VERSION "2021.24.4"

NS_ :

BS_:

BU_: VEH CH Receiver X

BO_ 864 VCLEFT_alertMatrix: 8 VEH
 SG_ VCLEFT_matrixIndex M: 0|4@1+ (1,0) [0|0] "" X
 SG_ VCLEFT_a001_WatchdogReset m0: 4|1@1+ (1,0) [0|0] "" X
 SG_ VCLEFT_a002_PowerLossReset m0: 5|1@1+ (1,0) [0|0] "" X
 SG_ VCLEFT_a003_SWAssertion m0: 6|1@1+ (1,0) [0|0] "" X
 SG_ VCLEFT_a010_ExtSupplyVoltError m0: 13|1@1+ (1,0) [0|0] "" X
 SG_ VCLEFT_a012_CPUReset m0: 15|1@1+ (1,0) [0|0] "" X
 SG_ VCLEFT_a013_AlertManagerFault m0: 16|1@1+ (1,0) [0|0] "" X
 SG_ VCLEFT_a015_NVMMAlert m0: 18|1@1+ (1,0) [0|0] "" X
 SG_ VCLEFT_a021_TaskSchedulerError m0: 24|1@1+ (1,0) [0|0] "" X
 SG_ VCLEFT_a022_TaskInitError m0: 25|1@1+ (1,0) [0|0] "" X
 SG_ VCLEFT_a031_UDSActive m0: 34|1@1+ (1,0) [0|0] "" X
 SG_ VCLEFT_a041_HighCPULoad m0: 44|1@1+ (1,0) [0|0] "" X
 SG_ VCLEFT_a042_HighStackUsage m0: 45|1@1+ (1,0) [0|0] "" X
 SG_ VCLEFT_a043_Task1msError m0: 46|1@1+ (1,0) [0|0] "" X
 SG_ VCLEFT_a044_Task10msError m0: 47|1@1+ (1,0) [0|0] "" X
 SG_ VCLEFT_a045_Task100msError m0: 48|1@1+ (1,0) [0|0] "" X
 SG_ VCLEFT_a046_Task1000msError m0: 49|1@1+ (1,0) [0|0] "" X
 SG_ VCLEFT_a059_inputResistanceHigh m0: 62|1@1+ (1,0) [0|0] "" X
 SG_ VCLEFT_a060_engineeringBuild m0: 63|1@1+ (1,0) [0|0] "" X
 SG_ VCLEFT_a061_XCPConnected m1: 4|1@1+ (1,0) [0|0] "" X
 SG_ VCLEFT_a062_XCPWasConnected m1: 5|1@1+ (1,0) [0|0] "" X
 SG_ VCLEFT_a063_SwitchFault m1: 6|1@1+ (1,0) [0|0] "" X
 SG_ VCLEFT_a064_busSleepReqTimeout m1: 7|1@1+ (1,0) [0|0] "" X
 SG_ VCLEFT_a097_CMP_MIA m1: 40|1@1+ (1,0) [0|0] "" X
 SG_ VCLEFT_a098_DI_THERMAL_MIA m1: 41|1@1+ (1,0) [0|0] "" X
 SG_ VCLEFT_a099_PARK_MIA m1: 42|1@1+ (1,0) [0|0] "" X
 SG_ VCLEFT_a100_CANbus_MIA m1: 43|1@1+ (1,0) [0|0] "" X
 SG_ VCLEFT_a101_PM_MIA m1: 44|1@1+ (1,0) [0|0] "" X
 SG_ VCLEFT_a102_PTC_MIA m1: 45|1@1+ (1,0) [0|0] "" X
 SG_ VCLEFT_a103_CP_MIA m1: 46|1@1+ (1,0) [0|0] "" X
 SG_ VCLEFT_a104_DAS_MIA m1: 47|1@1+ (1,0) [0|0] "" X
 SG_ VCLEFT_a105_TAS_MIA m1: 48|1@1+ (1,0) [0|0] "" X
 SG_ VCLEFT_a106_PCS_MIA m1: 49|1@1+ (1,0) [0|0] "" X
 SG_ VCLEFT_a107_BMS_MIA m1: 50|1@1+ (1,0) [0|0] "" X
 SG_ VCLEFT_a108_DIS_MIA m1: 51|1@1+ (1,0) [0|0] "" X
 SG_ VCLEFT_a109_RCM_MIA m1: 52|1@1+ (1,0) [0|0] "" X
 SG_ VCLEFT_a110_GTW_MIA m1: 53|1@1+ (1,0) [0|0] "" X
 SG_ VCLEFT_a111_EPBR_MIA m1: 54|1@1+ (1,0) [0|0] "" X
 SG_ VCLEFT_a112_EPBL_MIA m1: 55|1@1+ (1,0) [0|0] "" X
 SG_ VCLEFT_a113_UI_MIA m1: 56|1@1+ (1,0) [0|0] "" X
 SG_ VCLEFT_a114_ESP_MIA m1: 57|1@1+ (1,0) [0|0] "" X
 SG_ VCLEFT_a115_VCSEC_MIA m1: 58|1@1+ (1,0) [0|0] "" X
 SG_ VCLEFT_a116_VCRIGHT_MIA m1: 59|1@1+ (1,0) [0|0] "" X
 SG_ VCLEFT_a117_VCLEFT_MIA m1: 60|1@1+ (1,0) [0|0] "" X
 SG_ VCLEFT_a118_VCFRONT_MIA m1: 61|1@1+ (1,0) [0|0] "" X
 SG_ VCLEFT_a119_SCCM_MIA m1: 62|1@1+ (1,0) [0|0] "" X
 SG_ VCLEFT_a120_DI_DRIVE_MIA m1: 63|1@1+ (1,0) [0|0] "" X
 SG_ VCLEFT_a129_blowerICLatchFault m2: 12|1@1+ (1,0) [0|0] "" X
 SG_ VCLEFT_a130_blowerICWarning m2: 13|1@1+ (1,0) [0|0] "" X
 SG_ VCLEFT_a131_blowerICTransFault m2: 14|1@1+ (1,0) [0|0] "" X
 SG_ VCLEFT_a132_blowerSoftStall m2: 15|1@1+ (1,0) [0|0] "" X
 SG_ VCLEFT_a133_blowerLowRPMCBang m2: 16|1@1+ (1,0) [0|0] "" X
 SG_ VCLEFT_a134_SteerColUpDownUnCal m2: 17|1@1+ (1,0) [0|0] "" X
 SG_ VCLEFT_a135_SteerColInOutUnCal m2: 18|1@1+ (1,0) [0|0] "" X
 SG_ VCLEFT_a136_brakeSwitchMismatch m2: 19|1@1+ (1,0) [0|0] "" X
 SG_ VCLEFT_a137_VCSECPowerCycled m2: 20|1@1+ (1,0) [0|0] "" X
 SG_ VCLEFT_a138_consoleDoorAssist m2: 21|1@1+ (1,0) [0|0] "" X
 SG_ VCLEFT_a139_BLERearPowerCycled m2: 22|1@1+ (1,0) [0|0] "" X
 SG_ VCLEFT_a140_BLELeftPowerCycled m2: 23|1@1+ (1,0) [0|0] "" X
 SG_ VCLEFT_a141_12VAuxPowerTrip m2: 24|1@1+ (1,0) [0|0] "" X
 SG_ VCLEFT_a150_windowPinchFront m2: 33|1@1+ (1,0) [0|0] "" X
 SG_ VCLEFT_a151_windowPinchRear m2: 34|1@1+ (1,0) [0|0] "" X
 SG_ VCLEFT_a152_windowUncalFront m2: 35|1@1+ (1,0) [0|0] "" X
 SG_ VCLEFT_a153_windowUncalRear m2: 36|1@1+ (1,0) [0|0] "" X
 SG_ VCLEFT_a154_windowThermalFront m2: 37|1@1+ (1,0) [0|0] "" X
 SG_ VCLEFT_a155_windowThermalRear m2: 38|1@1+ (1,0) [0|0] "" X
 SG_ VCLEFT_a156_windowNoInputFront m2: 39|1@1+ (1,0) [0|0] "" X
 SG_ VCLEFT_a157_windowNoInputRear m2: 40|1@1+ (1,0) [0|0] "" X
 SG_ VCLEFT_a158_windowPinchOverideF m2: 41|1@1+ (1,0) [0|0] "" X
 SG_ VCLEFT_a159_windowPinchOverideR m2: 42|1@1+ (1,0) [0|0] "" X
 SG_ VCLEFT_a160_windowUndercurrentF m2: 43|1@1+ (1,0) [0|0] "" X
 SG_ VCLEFT_a161_windowUndercurrentR m2: 44|1@1+ (1,0) [0|0] "" X
 SG_ VCLEFT_a162_windowEncoderStallF m2: 45|1@1+ (1,0) [0|0] "" X
 SG_ VCLEFT_a163_windowEncoderStallR m2: 46|1@1+ (1,0) [0|0] "" X
 SG_ VCLEFT_a164_windowFactoryTest m2: 47|1@1+ (1,0) [0|0] "" X
 SG_ VCLEFT_a165_windowFactoryTest2 m2: 48|1@1+ (1,0) [0|0] "" X
 SG_ VCLEFT_a166_windowDebug m2: 49|1@1+ (1,0) [0|0] "" X
 SG_ VCLEFT_a167_windowDebugPinchF m2: 50|1@1+ (1,0) [0|0] "" X
 SG_ VCLEFT_a168_windowDebugPinchR m2: 51|1@1+ (1,0) [0|0] "" X
 SG_ VCLEFT_a169_windowCurrentPeakF m2: 52|1@1+ (1,0) [0|0] "" X
 SG_ VCLEFT_a170_windowCurrentPeakR m2: 53|1@1+ (1,0) [0|0] "" X
 SG_ VCLEFT_a172_SPI_MIA m2: 55|1@1+ (1,0) [0|0] "" X
 SG_ VCLEFT_a180_frontDoorLatchRehome m2: 63|1@1+ (1,0) [0|0] "" X
 SG_ VCLEFT_a181_rearDoorLatchRehome m3: 4|1@1+ (1,0) [0|0] "" X
 SG_ VCLEFT_a182_emergencyLatchRel m3: 5|1@1+ (1,0) [0|0] "" X
 SG_ VCLEFT_a183_doorStateFactoryTest m3: 6|1@1+ (1,0) [0|0] "" X
 SG_ VCLEFT_a185_summonAborted m3: 8|1@1+ (1,0) [0|0] "" X
 SG_ VCLEFT_a186_latchReleaseFailedF m3: 9|1@1+ (1,0) [0|0] "" X
 SG_ VCLEFT_a187_latchReleaseFailedR m3: 10|1@1+ (1,0) [0|0] "" X
 SG_ VCLEFT_a188_latchUnableToRearmF m3: 11|1@1+ (1,0) [0|0] "" X
 SG_ VCLEFT_a189_latchUnableToRearmR m3: 12|1@1+ (1,0) [0|0] "" X
 SG_ VCLEFT_a190_eFuseMgmtVbatFused m3: 13|1@1+ (1,0) [0|0] "" X
 SG_ VCLEFT_a191_TLCOvercurrent m3: 14|1@1+ (1,0) [0|0] "" X
 SG_ VCLEFT_a196_VEHCANOverterminate m3: 19|1@1+ (1,0) [0|0] "" X
 SG_ VCLEFT_a197_VEHCANUndertrminate m3: 20|1@1+ (1,0) [0|0] "" X
 SG_ VCLEFT_a200_motorPhantomEncoder m3: 23|1@1+ (1,0) [0|0] "" X
 SG_ VCLEFT_a201_motorDutyEncDisabl m3: 24|1@1+ (1,0) [0|0] "" X
 SG_ VCLEFT_a202_epbmUnderIStatic m3: 25|1@1+ (1,0) [0|0] "" X
 SG_ VCLEFT_a203_epbmOverIStatic m3: 26|1@1+ (1,0) [0|0] "" X
 SG_ VCLEFT_a204_epbmUnderIDyn m3: 27|1@1+ (1,0) [0|0] "" X
 SG_ VCLEFT_a205_epbmOverIDyn m3: 28|1@1+ (1,0) [0|0] "" X
 SG_ VCLEFT_a206_epbWrongDirection m3: 29|1@1+ (1,0) [0|0] "" X
 SG_ VCLEFT_a207_epbmEnableWrong m3: 30|1@1+ (1,0) [0|0] "" X
 SG_ VCLEFT_a208_epbFaulted m3: 31|1@1+ (1,0) [0|0] "" X
 SG_ VCLEFT_a209_epbStateMisTime m3: 32|1@1+ (1,0) [0|0] "" X
 SG_ VCLEFT_a210_epbStateTime m3: 33|1@1+ (1,0) [0|0] "" X
 SG_ VCLEFT_a211_epbmUnderIStaticNew m3: 34|1@1+ (1,0) [0|0] "" X
 SG_ VCLEFT_a212_epbmOverIStaticNew m3: 35|1@1+ (1,0) [0|0] "" X
 SG_ VCLEFT_a213_epbmUnderIDynNew m3: 36|1@1+ (1,0) [0|0] "" X
 SG_ VCLEFT_a214_epbmOverIDynNew m3: 37|1@1+ (1,0) [0|0] "" X
 SG_ VCLEFT_a215_currentDesyncWarning m3: 38|1@1+ (1,0) [0|0] "" X
 SG_ VCLEFT_a216_SPI_MIA_debugData1 m3: 39|1@1+ (1,0) [0|0] "" X
 SG_ VCLEFT_a217_SPI_MIA_debugData2 m3: 40|1@1+ (1,0) [0|0] "" X
 SG_ VCLEFT_a218_motorDriverFault m3: 41|1@1+ (1,0) [0|0] "" X
 SG_ VCLEFT_a219_motorCurrentDropout m3: 42|1@1+ (1,0) [0|0] "" X
 SG_ VCLEFT_a220_seatCurrStallTrack m3: 43|1@1+ (1,0) [0|0] "" X
 SG_ VCLEFT_a221_seatCurrStallBack m3: 44|1@1+ (1,0) [0|0] "" X
 SG_ VCLEFT_a222_seatCurrStallTilt m3: 45|1@1+ (1,0) [0|0] "" X
 SG_ VCLEFT_a223_seatCurrStallLift m3: 46|1@1+ (1,0) [0|0] "" X
 SG_ VCLEFT_a224_seatEncStallTrack m3: 47|1@1+ (1,0) [0|0] "" X
 SG_ VCLEFT_a225_seatEncStallBack m3: 48|1@1+ (1,0) [0|0] "" X
 SG_ VCLEFT_a226_seatEncStallTilt m3: 49|1@1+ (1,0) [0|0] "" X
 SG_ VCLEFT_a227_seatEncStallLift m3: 50|1@1+ (1,0) [0|0] "" X
 SG_ VCLEFT_a228_seatEncOverTrack m3: 51|1@1+ (1,0) [0|0] "" X
 SG_ VCLEFT_a229_seatEncOverBack m3: 52|1@1+ (1,0) [0|0] "" X
 SG_ VCLEFT_a230_seatEncOverTilt m3: 53|1@1+ (1,0) [0|0] "" X
 SG_ VCLEFT_a231_seatEncOverLift m3: 54|1@1+ (1,0) [0|0] "" X
 SG_ VCLEFT_a232_seatCurrUnderTrack m3: 55|1@1+ (1,0) [0|0] "" X
 SG_ VCLEFT_a233_seatCurrUnderBack m3: 56|1@1+ (1,0) [0|0] "" X
 SG_ VCLEFT_a234_seatCurrUnderTilt m3: 57|1@1+ (1,0) [0|0] "" X
 SG_ VCLEFT_a235_seatCurrUnderLift m3: 58|1@1+ (1,0) [0|0] "" X
 SG_ VCLEFT_a236_lumbarOverPresA m3: 59|1@1+ (1,0) [0|0] "" X
 SG_ VCLEFT_a237_lumbarOverPresB m3: 60|1@1+ (1,0) [0|0] "" X
 SG_ VCLEFT_a238_lumbarValveMIA m3: 61|1@1+ (1,0) [0|0] "" X
 SG_ VCLEFT_a239_seatHeatIFront m3: 62|1@1+ (1,0) [0|0] "" X
 SG_ VCLEFT_a240_seatHeatShortFront m3: 63|1@1+ (1,0) [0|0] "" X
 SG_ VCLEFT_a241_seatHeatMIAFront m4: 4|1@1+ (1,0) [0|0] "" X
 SG_ VCLEFT_a242_seatHeatIRearL m4: 5|1@1+ (1,0) [0|0] "" X
 SG_ VCLEFT_a243_seatHeatShortRearL m4: 6|1@1+ (1,0) [0|0] "" X
 SG_ VCLEFT_a244_seatHeatMIARearL m4: 7|1@1+ (1,0) [0|0] "" X
 SG_ VCLEFT_a251_seatUncalTrack m4: 14|1@1+ (1,0) [0|0] "" X
 SG_ VCLEFT_a252_seatUncalBack m4: 15|1@1+ (1,0) [0|0] "" X
 SG_ VCLEFT_a253_seatUncalTilt m4: 16|1@1+ (1,0) [0|0] "" X
 SG_ VCLEFT_a254_seatUncalLift m4: 17|1@1+ (1,0) [0|0] "" X
 SG_ VCLEFT_a259_latchDisarmDelayF m4: 22|1@1+ (1,0) [0|0] "" X
 SG_ VCLEFT_a260_latchDisarmDelayR m4: 23|1@1+ (1,0) [0|0] "" X
 SG_ VCLEFT_a263_seatTrackStallDebug m4: 26|1@1+ (1,0) [0|0] "" X
 SG_ VCLEFT_a264_seatBackStallDebug m4: 27|1@1+ (1,0) [0|0] "" X
 SG_ VCLEFT_a265_seatTiltStallDebug m4: 28|1@1+ (1,0) [0|0] "" X
 SG_ VCLEFT_a266_seatLiftStallDebug m4: 29|1@1+ (1,0) [0|0] "" X
 SG_ VCLEFT_a267_seatTrackHCEncStlDbg m4: 30|1@1+ (1,0) [0|0] "" X
 SG_ VCLEFT_a268_seatBackHCEncStlDbg m4: 31|1@1+ (1,0) [0|0] "" X
 SG_ VCLEFT_a269_seatTiltHCEncStlDbg m4: 32|1@1+ (1,0) [0|0] "" X
 SG_ VCLEFT_a270_seatLiftHCEncStlDbg m4: 33|1@1+ (1,0) [0|0] "" X
 SG_ VCLEFT_a272_vhclPwrStateMsmtch m4: 35|1@1+ (1,0) [0|0] "" X
 SG_ VCLEFT_a273_handleStuckActiveF m4: 36|1@1+ (1,0) [0|0] "" X
 SG_ VCLEFT_a274_handleStuckActiveR m4: 37|1@1+ (1,0) [0|0] "" X
 SG_ VCLEFT_a275_leftTurnLightFault m4: 38|1@1+ (1,0) [0|0] "" X
 SG_ VCLEFT_a276_mirrorDebug m4: 39|1@1+ (1,0) [0|0] "" X
 SG_ VCLEFT_a277_BLELeftUnderVoltage m4: 40|1@1+ (1,0) [0|0] "" X
 SG_ VCLEFT_a278_BLERearUnderVoltage m4: 41|1@1+ (1,0) [0|0] "" X
 SG_ VCLEFT_a279_VCSECUnderVoltage m4: 42|1@1+ (1,0) [0|0] "" X
 SG_ VCLEFT_a280_latchDidNotDisarmF m4: 43|1@1+ (1,0) [0|0] "" X
 SG_ VCLEFT_a281_latchDidNotDisarmR m4: 44|1@1+ (1,0) [0|0] "" X
 SG_ VCLEFT_a282_latchUnexpectedArmF m4: 45|1@1+ (1,0) [0|0] "" X
 SG_ VCLEFT_a283_latchUnexpectedArmR m4: 46|1@1+ (1,0) [0|0] "" X
 SG_ VCLEFT_a284_blowerFbkSanity m4: 47|1@1+ (1,0) [0|0] "" X
 SG_ VCLEFT_a285_blowerChipComms m4: 48|1@1+ (1,0) [0|0] "" X
 SG_ VCLEFT_a286_windowSpeedInvalidF m4: 49|1@1+ (1,0) [0|0] "" X
 SG_ VCLEFT_a287_windowSpeedInvalidR m4: 50|1@1+ (1,0) [0|0] "" X
 SG_ VCLEFT_a290_occupancyFaultedFront m4: 53|1@1+ (1,0) [0|0] "" X
 SG_ VCLEFT_a291_buckleFaultedFront m4: 54|1@1+ (1,0) [0|0] "" X
 SG_ VCLEFT_a292_occupancyFaultedRearL m4: 55|1@1+ (1,0) [0|0] "" X
 SG_ VCLEFT_a293_occupancyFaultedRearC m4: 56|1@1+ (1,0) [0|0] "" X
 SG_ VCLEFT_a294_occupancyFaultedRearR m4: 57|1@1+ (1,0) [0|0] "" X
 SG_ VCLEFT_a295_buckleFaultedRearL m4: 58|1@1+ (1,0) [0|0] "" X
 SG_ VCLEFT_a300_swcUnderVoltage m4: 63|1@1+ (1,0) [0|0] "" X
 SG_ VCLEFT_a301_swcOverVoltage m5: 4|1@1+ (1,0) [0|0] "" X
 SG_ VCLEFT_a302_blowerGeneralFault m5: 5|1@1+ (1,0) [0|0] "" X
 SG_ VCLEFT_a303_eFuseMgmtWindowLift m5: 6|1@1+ (1,0) [0|0] "" X
 SG_ VCLEFT_a304_frontIntHandleShorted m5: 7|1@1+ (1,0) [0|0] "" X
 SG_ VCLEFT_a305_rearIntHandleShorted m5: 8|1@1+ (1,0) [0|0] "" X
 SG_ VCLEFT_a306_handleDisconnectedF m5: 9|1@1+ (1,0) [0|0] "" X
 SG_ VCLEFT_a307_handleDisconnectedR m5: 10|1@1+ (1,0) [0|0] "" X

BO_ 258 VCLEFT_doorStatus: 8 VEH
 SG_ VCLEFT_frontHandlePWM: 16|7@1+ (1,0) [0|0] "%" X
 SG_ VCLEFT_frontHandlePulled: 10|1@1+ (1,0) [0|0] "" X
 SG_ VCLEFT_frontHandlePulledPersist: 62|1@1+ (1,0) [0|0] "" X
 SG_ VCLEFT_frontIntSwitchPressed: 31|1@1+ (1,0) [0|0] "" X
 SG_ VCLEFT_frontLatchStatus: 0|4@1+ (1,0) [0|0] "" X
 SG_ VCLEFT_frontLatchSwitch: 8|1@1+ (1,0) [0|0] "" X
 SG_ VCLEFT_frontRelActuatorSwitch: 12|1@1+ (1,0) [0|0] "" X
 SG_ VCLEFT_mirrorDipped: 61|1@1+ (1,0) [0|0] "" X
 SG_ VCLEFT_mirrorFoldState: 52|3@1+ (1,0) [0|0] "" X
 SG_ VCLEFT_mirrorHeatState: 58|3@1+ (1,0) [0|0] "" X
 SG_ VCLEFT_mirrorRecallState: 55|3@1+ (1,0) [0|0] "" X
 SG_ VCLEFT_mirrorState: 49|3@1+ (1,0) [0|0] "" X
 SG_ VCLEFT_mirrorTiltXPosition: 33|8@1+ (0.02,0) [0|0] "V" X
 SG_ VCLEFT_mirrorTiltYPosition: 41|8@1+ (0.02,0) [0|0] "V" X
 SG_ VCLEFT_rearHandlePWM: 24|7@1+ (1,0) [0|0] "%" X
 SG_ VCLEFT_rearHandlePulled: 11|1@1+ (1,0) [0|0] "" X
 SG_ VCLEFT_rearIntSwitchPressed: 32|1@1+ (1,0) [0|0] "" X
 SG_ VCLEFT_rearLatchStatus: 4|4@1+ (1,0) [0|0] "" X
 SG_ VCLEFT_rearLatchSwitch: 9|1@1+ (1,0) [0|0] "" X
 SG_ VCLEFT_rearRelActuatorSwitch: 13|1@1+ (1,0) [0|0] "" X

BO_ 626 VCLEFT_epbmDebug: 8 VEH
 SG_ VCLEFT_epbmDebugIndex M: 0|1@1+ (1,0) [0|0] "" X
 SG_ VCLEFT_epbmCaliperState m0: 1|3@1+ (1,0) [0|0] "" X
 SG_ VCLEFT_epbmMotorEnabled m0: 4|1@1+ (1,0) [0|0] "" X
 SG_ VCLEFT_epbMotorCurrent m0: 5|11@1+ (0.01,0) [0|0] "A" X
 SG_ VCLEFT_epbmApplyVoltage m0: 16|11@1+ (0.01,0) [0|0] "A" X
 SG_ VCLEFT_epbmReleaseVoltage m0: 27|11@1+ (0.01,0) [0|0] "A" X
 SG_ VCLEFT_summonFaultReason m0: 38|5@1+ (1,0) [0|0] "" X
 SG_ VCLEFT_epbSummonState m0: 43|3@1+ (1,0) [0|0] "" X
 SG_ VCLEFT_epbmSummonState m0: 46|3@1+ (1,0) [0|0] "" X
 SG_ VCLEFT_epbmUnitStatus m0: 49|5@1+ (1,0) [0|0] "" X
 SG_ VCLEFT_epbUnitStatus m0: 54|5@1+ (1,0) [0|0] "" X
 SG_ VCLEFT_epbmFaultStatus m0: 59|2@1+ (1,0) [0|0] "" X
 SG_ VCLEFT_epbFaultStatus m0: 61|2@1+ (1,0) [0|0] "" X
 SG_ VCLEFT_epbmOpenAllowed m1: 1|1@1+ (1,0) [0|0] "" X
 SG_ VCLEFT_epbmDynamicAllowed m1: 2|1@1+ (1,0) [0|0] "" X
 SG_ VCLEFT_epbmParkAllowed m1: 3|1@1+ (1,0) [0|0] "" X
 SG_ VCLEFT_epbmStartAllowed m1: 4|1@1+ (1,0) [0|0] "" X
 SG_ VCLEFT_epbmServiceAllowed m1: 5|1@1+ (1,0) [0|0] "" X
 SG_ VCLEFT_epbmWinchAllowed m1: 6|1@1+ (1,0) [0|0] "" X
 SG_ VCLEFT_epbmWinchReleaseAllowed m1: 7|1@1+ (1,0) [0|0] "" X
 SG_ VCLEFT_epbmParkingAllowed m1: 8|1@1+ (1,0) [0|0] "" X
 SG_ VCLEFT_epbmDynApplyingAllowed m1: 9|1@1+ (1,0) [0|0] "" X
 SG_ VCLEFT_epbmReleasingAllowed m1: 10|1@1+ (1,0) [0|0] "" X
 SG_ VCLEFT_epbmFaultAllowed m1: 11|1@1+ (1,0) [0|0] "" X
 SG_ VCLEFT_epbmSummonAllowed m1: 12|1@1+ (1,0) [0|0] "" X
 SG_ VCLEFT_epbmSummonParkAllowed m1: 13|1@1+ (1,0) [0|0] "" X
 SG_ VCLEFT_epbmSummonReleaseAllowed m1: 14|1@1+ (1,0) [0|0] "" X
 SG_ VCLEFT_summonInitAllowed m1: 15|1@1+ (1,0) [0|0] "" X
 SG_ VCLEFT_epbmUnknownAllowed m1: 16|1@1+ (1,0) [0|0] "" X
 SG_ VCLEFT_summonIdleAllowed m1: 17|1@1+ (1,0) [0|0] "" X
 SG_ VCLEFT_summonArmedAllowed m1: 18|1@1+ (1,0) [0|0] "" X
 SG_ VCLEFT_summonActiveAllowed m1: 19|1@1+ (1,0) [0|0] "" X
 SG_ VCLEFT_summonCompleteAllowed m1: 20|1@1+ (1,0) [0|0] "" X
 SG_ VCLEFT_summonFaultAllowed m1: 21|1@1+ (1,0) [0|0] "" X
 SG_ VCLEFT_summonUnavailableAllowed m1: 22|1@1+ (1,0) [0|0] "" X
 SG_ VCLEFT_cdpEnumDummy m1: 24|2@1+ (1,0) [0|0] "" X

BO_ 642 VCLEFT_hvacBlowerFeedback: 8 VEH
 SG_ VCLEFT_blowerIndex M: 0|2@1+ (1,0) [0|0] "" X
 SG_ VCLEFT_hvacBlowerEnabled m0: 2|1@1+ (1,0) [0|0] "" X
 SG_ VCLEFT_hvacBlowerOutputDuty m0: 3|7@1+ (1,0) [0|0] "%" X
 SG_ VCLEFT_hvacBlowerRPMTarget m0: 10|10@1+ (10,0) [0|0] "rpm" X
 SG_ VCLEFT_hvacBlowerRPMActual m0: 20|10@1+ (10,0) [0|0] "rpm" X
 SG_ VCLEFT_hvacBlowerTorque m0: 34|8@1- (0.025,-1.5) [0|0] "Nm" X
 SG_ VCLEFT_hvacBlowerFETTemp m0: 42|8@1+ (1,-40) [0|0] "degC" X
 SG_ VCLEFT_hvacBlowerITerm m0: 50|8@1+ (0.025,-1.5) [0|0] "Nm" X
 SG_ VCLEFT_hvacBlowerInitd m0: 58|1@1+ (1,0) [0|0] "" X
 SG_ VCLEFT_hvacBlowerFault m0: 59|1@1+ (1,0) [0|0] "" X
 SG_ VCLEFT_hvacBlowerLimitFETTemps m0: 60|1@1+ (1,0) [0|0] "" X
 SG_ VCLEFT_hvacBlowerPowerOn m0: 61|1@1+ (1,0) [0|0] "" X
 SG_ VCLEFT_hvacBlowerSpiError m0: 62|1@1+ (1,0) [0|0] "" X
 SG_ VCLEFT_hvacBlowerRs m1: 2|8@1+ (0.0025,0) [0|0] "Ohm" X
 SG_ VCLEFT_hvacBlowerIPhase0 m1: 10|8@1+ (0.2,0) [0|0] "A" X
 SG_ VCLEFT_hvacBlowerIPhase1 m1: 18|8@1+ (0.2,0) [0|0] "A" X
 SG_ VCLEFT_hvacBlowerIPhase2 m1: 26|8@1+ (0.2,0) [0|0] "A" X

BO_ 770 VCLEFT_info: 8 VEH
 SG_ VCLEFT_infoIndex M: 0|8@1+ (1,0) [0|0] "" X
 SG_ VCLEFT_infoBuildType m10: 8|3@1+ (1,0) [0|0] "" X
 SG_ VCLEFT_infoBuildConfigId m10: 16|16@1+ (1,0) [0|0] "" X
 SG_ VCLEFT_infoHardwareId m10: 32|16@1+ (1,0) [0|0] "" X
 SG_ VCLEFT_infoComponentId m10: 48|16@1+ (1,0) [0|0] "" X
 SG_ VCLEFT_infoPcbaId m11: 8|8@1+ (1,0) [0|0] "" X
 SG_ VCLEFT_infoAssemblyId m11: 16|8@1+ (1,0) [0|0] "" X
 SG_ VCLEFT_infoUsageId m11: 24|16@1+ (1,0) [0|0] "" X
 SG_ VCLEFT_infoSubUsageId m11: 40|16@1+ (1,0) [0|0] "" X
 SG_ VCLEFT_infoAppCrc m13: 8|32@1+ (1,0) [0|0] "" X
 SG_ VCLEFT_infoSubcomponent1 m16: 32|32@1+ (1,0) [0|0] "" X
 SG_ VCLEFT_infoAppGitHash m17: 10|54@1+ (4,0) [0|0] "" X
 SG_ VCLEFT_infoBootGitHash m18: 10|54@1+ (4,0) [0|0] "" X
 SG_ VCLEFT_infoPlatformType m19: 8|8@1+ (1,0) [0|0] "" X
 SG_ VCLEFT_infoBootUdsProtoVersion m20: 8|16@1+ (1,0) [0|0] "" X
 SG_ VCLEFT_infoBootCrc m20: 24|32@1+ (1,0) [0|0] "" X
 SG_ VCLEFT_swcAppCRC m23: 32|32@1+ (1,0) [0|0] "" X
 SG_ VCLEFT_infoSubcomponent3 m24: 32|32@1+ (1,0) [0|0] "" X
 SG_ VCLEFT_infoCBCAppCRC m31: 32|32@1+ (1,0) [0|0] "" X

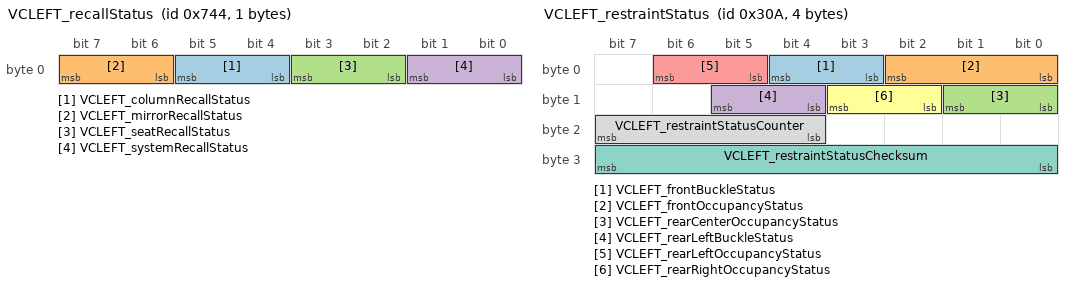
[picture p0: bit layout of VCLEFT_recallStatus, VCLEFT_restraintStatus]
BO_ 1860 VCLEFT_recallStatus: 1 VEH
 SG_ VCLEFT_columnRecallStatus: 4|2@1+ (1,0) [0|0] "" X
 SG_ VCLEFT_mirrorRecallStatus: 6|2@1+ (1,0) [0|0] "" X
 SG_ VCLEFT_seatRecallStatus: 2|2@1+ (1,0) [0|0] "" X
 SG_ VCLEFT_systemRecallStatus: 0|2@1+ (1,0) [0|0] "" X

BO_ 778 VCLEFT_restraintStatus: 4 VEH
 SG_ VCLEFT_frontBuckleStatus: 3|2@1+ (1,0) [0|0] "" X
 SG_ VCLEFT_frontOccupancyStatus: 0|3@1+ (1,0) [0|0] "" X
 SG_ VCLEFT_rearCenterOccupancyStatus: 8|2@1+ (1,0) [0|0] "" X
 SG_ VCLEFT_rearLeftBuckleStatus: 12|2@1+ (1,0) [0|0] "" X
 SG_ VCLEFT_rearLeftOccupancyStatus: 5|2@1+ (1,0) [0|0] "" X
 SG_ VCLEFT_rearRightOccupancyStatus: 10|2@1+ (1,0) [0|0] "" X
 SG_ VCLEFT_restraintStatusChecksum: 24|8@1+ (1,0) [0|0] "" X
 SG_ VCLEFT_restraintStatusCounter: 20|4@1+ (1,0) [0|0] "" X

BO_ 1250 VCLEFT_seatStatus: 8 VEH
 SG_ VCLEFT_seatStatusIndex M: 0|3@1+ (1,0) [0|0] "" X
 SG_ VCLEFT_frontSeatTrackPos m0: 8|16@1- (1,0) [0|0] "" X
 SG_ VCLEFT_frontSeatTrackCurrent m0: 24|12@1- (0.01,0) [0|0] "A" X
 SG_ VCLEFT_frontSeatTrackDuty m0: 36|12@1- (0.1,0) [0|0] "%" X
 SG_ VCLEFT_frontSeatTrackState m0: 48|3@1+ (1,0) [0|0] "" X
 SG_ VCLEFT_frontSeatTrackCalibrated m0: 51|1@1+ (1,0) [0|0] "" X
 SG_ VCLEFT_frontSeatTrackLog m0: 52|1@1+ (1,0) [0|0] "" X
 SG_ VCLEFT_frontSeatBackPos m1: 8|16@1- (1,0) [0|0] "" X
 SG_ VCLEFT_frontSeatBackCurrent m1: 24|12@1- (0.01,0) [0|0] "A" X
 SG_ VCLEFT_frontSeatBackDuty m1: 36|12@1- (0.1,0) [0|0] "%" X
 SG_ VCLEFT_frontSeatBackState m1: 48|3@1+ (1,0) [0|0] "" X
 SG_ VCLEFT_frontSeatBackCalibrated m1: 51|1@1+ (1,0) [0|0] "" X
 SG_ VCLEFT_frontSeatBackLog m1: 52|1@1+ (1,0) [0|0] "" X
 SG_ VCLEFT_frontSeatLiftPos m2: 8|16@1- (1,0) [0|0] "" X
 SG_ VCLEFT_frontSeatLiftCurrent m2: 24|12@1- (0.01,0) [0|0] "A" X
 SG_ VCLEFT_frontSeatLiftDuty m2: 36|12@1- (0.1,0) [0|0] "%" X
 SG_ VCLEFT_frontSeatLiftState m2: 48|3@1+ (1,0) [0|0] "" X
 SG_ VCLEFT_frontSeatLiftCalibrated m2: 51|1@1+ (1,0) [0|0] "" X
 SG_ VCLEFT_frontSeatLiftLog m2: 52|1@1+ (1,0) [0|0] "" X
 SG_ VCLEFT_frontSeatTiltPos m3: 8|16@1- (1,0) [0|0] "" X
 SG_ VCLEFT_frontSeatTiltCurrent m3: 24|12@1- (0.01,0) [0|0] "A" X
 SG_ VCLEFT_frontSeatTiltDuty m3: 36|12@1- (0.1,0) [0|0] "%" X
 SG_ VCLEFT_frontSeatTiltState m3: 48|3@1+ (1,0) [0|0] "" X
 SG_ VCLEFT_frontSeatTiltCalibrated m3: 51|1@1+ (1,0) [0|0] "" X
 SG_ VCLEFT_frontSeatTiltLog m3: 52|1@1+ (1,0) [0|0] "" X
 SG_ VCLEFT_lumbarAState m4: 3|3@1+ (1,0) [0|0] "" X
 SG_ VCLEFT_lumbarBState m4: 8|3@1+ (1,0) [0|0] "" X
 SG_ VCLEFT_lumbarAPressureHpa m4: 16|16@1+ (1,0) [0|0] "" X
 SG_ VCLEFT_lumbarBPressureHpa m4: 32|16@1+ (1,0) [0|0] "" X
 SG_ VCLEFT_lumbarActiveTooLongErr m4: 48|1@1+ (1,0) [0|0] "" X
 SG_ VCLEFT_lumbarMaxPErr m4: 49|1@1+ (1,0) [0|0] "" X
 SG_ VCLEFT_lumbarOvercurrentErr m4: 50|1@1+ (1,0) [0|0] "" X
 SG_ VCLEFT_lumbarMaxOperatingPErr m4: 51|1@1+ (1,0) [0|0] "" X
 SG_ VCLEFT_lumbarMinPErr m4: 52|1@1+ (1,0) [0|0] "" X
 SG_ VCLEFT_lumbarGeneralErr m4: 53|1@1+ (1,0) [0|0] "" X
 SG_ VCLEFT_lumbarDevMaxPumpPressA m4: 54|1@1+ (1,0) [0|0] "" X
 SG_ VCLEFT_lumbarDevMaxPumpPressB m4: 55|1@1+ (1,0) [0|0] "" X
 SG_ VCLEFT_frontSeatTrackPosReal m5: 3|12@1- (1,0) [0|0] "mm" X
 SG_ VCLEFT_frontSeatBackPosReal m5: 16|12@1- (0.1,0) [0|0] "deg" X
 SG_ VCLEFT_frontSeatLiftPosReal m5: 28|12@1- (1,0) [0|0] "mm" X
 SG_ VCLEFT_frontSeatTiltPosReal m5: 40|12@1- (0.1,0) [0|0] "deg" X

BO_ 930 VCLEFT_status: 8 VEH
 SG_ VCLEFT_statusIndex M: 0|1@1+ (1,0) [0|0] "" X
 SG_ VCLEFT_loadShedPriority m0: 1|8@1+ (1,0) [0|0] "" X
 SG_ VCLEFT_vehiclePowerStateDBG m0: 9|2@1+ (1,0) [0|0] "" X
 SG_ VCLEFT_consoleDoorAssist m0: 11|1@1+ (1,0) [0|0] "" X
 SG_ VCLEFT_OTAState m0: 12|1@1+ (1,0) [0|0] "" X
 SG_ VCLEFT_5AVoltage m0: 13|10@1+ (0.00544368,0) [0|0] "V" X
 SG_ VCLEFT_vbatProt m0: 23|12@1+ (0.00544368,0) [0|0] "V" X
 SG_ VCLEFT_footwellLightCurrent m0: 35|12@1- (0.1,0) [0|0] "mA" X
 SG_ VCLEFT_swcInputVoltage m0: 47|8@1+ (0.1,0) [0|0] "V" X
 SG_ VCLEFT_swcPCBATemperature m0: 55|8@1- (1,-40) [0|0] "degC" X
 SG_ VCLEFT_pcbaTemperature m1: 1|11@1+ (0.125,-40) [0|0] "degC" X
 SG_ VCLEFT_DIeFuseCurrent m1: 12|12@1- (0.1,0) [0|0] "A" X
 SG_ VCLEFT_DIeFuseFault m1: 24|1@1+ (1,0) [0|0] "" X
 SG_ VCLEFT_tlcPCBATemperature m1: 32|8@1- (1,-40) [0|0] "degC" X

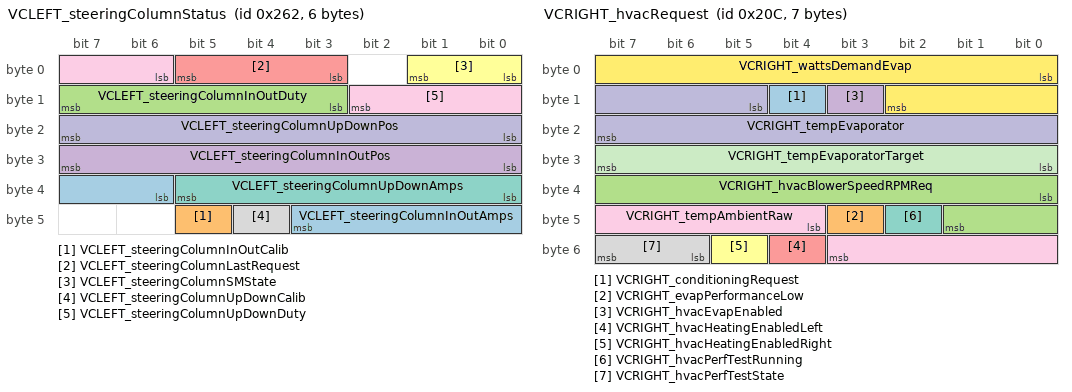
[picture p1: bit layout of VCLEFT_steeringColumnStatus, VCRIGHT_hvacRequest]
BO_ 610 VCLEFT_steeringColumnStatus: 6 VEH
 SG_ VCLEFT_steeringColumnInOutAmps: 38|6@1- (0.63,0) [0|0] "A" X
 SG_ VCLEFT_steeringColumnInOutCalib: 45|1@1+ (1,0) [0|0] "" X
 SG_ VCLEFT_steeringColumnInOutDuty: 11|5@1- (7,0) [0|0] "%" X
 SG_ VCLEFT_steeringColumnInOutPos: 24|8@1- (12,1284) [0|0] "ticks" X
 SG_ VCLEFT_steeringColumnLastRequest: 3|3@1+ (1,0) [0|0] "" X
 SG_ VCLEFT_steeringColumnSMState: 0|2@1+ (1,0) [0|0] "" X
 SG_ VCLEFT_steeringColumnUpDownAmps: 32|6@1- (0.63,0) [0|0] "A" X
 SG_ VCLEFT_steeringColumnUpDownCalib: 44|1@1+ (1,0) [0|0] "" X
 SG_ VCLEFT_steeringColumnUpDownDuty: 6|5@1- (7,0) [0|0] "%" X
 SG_ VCLEFT_steeringColumnUpDownPos: 16|8@1- (12,1284) [0|0] "ticks" X

BO_ 962 VCLEFT_switchStatus: 8 VEH
 SG_ VCLEFT_switchStatusIndex M : 0|2@1+ (1,0) [0|2] "" X
 SG_ VCLEFT_2RowSeatBothFoldFlatSwitc m1 : 40|1@1+ (1,0) [0|1] "" X
 SG_ VCLEFT_2RowSeatCenterSwitch m1 : 37|1@1+ (1,0) [0|1] "" X
 SG_ VCLEFT_2RowSeatLeftFoldFlatSwitc m1 : 38|1@1+ (1,0) [0|1] "" X
 SG_ VCLEFT_2RowSeatReclineSwitch m1 : 36|1@1+ (1,0) [0|1] "" X
 SG_ VCLEFT_2RowSeatRightFoldFlatSwit m1 : 39|1@1+ (1,0) [0|1] "" X
 SG_ VCLEFT_brakePressed m0 : 60|1@1+ (1,0) [0|1] "" X
 SG_ VCLEFT_brakeSwitchPressed m0 : 4|1@1+ (1,0) [0|1] "" X
 SG_ VCLEFT_btnWindowAutoDownLR m1 : 35|1@1+ (1,0) [0|1] "" X
 SG_ VCLEFT_btnWindowAutoUpLR m1 : 33|1@1+ (1,0) [0|1] "" X
 SG_ VCLEFT_btnWindowDownLR m1 : 34|1@1+ (1,0) [0|1] "" X
 SG_ VCLEFT_btnWindowSwPackAutoDownLF m0 : 35|1@1+ (1,0) [0|1] "" X
 SG_ VCLEFT_btnWindowSwPackAutoDownLR m0 : 39|1@1+ (1,0) [0|1] "" X
 SG_ VCLEFT_btnWindowSwPackAutoDownRF m0 : 43|1@1+ (1,0) [0|1] "" X
 SG_ VCLEFT_btnWindowSwPackAutoDownRR m0 : 47|1@1+ (1,0) [0|1] "" X
 SG_ VCLEFT_btnWindowSwPackAutoUpLF m0 : 33|1@1+ (1,0) [0|1] "" X
 SG_ VCLEFT_btnWindowSwPackAutoUpLR m0 : 37|1@1+ (1,0) [0|1] "" X
 SG_ VCLEFT_btnWindowSwPackAutoUpRF m0 : 41|1@1+ (1,0) [0|1] "" X
 SG_ VCLEFT_btnWindowSwPackAutoUpRR m0 : 45|1@1+ (1,0) [0|1] "" X
 SG_ VCLEFT_btnWindowSwPackDownLF m0 : 34|1@1+ (1,0) [0|1] "" X
 SG_ VCLEFT_btnWindowSwPackDownLR m0 : 38|1@1+ (1,0) [0|1] "" X
 SG_ VCLEFT_btnWindowSwPackDownRF m0 : 42|1@1+ (1,0) [0|1] "" X
 SG_ VCLEFT_btnWindowSwPackDownRR m0 : 46|1@1+ (1,0) [0|1] "" X
 SG_ VCLEFT_btnWindowSwPackUpLF m0 : 32|1@1+ (1,0) [0|1] "" X
 SG_ VCLEFT_btnWindowSwPackUpLR m0 : 36|1@1+ (1,0) [0|1] "" X
 SG_ VCLEFT_btnWindowSwPackUpRF m0 : 40|1@1+ (1,0) [0|1] "" X
 SG_ VCLEFT_btnWindowSwPackUpRR m0 : 44|1@1+ (1,0) [0|1] "" X
 SG_ VCLEFT_btnWindowUpLR m1 : 32|1@1+ (1,0) [0|1] "" X
 SG_ VCLEFT_frontBuckleSwitch m0 : 48|2@1+ (1,0) [0|3] "" X
 SG_ VCLEFT_frontOccupancySwitch m0 : 50|2@1+ (1,0) [0|3] "" X
 SG_ VCLEFT_frontSeatBackrestBack m0 : 20|2@1+ (1,0) [0|3] "" X
 SG_ VCLEFT_frontSeatBackrestForward m0 : 22|2@1+ (1,0) [0|3] "" X
 SG_ VCLEFT_frontSeatLiftDown m0 : 16|2@1+ (1,0) [0|3] "" X
 SG_ VCLEFT_frontSeatLiftUp m0 : 18|2@1+ (1,0) [0|3] "" X
 SG_ VCLEFT_frontSeatLumbarDown m0 : 24|2@1+ (1,0) [0|3] "" X
 SG_ VCLEFT_frontSeatLumbarIn m0 : 28|2@1+ (1,0) [0|3] "" X
 SG_ VCLEFT_frontSeatLumbarOut m0 : 30|2@1+ (1,0) [0|3] "" X
 SG_ VCLEFT_frontSeatLumbarUp m0 : 26|2@1+ (1,0) [0|3] "" X
 SG_ VCLEFT_frontSeatTiltDown m0 : 12|2@1+ (1,0) [0|3] "" X
 SG_ VCLEFT_frontSeatTiltUp m0 : 14|2@1+ (1,0) [0|3] "" X
 SG_ VCLEFT_frontSeatTrackBack m0 : 8|2@1+ (1,0) [0|3] "" X
 SG_ VCLEFT_frontSeatTrackForward m0 : 10|2@1+ (1,0) [0|3] "" X
 SG_ VCLEFT_hazardButtonPressed m0 : 3|1@1+ (1,0) [0|1] "" X
 SG_ VCLEFT_hornSwitchPressed m0 : 2|1@1+ (1,0) [0|1] "" X
 SG_ VCLEFT_rearCenterBuckleSwitch m0 : 62|2@1+ (1,0) [0|3] "" X
 SG_ VCLEFT_rearCenterOccupancySwitch m0 : 54|2@1+ (1,0) [0|3] "" X
 SG_ VCLEFT_rearHVACButtonPressed m0 : 61|1@1+ (1,0) [0|1] "" X
 SG_ VCLEFT_rearLeftBuckleSwitch m0 : 52|2@1+ (1,0) [0|3] "" X
 SG_ VCLEFT_rearLeftOccupancySwitch m0 : 56|2@1+ (1,0) [0|3] "" X
 SG_ VCLEFT_rearRightOccupancySwitch m0 : 58|2@1+ (1,0) [0|3] "" X
 SG_ VCLEFT_rightMirrorTilt m0 : 5|3@1+ (1,0) [0|4] "" X
 SG_ VCLEFT_swcLeftDoublePress m1 : 41|1@1+ (1,0) [0|1] "" X
 SG_ VCLEFT_swcLeftPressed m1 : 5|2@1+ (1,0) [0|3] "" X
 SG_ VCLEFT_swcLeftScrollTicks m1 : 16|6@1- (1,0) [-32|31] "" X
 SG_ VCLEFT_swcLeftTiltLeft m1 : 14|2@1+ (1,0) [0|3] "" X
 SG_ VCLEFT_swcLeftTiltRight m1 : 3|2@1+ (1,0) [0|3] "" X
 SG_ VCLEFT_swcRightDoublePress m1 : 42|1@1+ (1,0) [0|1] "" X
 SG_ VCLEFT_swcRightPressed m1 : 12|2@1+ (1,0) [0|3] "" X
 SG_ VCLEFT_swcRightScrollTicks m1 : 24|6@1- (1,0) [-32|31] "" X
 SG_ VCLEFT_swcRightTiltLeft m1 : 8|2@1+ (1,0) [0|3] "" X
 SG_ VCLEFT_swcRightTiltRight m1 : 10|2@1+ (1,0) [0|3] "" X

BO_ 960 VCRIGHT_alertMatrix: 8 VEH
 SG_ VCRIGHT_matrixIndex M: 0|4@1+ (1,0) [0|0] "" X
 SG_ VCRIGHT_a001_WatchdogReset m0: 4|1@1+ (1,0) [0|0] "" X
 SG_ VCRIGHT_a002_PowerLossReset m0: 5|1@1+ (1,0) [0|0] "" X
 SG_ VCRIGHT_a003_SWAssertion m0: 6|1@1+ (1,0) [0|0] "" X
 SG_ VCRIGHT_a010_ExtSupplyVoltError m0: 13|1@1+ (1,0) [0|0] "" X
 SG_ VCRIGHT_a012_CPUReset m0: 15|1@1+ (1,0) [0|0] "" X
 SG_ VCRIGHT_a013_AlertManagerFault m0: 16|1@1+ (1,0) [0|0] "" X
 SG_ VCRIGHT_a015_NVMMAlert m0: 18|1@1+ (1,0) [0|0] "" X
 SG_ VCRIGHT_a021_TaskSchedulerError m0: 24|1@1+ (1,0) [0|0] "" X
 SG_ VCRIGHT_a022_TaskInitError m0: 25|1@1+ (1,0) [0|0] "" X
 SG_ VCRIGHT_a031_UDSActive m0: 34|1@1+ (1,0) [0|0] "" X
 SG_ VCRIGHT_a041_HighCPULoad m0: 44|1@1+ (1,0) [0|0] "" X
 SG_ VCRIGHT_a042_HighStackUsage m0: 45|1@1+ (1,0) [0|0] "" X
 SG_ VCRIGHT_a043_Task1msError m0: 46|1@1+ (1,0) [0|0] "" X
 SG_ VCRIGHT_a044_Task10msError m0: 47|1@1+ (1,0) [0|0] "" X
 SG_ VCRIGHT_a045_Task100msError m0: 48|1@1+ (1,0) [0|0] "" X
 SG_ VCRIGHT_a046_Task1000msError m0: 49|1@1+ (1,0) [0|0] "" X
 SG_ VCRIGHT_a059_inputResistanceHigh m0: 62|1@1+ (1,0) [0|0] "" X
 SG_ VCRIGHT_a060_engineeringBuild m0: 63|1@1+ (1,0) [0|0] "" X
 SG_ VCRIGHT_a061_XCPConnected m1: 4|1@1+ (1,0) [0|0] "" X
 SG_ VCRIGHT_a062_XCPWasConnected m1: 5|1@1+ (1,0) [0|0] "" X
 SG_ VCRIGHT_a063_SwitchFault m1: 6|1@1+ (1,0) [0|0] "" X
 SG_ VCRIGHT_a064_busSleepReqTimeout m1: 7|1@1+ (1,0) [0|0] "" X
 SG_ VCRIGHT_a097_CMP_MIA m1: 40|1@1+ (1,0) [0|0] "" X
 SG_ VCRIGHT_a098_DI_THERMAL_MIA m1: 41|1@1+ (1,0) [0|0] "" X
 SG_ VCRIGHT_a099_PARK_MIA m1: 42|1@1+ (1,0) [0|0] "" X
 SG_ VCRIGHT_a100_CANbus_MIA m1: 43|1@1+ (1,0) [0|0] "" X
 SG_ VCRIGHT_a101_PM_MIA m1: 44|1@1+ (1,0) [0|0] "" X
 SG_ VCRIGHT_a102_PTC_MIA m1: 45|1@1+ (1,0) [0|0] "" X
 SG_ VCRIGHT_a103_CP_MIA m1: 46|1@1+ (1,0) [0|0] "" X
 SG_ VCRIGHT_a104_DAS_MIA m1: 47|1@1+ (1,0) [0|0] "" X
 SG_ VCRIGHT_a105_TAS_MIA m1: 48|1@1+ (1,0) [0|0] "" X
 SG_ VCRIGHT_a106_PCS_MIA m1: 49|1@1+ (1,0) [0|0] "" X
 SG_ VCRIGHT_a107_BMS_MIA m1: 50|1@1+ (1,0) [0|0] "" X
 SG_ VCRIGHT_a108_DIS_MIA m1: 51|1@1+ (1,0) [0|0] "" X
 SG_ VCRIGHT_a109_RCM_MIA m1: 52|1@1+ (1,0) [0|0] "" X
 SG_ VCRIGHT_a110_GTW_MIA m1: 53|1@1+ (1,0) [0|0] "" X
 SG_ VCRIGHT_a111_EPBR_MIA m1: 54|1@1+ (1,0) [0|0] "" X
 SG_ VCRIGHT_a112_EPBL_MIA m1: 55|1@1+ (1,0) [0|0] "" X
 SG_ VCRIGHT_a113_UI_MIA m1: 56|1@1+ (1,0) [0|0] "" X
 SG_ VCRIGHT_a114_ESP_MIA m1: 57|1@1+ (1,0) [0|0] "" X
 SG_ VCRIGHT_a115_VCSEC_MIA m1: 58|1@1+ (1,0) [0|0] "" X
 SG_ VCRIGHT_a116_VCRIGHT_MIA m1: 59|1@1+ (1,0) [0|0] "" X
 SG_ VCRIGHT_a117_VCLEFT_MIA m1: 60|1@1+ (1,0) [0|0] "" X
 SG_ VCRIGHT_a118_VCFRONT_MIA m1: 61|1@1+ (1,0) [0|0] "" X
 SG_ VCRIGHT_a119_SCCM_MIA m1: 62|1@1+ (1,0) [0|0] "" X
 SG_ VCRIGHT_a120_DI_DRIVE_MIA m1: 63|1@1+ (1,0) [0|0] "" X
 SG_ VCRIGHT_a129_hvacIntakeUncalib m2: 12|1@1+ (1,0) [0|0] "" X
 SG_ VCRIGHT_a130_hvacLHBleedUncalib m2: 13|1@1+ (1,0) [0|0] "" X
 SG_ VCRIGHT_a131_hvacRHBleedUncalib m2: 14|1@1+ (1,0) [0|0] "" X
 SG_ VCRIGHT_a132_hvacLHVaneUncalib m2: 15|1@1+ (1,0) [0|0] "" X
 SG_ VCRIGHT_a133_hvacRHVaneUncalib m2: 16|1@1+ (1,0) [0|0] "" X
 SG_ VCRIGHT_a134_hvacUpprModeUncalib m2: 17|1@1+ (1,0) [0|0] "" X
 SG_ VCRIGHT_a135_hvacLowrModeUncalib m2: 18|1@1+ (1,0) [0|0] "" X
 SG_ VCRIGHT_a136_hvacIntakeFault m2: 19|1@1+ (1,0) [0|0] "" X
 SG_ VCRIGHT_a137_hvacLHBleedFault m2: 20|1@1+ (1,0) [0|0] "" X
 SG_ VCRIGHT_a138_hvacRHBleedFault m2: 21|1@1+ (1,0) [0|0] "" X
 SG_ VCRIGHT_a139_hvacLHVaneFault m2: 22|1@1+ (1,0) [0|0] "" X
 SG_ VCRIGHT_a140_hvacRHVaneFault m2: 23|1@1+ (1,0) [0|0] "" X
 SG_ VCRIGHT_a141_hvacUpperModeFault m2: 24|1@1+ (1,0) [0|0] "" X
 SG_ VCRIGHT_a142_hvacLowerModeFault m2: 25|1@1+ (1,0) [0|0] "" X
 SG_ VCRIGHT_a144_evaporatorTempSns m2: 27|1@1+ (1,0) [0|0] "" X
 SG_ VCRIGHT_a145_ductLeftTempSns m2: 28|1@1+ (1,0) [0|0] "" X
 SG_ VCRIGHT_a146_ductRightTempSns m2: 29|1@1+ (1,0) [0|0] "" X
 SG_ VCRIGHT_a147_incarProbeTempSns m2: 30|1@1+ (1,0) [0|0] "" X
 SG_ VCRIGHT_a148_incarMidTempSns m2: 31|1@1+ (1,0) [0|0] "" X
 SG_ VCRIGHT_a149_incarDeepTempSns m2: 32|1@1+ (1,0) [0|0] "" X
 SG_ VCRIGHT_a150_windowPinchFront m2: 33|1@1+ (1,0) [0|0] "" X
 SG_ VCRIGHT_a151_windowPinchRear m2: 34|1@1+ (1,0) [0|0] "" X
 SG_ VCRIGHT_a152_windowUncalFront m2: 35|1@1+ (1,0) [0|0] "" X
 SG_ VCRIGHT_a153_windowUncalRear m2: 36|1@1+ (1,0) [0|0] "" X
 SG_ VCRIGHT_a154_windowThermalFront m2: 37|1@1+ (1,0) [0|0] "" X
 SG_ VCRIGHT_a155_windowThermalRear m2: 38|1@1+ (1,0) [0|0] "" X
 SG_ VCRIGHT_a156_windowNoInputFront m2: 39|1@1+ (1,0) [0|0] "" X
 SG_ VCRIGHT_a157_windowNoInputRear m2: 40|1@1+ (1,0) [0|0] "" X
 SG_ VCRIGHT_a158_windowPinchOverideF m2: 41|1@1+ (1,0) [0|0] "" X
 SG_ VCRIGHT_a159_windowPinchOverideR m2: 42|1@1+ (1,0) [0|0] "" X
 SG_ VCRIGHT_a160_windowUndercurrentF m2: 43|1@1+ (1,0) [0|0] "" X
 SG_ VCRIGHT_a161_windowUndercurrentR m2: 44|1@1+ (1,0) [0|0] "" X
 SG_ VCRIGHT_a162_windowEncoderStallF m2: 45|1@1+ (1,0) [0|0] "" X
 SG_ VCRIGHT_a163_windowEncoderStallR m2: 46|1@1+ (1,0) [0|0] "" X
 SG_ VCRIGHT_a164_windowFactoryTest m2: 47|1@1+ (1,0) [0|0] "" X
 SG_ VCRIGHT_a165_windowFactoryTest2 m2: 48|1@1+ (1,0) [0|0] "" X
 SG_ VCRIGHT_a166_windowDebug m2: 49|1@1+ (1,0) [0|0] "" X
 SG_ VCRIGHT_a167_windowDebugPinchF m2: 50|1@1+ (1,0) [0|0] "" X
 SG_ VCRIGHT_a168_windowDebugPinchR m2: 51|1@1+ (1,0) [0|0] "" X
 SG_ VCRIGHT_a169_windowCurrentPeakF m2: 52|1@1+ (1,0) [0|0] "" X
 SG_ VCRIGHT_a170_windowCurrentPeakR m2: 53|1@1+ (1,0) [0|0] "" X
 SG_ VCRIGHT_a172_SPI_MIA m2: 55|1@1+ (1,0) [0|0] "" X
 SG_ VCRIGHT_a174_BLERightPowerCycled m2: 57|1@1+ (1,0) [0|0] "" X
 SG_ VCRIGHT_a180_frontDoorLatchRehome m2: 63|1@1+ (1,0) [0|0] "" X
 SG_ VCRIGHT_a181_rearDoorLatchRehome m3: 4|1@1+ (1,0) [0|0] "" X
 SG_ VCRIGHT_a182_emergencyLatchRel m3: 5|1@1+ (1,0) [0|0] "" X
 SG_ VCRIGHT_a183_doorStateFactoryTest m3: 6|1@1+ (1,0) [0|0] "" X
 SG_ VCRIGHT_a184_trunkFailedOpening m3: 7|1@1+ (1,0) [0|0] "" X
 SG_ VCRIGHT_a185_summonAborted m3: 8|1@1+ (1,0) [0|0] "" X
 SG_ VCRIGHT_a186_latchReleaseFailedF m3: 9|1@1+ (1,0) [0|0] "" X
 SG_ VCRIGHT_a187_latchReleaseFailedR m3: 10|1@1+ (1,0) [0|0] "" X
 SG_ VCRIGHT_a188_latchUnableToRearmF m3: 11|1@1+ (1,0) [0|0] "" X
 SG_ VCRIGHT_a189_latchUnableToRearmR m3: 12|1@1+ (1,0) [0|0] "" X
 SG_ VCRIGHT_a190_eFuseMgmtVbatFused m3: 13|1@1+ (1,0) [0|0] "" X
 SG_ VCRIGHT_a191_gloveboxPower m3: 14|1@1+ (1,0) [0|0] "" X
 SG_ VCRIGHT_a192_gloveboxLatchRel m3: 15|1@1+ (1,0) [0|0] "" X
 SG_ VCRIGHT_a193_amplifierEFuseFault m3: 16|1@1+ (1,0) [0|0] "" X
 SG_ VCRIGHT_a194_cntctrPwrEFuseFault m3: 17|1@1+ (1,0) [0|0] "" X
 SG_ VCRIGHT_a195_hvcEFuseFault m3: 18|1@1+ (1,0) [0|0] "" X
 SG_ VCRIGHT_a196_VEHCANOverterminate m3: 19|1@1+ (1,0) [0|0] "" X
 SG_ VCRIGHT_a197_VEHCANUndertrminate m3: 20|1@1+ (1,0) [0|0] "" X
 SG_ VCRIGHT_a198_PRVCANOverterminate m3: 21|1@1+ (1,0) [0|0] "" X
 SG_ VCRIGHT_a199_PRVCANUndertrminate m3: 22|1@1+ (1,0) [0|0] "" X
 SG_ VCRIGHT_a200_motorPhantomEncoder m3: 23|1@1+ (1,0) [0|0] "" X
 SG_ VCRIGHT_a201_motorDutyEncDisabl m3: 24|1@1+ (1,0) [0|0] "" X
 SG_ VCRIGHT_a202_epbmUnderIStatic m3: 25|1@1+ (1,0) [0|0] "" X
 SG_ VCRIGHT_a203_epbmOverIStatic m3: 26|1@1+ (1,0) [0|0] "" X
 SG_ VCRIGHT_a204_epbmUnderIDyn m3: 27|1@1+ (1,0) [0|0] "" X
 SG_ VCRIGHT_a205_epbmOverIDyn m3: 28|1@1+ (1,0) [0|0] "" X
 SG_ VCRIGHT_a206_epbWrongDirection m3: 29|1@1+ (1,0) [0|0] "" X
 SG_ VCRIGHT_a207_epbmEnableWrong m3: 30|1@1+ (1,0) [0|0] "" X
 SG_ VCRIGHT_a208_epbFaulted m3: 31|1@1+ (1,0) [0|0] "" X
 SG_ VCRIGHT_a209_epbStateMisTime m3: 32|1@1+ (1,0) [0|0] "" X
 SG_ VCRIGHT_a210_epbStateTime m3: 33|1@1+ (1,0) [0|0] "" X
 SG_ VCRIGHT_a211_epbmUnderIStaticNew m3: 34|1@1+ (1,0) [0|0] "" X
 SG_ VCRIGHT_a212_epbmOverIStaticNew m3: 35|1@1+ (1,0) [0|0] "" X
 SG_ VCRIGHT_a213_epbmUnderIDynNew m3: 36|1@1+ (1,0) [0|0] "" X
 SG_ VCRIGHT_a214_epbmOverIDynNew m3: 37|1@1+ (1,0) [0|0] "" X
 SG_ VCRIGHT_a215_currentDesyncWarning m3: 38|1@1+ (1,0) [0|0] "" X
 SG_ VCRIGHT_a216_SPI_MIA_debugData1 m3: 39|1@1+ (1,0) [0|0] "" X
 SG_ VCRIGHT_a217_SPI_MIA_debugData2 m3: 40|1@1+ (1,0) [0|0] "" X
 SG_ VCRIGHT_a218_motorDriverFault m3: 41|1@1+ (1,0) [0|0] "" X
 SG_ VCRIGHT_a219_motorCurrentDropout m3: 42|1@1+ (1,0) [0|0] "" X
 SG_ VCRIGHT_a220_seatCurrStallTrack m3: 43|1@1+ (1,0) [0|0] "" X
 SG_ VCRIGHT_a221_seatCurrStallBack m3: 44|1@1+ (1,0) [0|0] "" X
 SG_ VCRIGHT_a222_seatCurrStallTilt m3: 45|1@1+ (1,0) [0|0] "" X
 SG_ VCRIGHT_a223_seatCurrStallLift m3: 46|1@1+ (1,0) [0|0] "" X
 SG_ VCRIGHT_a224_seatEncStallTrack m3: 47|1@1+ (1,0) [0|0] "" X
 SG_ VCRIGHT_a225_seatEncStallBack m3: 48|1@1+ (1,0) [0|0] "" X
 SG_ VCRIGHT_a226_seatEncStallTilt m3: 49|1@1+ (1,0) [0|0] "" X
 SG_ VCRIGHT_a227_seatEncStallLift m3: 50|1@1+ (1,0) [0|0] "" X
 SG_ VCRIGHT_a228_seatEncOverTrack m3: 51|1@1+ (1,0) [0|0] "" X
 SG_ VCRIGHT_a229_seatEncOverBack m3: 52|1@1+ (1,0) [0|0] "" X
 SG_ VCRIGHT_a230_seatEncOverTilt m3: 53|1@1+ (1,0) [0|0] "" X
 SG_ VCRIGHT_a231_seatEncOverLift m3: 54|1@1+ (1,0) [0|0] "" X
 SG_ VCRIGHT_a232_seatCurrUnderTrack m3: 55|1@1+ (1,0) [0|0] "" X
 SG_ VCRIGHT_a233_seatCurrUnderBack m3: 56|1@1+ (1,0) [0|0] "" X
 SG_ VCRIGHT_a234_seatCurrUnderTilt m3: 57|1@1+ (1,0) [0|0] "" X
 SG_ VCRIGHT_a235_seatCurrUnderLift m3: 58|1@1+ (1,0) [0|0] "" X
 SG_ VCRIGHT_a236_lumbarOverPresA m3: 59|1@1+ (1,0) [0|0] "" X
 SG_ VCRIGHT_a237_lumbarOverPresB m3: 60|1@1+ (1,0) [0|0] "" X
 SG_ VCRIGHT_a238_lumbarValveMIA m3: 61|1@1+ (1,0) [0|0] "" X
 SG_ VCRIGHT_a239_seatHeatIFront m3: 62|1@1+ (1,0) [0|0] "" X
 SG_ VCRIGHT_a240_seatHeatShortFront m3: 63|1@1+ (1,0) [0|0] "" X
 SG_ VCRIGHT_a241_seatHeatMIAFront m4: 4|1@1+ (1,0) [0|0] "" X
 SG_ VCRIGHT_a242_seatHeatIRearL m4: 5|1@1+ (1,0) [0|0] "" X
 SG_ VCRIGHT_a243_seatHeatShortRearL m4: 6|1@1+ (1,0) [0|0] "" X
 SG_ VCRIGHT_a244_seatHeatMIARearL m4: 7|1@1+ (1,0) [0|0] "" X
 SG_ VCRIGHT_a245_seatHeatIRearC m4: 8|1@1+ (1,0) [0|0] "" X
 SG_ VCRIGHT_a246_seatHeatShortRearC m4: 9|1@1+ (1,0) [0|0] "" X
 SG_ VCRIGHT_a247_seatHeatMIARearC m4: 10|1@1+ (1,0) [0|0] "" X
 SG_ VCRIGHT_a248_seatHeatIRearR m4: 11|1@1+ (1,0) [0|0] "" X
 SG_ VCRIGHT_a249_seatHeatShortRearR m4: 12|1@1+ (1,0) [0|0] "" X
 SG_ VCRIGHT_a250_seatHeatMIARearR m4: 13|1@1+ (1,0) [0|0] "" X
 SG_ VCRIGHT_a251_seatUncalTrack m4: 14|1@1+ (1,0) [0|0] "" X
 SG_ VCRIGHT_a252_seatUncalBack m4: 15|1@1+ (1,0) [0|0] "" X
 SG_ VCRIGHT_a253_seatUncalTilt m4: 16|1@1+ (1,0) [0|0] "" X
 SG_ VCRIGHT_a254_seatUncalLift m4: 17|1@1+ (1,0) [0|0] "" X
 SG_ VCRIGHT_a255_PTCOverTemp m4: 18|1@1+ (1,0) [0|0] "" X
 SG_ VCRIGHT_a256_PTCCurrentDrawNoReq m4: 19|1@1+ (1,0) [0|0] "" X
 SG_ VCRIGHT_a257_THSMIA m4: 20|1@1+ (1,0) [0|0] "" X
 SG_ VCRIGHT_a258_PTCStuckInBoot m4: 21|1@1+ (1,0) [0|0] "" X
 SG_ VCRIGHT_a259_latchDisarmDelayF m4: 22|1@1+ (1,0) [0|0] "" X
 SG_ VCRIGHT_a260_latchDisarmDelayR m4: 23|1@1+ (1,0) [0|0] "" X
 SG_ VCRIGHT_a262_PTCFaulted m4: 25|1@1+ (1,0) [0|0] "" X
 SG_ VCRIGHT_a263_seatTrackStallDebug m4: 26|1@1+ (1,0) [0|0] "" X
 SG_ VCRIGHT_a264_seatBackStallDebug m4: 27|1@1+ (1,0) [0|0] "" X
 SG_ VCRIGHT_a265_seatTiltStallDebug m4: 28|1@1+ (1,0) [0|0] "" X
 SG_ VCRIGHT_a266_seatLiftStallDebug m4: 29|1@1+ (1,0) [0|0] "" X
 SG_ VCRIGHT_a267_seatTrackHCEncStlDbg m4: 30|1@1+ (1,0) [0|0] "" X
 SG_ VCRIGHT_a268_seatBackHCEncStlDbg m4: 31|1@1+ (1,0) [0|0] "" X
 SG_ VCRIGHT_a269_seatTiltHCEncStlDbg m4: 32|1@1+ (1,0) [0|0] "" X
 SG_ VCRIGHT_a270_seatLiftHCEncStlDbg m4: 33|1@1+ (1,0) [0|0] "" X
 SG_ VCRIGHT_a271_THSSensorFault m4: 34|1@1+ (1,0) [0|0] "" X
 SG_ VCRIGHT_a272_vhclPwrStateMsmtch m4: 35|1@1+ (1,0) [0|0] "" X
 SG_ VCRIGHT_a273_handleStuckActiveF m4: 36|1@1+ (1,0) [0|0] "" X
 SG_ VCRIGHT_a274_handleStuckActiveR m4: 37|1@1+ (1,0) [0|0] "" X
 SG_ VCRIGHT_a275_rightTurnLightFault m4: 38|1@1+ (1,0) [0|0] "" X
 SG_ VCRIGHT_a276_mirrorDebug m4: 39|1@1+ (1,0) [0|0] "" X
 SG_ VCRIGHT_a277_BLERightUnderVoltage m4: 40|1@1+ (1,0) [0|0] "" X
 SG_ VCRIGHT_a280_latchDidNotDisarmF m4: 43|1@1+ (1,0) [0|0] "" X
 SG_ VCRIGHT_a281_latchDidNotDisarmR m4: 44|1@1+ (1,0) [0|0] "" X
 SG_ VCRIGHT_a282_latchUnexpectedArmF m4: 45|1@1+ (1,0) [0|0] "" X
 SG_ VCRIGHT_a283_latchUnexpectedArmR m4: 46|1@1+ (1,0) [0|0] "" X
 SG_ VCRIGHT_a286_windowSpeedInvalidF m4: 49|1@1+ (1,0) [0|0] "" X
 SG_ VCRIGHT_a287_windowSpeedInvalidR m4: 50|1@1+ (1,0) [0|0] "" X
 SG_ VCRIGHT_a290_occupancyFaultedFront m4: 53|1@1+ (1,0) [0|0] "" X
 SG_ VCRIGHT_a291_buckleFaultedFront m4: 54|1@1+ (1,0) [0|0] "" X
 SG_ VCRIGHT_a292_buckleFaultedRearC m4: 55|1@1+ (1,0) [0|0] "" X
 SG_ VCRIGHT_a293_buckleFaultedRearR m4: 56|1@1+ (1,0) [0|0] "" X
 SG_ VCRIGHT_a304_frontIntHandleShorted m5: 7|1@1+ (1,0) [0|0] "" X
 SG_ VCRIGHT_a305_rearIntHandleShorted m5: 8|1@1+ (1,0) [0|0] "" X
 SG_ VCRIGHT_a306_handleDisconnectedF m5: 9|1@1+ (1,0) [0|0] "" X
 SG_ VCRIGHT_a307_handleDisconnectedR m5: 10|1@1+ (1,0) [0|0] "" X

BO_ 1795 VCRIGHT_debugThermal10Hz: 8 VEH
 SG_ VCRIGHT_debugThermal10HzIndex M: 0|3@1+ (1,0) [0|0] "" X
 SG_ VCRIGHT_wattsDemandEvapFeedback m0: 3|9@1- (20,0) [0|0] "W" X
 SG_ VCRIGHT_wattsDemandEvapFeedfwd m0: 12|9@1+ (20,0) [0|0] "W" X
 SG_ VCRIGHT_wattsHeaterLeftFeedback m0: 21|9@1- (20,0) [0|0] "W" X
 SG_ VCRIGHT_wattsHeaterLeftFeedfwd m0: 30|9@1+ (20,0) [0|0] "W" X
 SG_ VCRIGHT_wattsHeaterRightFeedback m0: 39|9@1- (20,0) [0|0] "W" X
 SG_ VCRIGHT_wattsHeaterRightFeedfwd m0: 48|9@1+ (20,0) [0|0] "W" X
 SG_ VCRIGHT_tempEvapAdjustmentLeft m1: 8|7@1+ (0.1,0) [0|0] "degC" X
 SG_ VCRIGHT_tempEvapAdjustmentRight m1: 16|7@1+ (0.1,0) [0|0] "degC" X
 SG_ VCRIGHT_hvacPanelFloorSplitRow1 m2: 8|8@1+ (0.4,0) [0|0] "%" X
 SG_ VCRIGHT_hvacDefrostPercent m2: 16|8@1+ (0.4,0) [0|0] "%" X
 SG_ VCRIGHT_hvacRow2Percent m2: 24|8@1+ (0.4,0) [0|0] "%" X
 SG_ VCRIGHT_hvacPanelFloorSplitRow2 m2: 32|8@1+ (0.4,0) [0|0] "%" X
 SG_ VCRIGHT_cabinTempThs m3: 8|8@1+ (0.5,-40) [0|0] "degC" X
 SG_ VCRIGHT_cabinTempThsBracket m3: 16|8@1+ (0.5,-40) [0|0] "degC" X
 SG_ VCRIGHT_cabinTempProbe m3: 24|8@1+ (0.5,-40) [0|0] "degC" X
 SG_ VCRIGHT_setTempAdjustmentLeft m3: 32|7@1+ (0.1,0) [0|0] "degC" X
 SG_ VCRIGHT_setTempAdjustmentRight m3: 40|7@1+ (0.1,0) [0|0] "degC" X
 SG_ VCRIGHT_hvacLHBleedCalibrated m4: 3|1@1+ (1,0) [0|0] "" X
 SG_ VCRIGHT_hvacActuatorsCalibrated m4: 4|1@1+ (1,0) [0|0] "" X
 SG_ VCRIGHT_hvacRHBleedCalibrated m4: 7|1@1+ (1,0) [0|0] "" X
 SG_ VCRIGHT_hvacLHVaneCalibrated m4: 11|1@1+ (1,0) [0|0] "" X
 SG_ VCRIGHT_hvacRHVaneCalibrated m4: 15|1@1+ (1,0) [0|0] "" X
 SG_ VCRIGHT_hvacUpperModeCalibrated m4: 19|1@1+ (1,0) [0|0] "" X
 SG_ VCRIGHT_hvacLowerModeCalibrated m4: 23|1@1+ (1,0) [0|0] "" X
 SG_ VCRIGHT_hvacIntakeCalibrated m4: 27|1@1+ (1,0) [0|0] "" X

BO_ 259 VCRIGHT_doorStatus: 8 VEH
 SG_ VCRIGHT_frontHandlePWM: 14|7@1+ (1,0) [0|0] "%" X
 SG_ VCRIGHT_frontHandlePulled: 10|1@1+ (1,0) [0|0] "" X
 SG_ VCRIGHT_frontHandlePulledPersist: 30|1@1+ (1,0) [0|0] "" X
 SG_ VCRIGHT_frontIntSwitchPressed: 31|1@1+ (1,0) [0|0] "" X
 SG_ VCRIGHT_frontLatchStatus: 0|4@1+ (1,0) [0|0] "" X
 SG_ VCRIGHT_frontLatchSwitch: 8|1@1+ (1,0) [0|0] "" X
 SG_ VCRIGHT_frontRelActuatorSwitch: 12|1@1+ (1,0) [0|0] "" X
 SG_ VCRIGHT_mirrorDipped: 63|1@1+ (1,0) [0|0] "" X
 SG_ VCRIGHT_mirrorFoldState: 52|3@1+ (1,0) [0|0] "" X
 SG_ VCRIGHT_mirrorRecallState: 60|3@1+ (1,0) [0|0] "" X
 SG_ VCRIGHT_mirrorState: 49|3@1+ (1,0) [0|0] "" X
 SG_ VCRIGHT_mirrorTiltXPosition: 33|8@1+ (0.02,0) [0|0] "V" X
 SG_ VCRIGHT_mirrorTiltYPosition: 41|8@1+ (0.02,0) [0|0] "V" X
 SG_ VCRIGHT_rearHandlePWM: 21|7@1+ (1,0) [0|0] "%" X
 SG_ VCRIGHT_rearHandlePulled: 11|1@1+ (1,0) [0|0] "" X
 SG_ VCRIGHT_rearIntSwitchPressed: 32|1@1+ (1,0) [0|0] "" X
 SG_ VCRIGHT_rearLatchStatus: 4|4@1+ (1,0) [0|0] "" X
 SG_ VCRIGHT_rearLatchSwitch: 9|1@1+ (1,0) [0|0] "" X
 SG_ VCRIGHT_rearRelActuatorSwitch: 13|1@1+ (1,0) [0|0] "" X
 SG_ VCRIGHT_reservedForBackCompat: 28|2@1+ (1,0) [0|0] "" X
 SG_ VCRIGHT_trunkLatchStatus: 56|4@1+ (1,0) [0|0] "" X

BO_ 915 ID393VCRIGHT_epbmDebug: 8 VEH
 SG_ VCRIGHT_epbmDebugIndex M : 0|1@1+ (1,0) [0|1] ""  Receiver
 SG_ VCRIGHT_cdpEnumDummy m1 : 24|2@1+ (1,0) [0|2] ""  Receiver
 SG_ VCRIGHT_epbFaultStatus m0 : 58|2@1+ (1,0) [0|3] ""  Receiver
 SG_ VCRIGHT_epbMotorCurrent m0 : 5|11@1+ (0.01,0) [0|20.47] "A"  Receiver
 SG_ VCRIGHT_epbSummonState m0 : 45|3@1+ (1,0) [0|6] ""  Receiver
 SG_ VCRIGHT_epbUnitStatus m0 : 51|5@1+ (1,0) [0|22] ""  Receiver
 SG_ VCRIGHT_epbmApplyVoltage m0 : 16|11@1+ (0.01,0) [0|20.47] "A"  Receiver
 SG_ VCRIGHT_epbmCaliperState m0 : 1|3@1+ (1,0) [0|6] ""  Receiver
 SG_ VCRIGHT_epbmDynApplyingAllowed m1 : 9|1@1+ (1,0) [0|1] ""  Receiver
 SG_ VCRIGHT_epbmDynamicAllowed m1 : 2|1@1+ (1,0) [0|1] ""  Receiver
 SG_ VCRIGHT_epbmFaultAllowed m1 : 11|1@1+ (1,0) [0|1] ""  Receiver
 SG_ VCRIGHT_epbmFaultStatus m0 : 56|2@1+ (1,0) [0|3] ""  ui
 SG_ VCRIGHT_epbmMotorEnabled m0 : 4|1@1+ (1,0) [0|1] ""  Receiver
 SG_ VCRIGHT_epbmOpenAllowed m1 : 1|1@1+ (1,0) [0|1] ""  Receiver
 SG_ VCRIGHT_epbmParkAllowed m1 : 3|1@1+ (1,0) [0|1] ""  Receiver
 SG_ VCRIGHT_epbmParkingAllowed m1 : 8|1@1+ (1,0) [0|1] ""  Receiver
 SG_ VCRIGHT_epbmReleaseVoltage m0 : 27|11@1+ (0.01,0) [0|20.47] "A"  Receiver
 SG_ VCRIGHT_epbmReleasingAllowed m1 : 10|1@1+ (1,0) [0|1] ""  Receiver
 SG_ VCRIGHT_epbmServiceAllowed m1 : 5|1@1+ (1,0) [0|1] ""  Receiver
 SG_ VCRIGHT_epbmStartAllowed m1 : 4|1@1+ (1,0) [0|1] ""  Receiver
 SG_ VCRIGHT_epbmSummonAllowed m1 : 12|1@1+ (1,0) [0|1] ""  Receiver
 SG_ VCRIGHT_epbmSummonParkAllowed m1 : 13|1@1+ (1,0) [0|1] ""  Receiver
 SG_ VCRIGHT_epbmSummonReleaseAllowed m1 : 14|1@1+ (1,0) [0|1] ""  Receiver
 SG_ VCRIGHT_epbmSummonState m0 : 48|3@1+ (1,0) [0|6] ""  Receiver
 SG_ VCRIGHT_epbmSystemStatus m0 : 60|4@1+ (1,0) [0|8] ""  Receiver
 SG_ VCRIGHT_epbmUnknownAllowed m1 : 16|1@1+ (1,0) [0|1] ""  Receiver
 SG_ VCRIGHT_epbmWinchAllowed m1 : 6|1@1+ (1,0) [0|1] ""  Receiver
 SG_ VCRIGHT_epbmWinchReleaseAllowed m1 : 7|1@1+ (1,0) [0|1] ""  Receiver
 SG_ VCRIGHT_summonActiveAllowed m1 : 19|1@1+ (1,0) [0|1] ""  Receiver
 SG_ VCRIGHT_summonArmedAllowed m1 : 18|1@1+ (1,0) [0|1] ""  Receiver
 SG_ VCRIGHT_summonCompleteAllowed m1 : 20|1@1+ (1,0) [0|1] ""  Receiver
 SG_ VCRIGHT_summonFaultAllowed m1 : 21|1@1+ (1,0) [0|1] ""  Receiver
 SG_ VCRIGHT_summonFaultReason m0 : 40|5@1+ (1,0) [0|28] ""  Receiver
 SG_ VCRIGHT_summonIdleAllowed m1 : 17|1@1+ (1,0) [0|1] ""  Receiver
 SG_ VCRIGHT_summonInitAllowed m1 : 15|1@1+ (1,0) [0|1] ""  Receiver
 SG_ VCRIGHT_summonUnavailableAllowed m1 : 22|1@1+ (1,0) [0|1] ""  Receiver

BO_ 579 ID243VCRIGHT_hvacStatus: 8 VEH
 SG_ VCRIGHT_hvacStatusIndex M : 0|2@1+ (1,0) [0|3] ""  Receiver
 SG_ VCRIGHT_hvacACRunning m0 : 50|1@1+ (1,0) [0|1] ""  Receiver
 SG_ VCRIGHT_hvacAirDistributionMode m0 : 41|3@1+ (1,0) [0|7] ""  Receiver
 SG_ VCRIGHT_hvacBlowerSegment m0 : 44|4@1+ (1,0) [0|11] ""  Receiver
 SG_ VCRIGHT_hvacCabinTempEst m0 : 30|11@1+ (0.1,-40) [-40|164] "C"  Receiver
 SG_ VCRIGHT_hvacDuctTargetLeft m1 : 48|8@1+ (0.5,-40) [-40|80] "C"  Receiver
 SG_ VCRIGHT_hvacDuctTargetRight m1 : 56|8@1+ (0.5,-40) [-40|80] "C"  Receiver
 SG_ VCRIGHT_hvacMassflowRefrigSystem m1 : 2|8@1+ (1,0) [0|250] "g/s"  Receiver
 SG_ VCRIGHT_hvacModelInitStatus m0 : 60|3@1+ (1,0) [0|5] ""  Receiver
 SG_ VCRIGHT_hvacOverheatProtActive m0 : 63|1@1+ (1,0) [0|1] ""  Receiver
 SG_ VCRIGHT_hvacPowerState m0 : 51|3@1+ (1,0) [0|4] ""  Receiver
 SG_ VCRIGHT_hvacQdotLeft m0 : 2|14@1+ (1,-8191) [-8191|8191] "W"  Receiver
 SG_ VCRIGHT_hvacQdotRight m0 : 16|14@1+ (1,-8191) [-8191|8191] "W"  Receiver
 SG_ VCRIGHT_hvacRecirc m0 : 48|2@1+ (1,0) [0|2] ""  Receiver
 SG_ VCRIGHT_hvacRecircDoorPercent m1 : 10|6@1+ (1.6,0) [0|100] "%"  Receiver
 SG_ VCRIGHT_hvacSecondRowState m0 : 56|3@1+ (1,0) [0|4] ""  Receiver
 SG_ VCRIGHT_hvacSystemNominal m0 : 59|1@1+ (1,0) [0|1] ""  Receiver
 SG_ VCRIGHT_hvacVentStatus m0 : 54|2@1+ (1,0) [0|2] ""  Receiver
 SG_ VCRIGHT_tempDuctLeft m1 : 16|8@1+ (0.5,-22) [-22|105] "C"  Receiver
 SG_ VCRIGHT_tempDuctLeftLower m1 : 24|8@1+ (0.5,-22) [-22|105] "C"  Receiver
 SG_ VCRIGHT_tempDuctLeftUpper m2 : 2|8@1+ (0.5,-22) [-22|105] "C"  Receiver
 SG_ VCRIGHT_tempDuctRight m1 : 32|8@1+ (0.5,-22) [-22|105] "C"  Receiver
 SG_ VCRIGHT_tempDuctRightLower m1 : 40|8@1+ (0.5,-22) [-22|105] "C"  Receiver
 SG_ VCRIGHT_tempDuctRightUpper m2 : 10|8@1+ (0.5,-22) [-22|105] "C"  Receiver

BO_ 524 VCRIGHT_hvacRequest: 7 VEH
 SG_ VCRIGHT_conditioningRequest : 12|1@1+ (1,0) [0|1] "" X
 SG_ VCRIGHT_evapPerformanceLow : 43|1@1+ (1,0) [0|1] "" X
 SG_ VCRIGHT_hvacBlowerSpeedRPMReq : 32|10@1+ (5,0) [0|5115] "RPM" X
 SG_ VCRIGHT_hvacEvapEnabled : 11|1@1+ (1,0) [0|1] "" X
 SG_ VCRIGHT_hvacHeatingEnabledLeft : 52|1@1+ (1,0) [0|1] "" X
 SG_ VCRIGHT_hvacHeatingEnabledRight : 53|1@1+ (1,0) [0|1] "" X
 SG_ VCRIGHT_hvacPerfTestRunning : 42|1@1+ (1,0) [0|1] "" X
 SG_ VCRIGHT_hvacPerfTestState : 54|2@1+ (1,0) [0|2] "" X
 SG_ VCRIGHT_tempAmbientRaw : 44|8@1+ (0.5,-40) [-40|80] "C" X
 SG_ VCRIGHT_tempEvaporator : 13|11@1+ (0.1,-40) [-40|105] "C" X
 SG_ VCRIGHT_tempEvaporatorTarget : 24|8@1+ (0.2,0) [0|50] "C" X
 SG_ VCRIGHT_wattsDemandEvap : 0|11@1+ (5,0) [0|10000] "W" X

BO_ 774 VCRIGHT_info: 8 VEH
 SG_ VCRIGHT_infoIndex M: 0|8@1+ (1,0) [0|0] "" X
 SG_ VCRIGHT_infoBuildType m10: 8|3@1+ (1,0) [0|0] "" X
 SG_ VCRIGHT_infoBuildConfigId m10: 16|16@1+ (1,0) [0|0] "" X
 SG_ VCRIGHT_infoHardwareId m10: 32|16@1+ (1,0) [0|0] "" X
 SG_ VCRIGHT_infoComponentId m10: 48|16@1+ (1,0) [0|0] "" X
 SG_ VCRIGHT_infoPcbaId m11: 8|8@1+ (1,0) [0|0] "" X
 SG_ VCRIGHT_infoAssemblyId m11: 16|8@1+ (1,0) [0|0] "" X
 SG_ VCRIGHT_infoUsageId m11: 24|16@1+ (1,0) [0|0] "" X
 SG_ VCRIGHT_infoSubUsageId m11: 40|16@1+ (1,0) [0|0] "" X
 SG_ VCRIGHT_infoAppCrc m13: 8|32@1+ (1,0) [0|0] "" X
 SG_ VCRIGHT_infoAppGitHash m17: 10|54@1+ (4,0) [0|0] "" X
 SG_ VCRIGHT_infoBootGitHash m18: 10|54@1+ (4,0) [0|0] "" X
 SG_ VCRIGHT_infoPlatformType m19: 8|8@1+ (1,0) [0|0] "" X
 SG_ VCRIGHT_infoBootUdsProtoVersion m20: 8|16@1+ (1,0) [0|0] "" X
 SG_ VCRIGHT_infoBootCrc m20: 24|32@1+ (1,0) [0|0] "" X

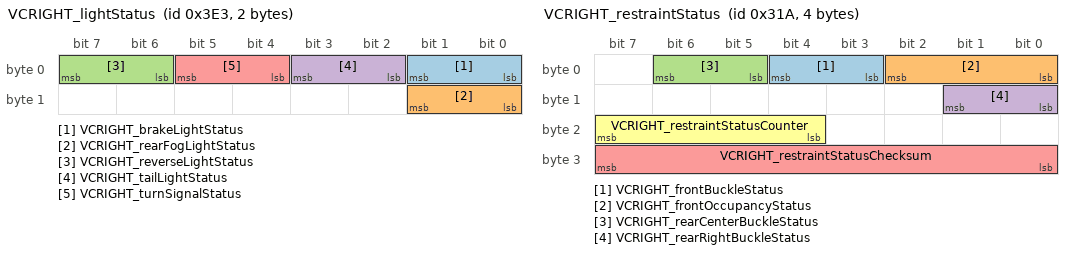
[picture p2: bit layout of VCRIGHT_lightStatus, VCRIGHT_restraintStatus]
BO_ 995 VCRIGHT_lightStatus: 2 VEH
 SG_ VCRIGHT_brakeLightStatus: 0|2@1+ (1,0) [0|0] "" X
 SG_ VCRIGHT_rearFogLightStatus: 8|2@1+ (1,0) [0|0] "" X
 SG_ VCRIGHT_reverseLightStatus: 6|2@1+ (1,0) [0|0] "" X
 SG_ VCRIGHT_tailLightStatus: 2|2@1+ (1,0) [0|0] "" X
 SG_ VCRIGHT_turnSignalStatus: 4|2@1+ (1,0) [0|0] "" X

BO_ 611 VCRIGHT_logging10Hz: 8 VEH
 SG_ VCRIGHT_logging10HzIndex M : 0|3@1+ (1,0) [0|4] ""  Receiver
 SG_ VCRIGHT_evapPulldownBias m3 : 8|8@1+ (0.4,0) [0|100] "%"  Receiver
 SG_ VCRIGHT_evapPulldownBiasActive m3 : 16|1@1+ (1,0) [0|1] ""  Receiver
 SG_ VCRIGHT_hvacCabinHumidityLevel m2 : 55|8@1+ (1,0) [0|100] "%"  Receiver
 SG_ VCRIGHT_hvacEstimateWindshieldRH m2 : 39|8@1+ (1,0) [0|150] "%"  Receiver
 SG_ VCRIGHT_hvacFilterLifeDetectActi m2 : 3|1@1+ (1,0) [0|1] ""  Receiver
 SG_ VCRIGHT_hvacFlashFoggingDetected m2 : 63|1@1+ (1,0) [0|1] ""  Receiver
 SG_ VCRIGHT_hvacFoggingRiskLevel m2 : 47|8@1+ (1,0) [0|100] "%"  Receiver
 SG_ VCRIGHT_hvacIntakeActuatorState m2 : 24|2@1+ (1,0) [0|2] ""  Receiver
 SG_ VCRIGHT_hvacIntakeOperationMode m2 : 10|1@1+ (1,0) [0|1] ""  Receiver
 SG_ VCRIGHT_hvacIntakePosition m1 : 56|8@1+ (0.4,0) [0|100] "%"  Receiver
 SG_ VCRIGHT_hvacIntakeTarget m0 : 56|8@1+ (0.4,0) [0|100] "%"  Receiver
 SG_ VCRIGHT_hvacLHBleedActuatorState m2 : 11|2@1+ (1,0) [0|2] ""  Receiver
 SG_ VCRIGHT_hvacLHBleedOperationMode m2 : 4|1@1+ (1,0) [0|1] ""  Receiver
 SG_ VCRIGHT_hvacLHBleedPosition m1 : 8|8@1+ (0.4,0) [0|100] "%"  Receiver
 SG_ VCRIGHT_hvacLHBleedTarget m0 : 8|8@1+ (0.4,0) [0|100] "%"  Receiver
 SG_ VCRIGHT_hvacLHVaneActuatorState m2 : 16|2@1+ (1,0) [0|2] ""  Receiver
 SG_ VCRIGHT_hvacLHVaneOperationMode m2 : 6|1@1+ (1,0) [0|1] ""  Receiver
 SG_ VCRIGHT_hvacLHVanePosition m1 : 24|8@1+ (0.4,0) [0|100] "%"  Receiver
 SG_ VCRIGHT_hvacLHVaneTarget m0 : 24|8@1+ (0.4,0) [0|100] "%"  Receiver
 SG_ VCRIGHT_hvacLowerModeActState m2 : 22|2@1+ (1,0) [0|2] ""  Receiver
 SG_ VCRIGHT_hvacLowerModeOpMode m2 : 9|1@1+ (1,0) [0|1] ""  Receiver
 SG_ VCRIGHT_hvacLowerModePosition m1 : 48|8@1+ (0.4,0) [0|100] "%"  Receiver
 SG_ VCRIGHT_hvacLowerModeTarget m0 : 48|8@1+ (0.4,0) [0|100] "%"  Receiver
 SG_ VCRIGHT_hvacRHBleedActuatorState m2 : 13|2@1+ (1,0) [0|2] ""  Receiver
 SG_ VCRIGHT_hvacRHBleedOperationMode m2 : 5|1@1+ (1,0) [0|1] ""  Receiver
 SG_ VCRIGHT_hvacRHBleedPosition m1 : 16|8@1+ (0.4,0) [0|100] "%"  Receiver
 SG_ VCRIGHT_hvacRHBleedTarget m0 : 16|8@1+ (0.4,0) [0|100] "%"  Receiver
 SG_ VCRIGHT_hvacRHVaneActuatorState m2 : 18|2@1+ (1,0) [0|2] ""  Receiver
 SG_ VCRIGHT_hvacRHVaneOperationMode m2 : 7|1@1+ (1,0) [0|1] ""  Receiver
 SG_ VCRIGHT_hvacRHVanePosition m1 : 32|8@1+ (0.4,0) [0|100] "%"  Receiver
 SG_ VCRIGHT_hvacRHVaneTarget m0 : 32|8@1+ (0.4,0) [0|100] "%"  Receiver
 SG_ VCRIGHT_hvacUpperModeActState m2 : 20|2@1+ (1,0) [0|2] ""  Receiver
 SG_ VCRIGHT_hvacUpperModeOpMode m2 : 8|1@1+ (1,0) [0|1] ""  Receiver
 SG_ VCRIGHT_hvacUpperModePosition m1 : 40|8@1+ (0.4,0) [0|100] "%"  Receiver
 SG_ VCRIGHT_hvacUpperModeTarget m0 : 40|8@1+ (0.4,0) [0|100] "%"  Receiver
 SG_ VCRIGHT_timeLeftToCabinModelInit m2 : 32|7@1+ (1,0) [0|127] ""  Receiver

BO_ 691 VCRIGHT_logging1Hz: 8 VEH
 SG_ VCRIGHT_logging1HzIndex M : 0|4@1+ (1,0) [0|11] "" X
 SG_ VCRIGHT_LHPanelAirflowBlocked m3 : 54|1@1+ (1,0) [0|1] "" X
 SG_ VCRIGHT_RHPanelAirflowBlocked m3 : 55|1@1+ (1,0) [0|1] "" X
 SG_ VCRIGHT_cabinTempBreathLevel m1 : 56|8@1+ (0.5,-40) [-40|80] "C" X
 SG_ VCRIGHT_cabinTempFanCurrent m9 : 15|6@1- (0.001,0) [-0.01|0.05] "A" X
 SG_ VCRIGHT_cabinTempFanOutput m9 : 14|1@1+ (1,0) [0|1] "" X
 SG_ VCRIGHT_cabinTempGlassRoof m1 : 8|8@1+ (0.5,-40) [-40|80] "C" X
 SG_ VCRIGHT_cabinTempInterior m1 : 24|8@1+ (0.5,-40) [-40|80] "C" X
 SG_ VCRIGHT_cabinTempInteriorL2 m0 : 24|8@1+ (0.5,-40) [-40|80] "C" X
 SG_ VCRIGHT_cabinTempInteriorL3 m9 : 40|8@1+ (0.5,-40) [-40|80] "C" X
 SG_ VCRIGHT_cabinTempInteriorSunny m1 : 32|8@1+ (0.6,-40) [-40|100] "C" X
 SG_ VCRIGHT_cabinTempInteriorSunnyL2 m0 : 40|8@1+ (0.6,-40) [-40|100] "C" X
 SG_ VCRIGHT_cabinTempInteriorSunnyL3 m9 : 48|8@1+ (0.6,-40) [-40|100] "C" X
 SG_ VCRIGHT_cabinTempSideGlassLeft m1 : 40|8@1+ (0.5,-40) [-40|80] "C" X
 SG_ VCRIGHT_cabinTempSideGlassRight m1 : 48|8@1+ (0.5,-40) [-40|80] "C" X
 SG_ VCRIGHT_cabinTempTopPadAir m9 : 56|8@1+ (0.6,-40) [-40|100] "C" X
 SG_ VCRIGHT_cabinTempWindshield m1 : 16|8@1+ (0.5,-40) [-40|80] "C" X
 SG_ VCRIGHT_cloudinessProbability m9 : 33|7@1+ (1,0) [0|100] "%" X
 SG_ VCRIGHT_convectionDeliveredLeft m4 : 24|8@1+ (2,-254) [-254|256] "W/m2" X
 SG_ VCRIGHT_convectionDeliveredRight m4 : 32|8@1+ (2,-254) [-254|256] "W/m2" X
 SG_ VCRIGHT_convectionTargetLeft m4 : 8|8@1+ (2,-254) [-254|256] "W/m2" X
 SG_ VCRIGHT_convectionTargetRight m4 : 16|8@1+ (2,-254) [-254|256] "W/m2" X
 SG_ VCRIGHT_defrostAirflowBlocked m3 : 57|1@1+ (1,0) [0|1] "" X
 SG_ VCRIGHT_evapCondensationRate m10 : 47|9@1- (0.007,0) [-1|1] "g/s" X
 SG_ VCRIGHT_evapDryingRoutineRuntime m10 : 56|5@1+ (2,0) [0|60] "" X
 SG_ VCRIGHT_evapLoadInFresh m5 : 32|8@1+ (35,0) [0|8000] "W" X
 SG_ VCRIGHT_evapLoadInRecirc m5 : 40|8@1+ (35,0) [0|8000] "W" X
 SG_ VCRIGHT_evapWaterMass m10 : 40|7@1+ (6,0) [0|380] "Grams" X
 SG_ VCRIGHT_filterLifeBlowerTorque m9 : 4|10@1+ (0.006,-1.5) [-1.5|4.5] "Nm" X
 SG_ VCRIGHT_floorAirflowBlocked m3 : 56|1@1+ (1,0) [0|1] "" X
 SG_ VCRIGHT_hvacAirFlowModeRow1 m3 : 29|3@1+ (1,0) [0|7] "" X
 SG_ VCRIGHT_hvacAirFlowModeRow2 m3 : 32|3@1+ (1,0) [0|7] "" X
 SG_ VCRIGHT_hvacAirflowReason m3 : 48|4@1+ (1,0) [0|14] "" X
 SG_ VCRIGHT_hvacAutoTransitionReason m3 : 24|5@1+ (1,0) [0|19] "" X
 SG_ VCRIGHT_hvacCabOvrheatProtActive m9 : 30|1@1+ (1,0) [0|1] "" X
 SG_ VCRIGHT_hvacCabOvrheatProtAllowe m9 : 32|1@1+ (1,0) [0|1] "" X
 SG_ VCRIGHT_hvacCabinPurgeActive m9 : 29|1@1+ (1,0) [0|1] "" X
 SG_ VCRIGHT_hvacCabinPurgeAllowed m9 : 31|1@1+ (1,0) [0|1] "" X
 SG_ VCRIGHT_hvacIntakeEndStop m7 : 56|8@1+ (0.02,0) [0|5] "V" X
 SG_ VCRIGHT_hvacIntakeVoltage m6 : 56|8@1+ (0.02,0) [0|5] "V" X
 SG_ VCRIGHT_hvacIntakeZeroStop m8 : 56|8@1+ (0.02,0) [0|5] "V" X
 SG_ VCRIGHT_hvacLHBleedEndStop m7 : 8|8@1+ (0.02,0) [0|5] "V" X
 SG_ VCRIGHT_hvacLHBleedVoltage m6 : 8|8@1+ (0.02,0) [0|5] "V" X
 SG_ VCRIGHT_hvacLHBleedZeroStop m8 : 8|8@1+ (0.02,0) [0|5] "V" X
 SG_ VCRIGHT_hvacLHVaneEndStop m7 : 24|8@1+ (0.02,0) [0|5] "V" X
 SG_ VCRIGHT_hvacLHVaneVoltage m6 : 24|8@1+ (0.02,0) [0|5] "V" X
 SG_ VCRIGHT_hvacLHVaneZeroStop m8 : 24|8@1+ (0.02,0) [0|5] "V" X
 SG_ VCRIGHT_hvacLowerModeEndStop m7 : 48|8@1+ (0.02,0) [0|5] "V" X
 SG_ VCRIGHT_hvacLowerModeVoltage m6 : 48|8@1+ (0.02,0) [0|5] "V" X
 SG_ VCRIGHT_hvacLowerModeZeroStop m8 : 48|8@1+ (0.02,0) [0|5] "V" X
 SG_ VCRIGHT_hvacMassflowTarget m3 : 40|8@1+ (1,0) [0|200] "g/s" X
 SG_ VCRIGHT_hvacQdotFeedforward m5 : 16|16@1+ (1,-32767) [-32767|32767] "W" X
 SG_ VCRIGHT_hvacQdotLimitedLeft m3 : 52|1@1+ (1,0) [0|1] "" X
 SG_ VCRIGHT_hvacQdotLimitedRight m3 : 53|1@1+ (1,0) [0|1] "" X
 SG_ VCRIGHT_hvacRHBleedEndStop m7 : 16|8@1+ (0.02,0) [0|5] "V" X
 SG_ VCRIGHT_hvacRHBleedVoltage m6 : 16|8@1+ (0.02,0) [0|5] "V" X
 SG_ VCRIGHT_hvacRHBleedZeroStop m8 : 16|8@1+ (0.02,0) [0|5] "V" X
 SG_ VCRIGHT_hvacRHVaneEndStop m7 : 32|8@1+ (0.02,0) [0|5] "V" X
 SG_ VCRIGHT_hvacRHVaneVoltage m6 : 32|8@1+ (0.02,0) [0|5] "V" X
 SG_ VCRIGHT_hvacRHVaneZeroStop m8 : 32|8@1+ (0.02,0) [0|5] "V" X
 SG_ VCRIGHT_hvacSetTempActualLeft m3 : 8|8@1+ (0.1,15) [15|28] "C" X
 SG_ VCRIGHT_hvacSetTempActualRight m3 : 16|8@1+ (0.1,15) [15|28] "C" X
 SG_ VCRIGHT_hvacUpperModeEndStop m7 : 40|8@1+ (0.02,0) [0|5] "V" X
 SG_ VCRIGHT_hvacUpperModeVoltage m6 : 40|8@1+ (0.02,0) [0|5] "V" X
 SG_ VCRIGHT_hvacUpperModeZeroStop m8 : 40|8@1+ (0.02,0) [0|5] "V" X
 SG_ VCRIGHT_leftHeatOvertempProtect m10 : 61|1@1+ (1,0) [0|1] "" X
 SG_ VCRIGHT_pcbaTemperature m2 : 4|11@1+ (0.125,-40) [-40|150] "C" X
 SG_ VCRIGHT_ptcHeaterHvacActNotReady m5 : 7|1@1+ (1,0) [0|1] "" X
 SG_ VCRIGHT_ptcHeaterLAirPathBlocked m5 : 10|1@1+ (1,0) [0|1] "" X
 SG_ VCRIGHT_ptcHeaterNoAirflow m5 : 6|1@1+ (1,0) [0|1] "" X
 SG_ VCRIGHT_ptcHeaterNoHighVoltage m5 : 9|1@1+ (1,0) [0|1] "" X
 SG_ VCRIGHT_ptcHeaterNoUiRequest m5 : 8|1@1+ (1,0) [0|1] "" X
 SG_ VCRIGHT_ptcHeaterPwrDemandLeft m2 : 40|8@1+ (20,0) [0|5000] "W" X
 SG_ VCRIGHT_ptcHeaterPwrDemandRight m2 : 48|8@1+ (20,0) [0|5000] "W" X
 SG_ VCRIGHT_ptcHeaterRAirPathBlocked m5 : 11|1@1+ (1,0) [0|1] "" X
 SG_ VCRIGHT_ptcHeaterReqAirpathBlock m5 : 12|1@1+ (1,0) [0|1] "" X
 SG_ VCRIGHT_ptcHeaterTempDuctFault m5 : 5|1@1+ (1,0) [0|1] "" X
 SG_ VCRIGHT_ptcHeaterTempDuctHigh m5 : 4|1@1+ (1,0) [0|1] "" X
 SG_ VCRIGHT_rightHeatOvertempProtect m10 : 62|1@1+ (1,0) [0|1] "" X
 SG_ VCRIGHT_solarLoadLeftOccupant m4 : 48|7@1+ (2,0) [0|254] "W/m2" X
 SG_ VCRIGHT_solarLoadOnVehFiltered m9 : 21|8@1+ (4,0) [0|1020] "W/m2" X
 SG_ VCRIGHT_solarLoadOnVehicle m4 : 56|8@1+ (4,0) [0|1020] "W/m2" X
 SG_ VCRIGHT_solarLoadRightOccupant m4 : 40|7@1+ (2,0) [0|254] "W/m2" X
 SG_ VCRIGHT_tempDuctModeledLeft m10 : 4|9@1+ (0.3,-40) [-40|105] "C" X
 SG_ VCRIGHT_tempDuctModeledRight m10 : 13|9@1+ (0.3,-40) [-40|105] "C" X
 SG_ VCRIGHT_tempHtrSurfaceModeledL m10 : 22|9@1+ (0.3,-40) [-40|105] "C" X
 SG_ VCRIGHT_tempHtrSurfaceModeledR m10 : 31|9@1+ (0.3,-40) [-40|105] "C" X
 SG_ VCRIGHT_tempIncarCabinDeep m0 : 16|8@1+ (0.5,-40) [-40|85] "C" X
 SG_ VCRIGHT_tempIncarCabinMid m0 : 32|8@1+ (0.5,-40) [-40|85] "C" X
 SG_ VCRIGHT_tempIncarCabinProbe m0 : 8|8@1+ (0.5,-40) [-40|85] "C" X
 SG_ VCRIGHT_wattsHeaterLeftTotal m2 : 16|10@1+ (5,0) [0|4000] "W" X
 SG_ VCRIGHT_wattsHeaterRightTotal m2 : 26|10@1+ (5,0) [0|4000] "W" X

BO_ 1859 VCRIGHT_recallStatus: 1 VEH
 SG_ VCRIGHT_mirrorRecallStatus: 4|2@1+ (1,0) [0|0] "" X
 SG_ VCRIGHT_seatRecallStatus: 2|2@1+ (1,0) [0|0] "" X
 SG_ VCRIGHT_systemRecallStatus: 0|2@1+ (1,0) [0|0] "" X

BO_ 794 VCRIGHT_restraintStatus: 4 VEH
 SG_ VCRIGHT_frontBuckleStatus: 3|2@1+ (1,0) [0|0] "" X
 SG_ VCRIGHT_frontOccupancyStatus: 0|3@1+ (1,0) [0|0] "" X
 SG_ VCRIGHT_rearCenterBuckleStatus: 5|2@1+ (1,0) [0|0] "" X
 SG_ VCRIGHT_rearRightBuckleStatus: 8|2@1+ (1,0) [0|0] "" X
 SG_ VCRIGHT_restraintStatusChecksum: 24|8@1+ (1,0) [0|0] "" X
 SG_ VCRIGHT_restraintStatusCounter: 20|4@1+ (1,0) [0|0] "" X

BO_ 1251 VCRIGHT_seatStatus: 8 VEH
 SG_ VCRIGHT_seatStatusIndex M: 0|3@1+ (1,0) [0|0] "" X
 SG_ VCRIGHT_frontSeatTrackPos m0: 8|16@1- (1,0) [0|0] "" X
 SG_ VCRIGHT_frontSeatTrackCurrent m0: 24|12@1- (0.01,0) [0|0] "A" X
 SG_ VCRIGHT_frontSeatTrackDuty m0: 36|12@1- (0.1,0) [0|0] "%" X
 SG_ VCRIGHT_frontSeatTrackState m0: 48|3@1+ (1,0) [0|0] "" X
 SG_ VCRIGHT_frontSeatTrackCalibrated m0: 51|1@1+ (1,0) [0|0] "" X
 SG_ VCRIGHT_frontSeatTrackLog m0: 52|1@1+ (1,0) [0|0] "" X
 SG_ VCRIGHT_frontSeatBackPos m1: 8|16@1- (1,0) [0|0] "" X
 SG_ VCRIGHT_frontSeatBackCurrent m1: 24|12@1- (0.01,0) [0|0] "A" X
 SG_ VCRIGHT_frontSeatBackDuty m1: 36|12@1- (0.1,0) [0|0] "%" X
 SG_ VCRIGHT_frontSeatBackState m1: 48|3@1+ (1,0) [0|0] "" X
 SG_ VCRIGHT_frontSeatBackCalibrated m1: 51|1@1+ (1,0) [0|0] "" X
 SG_ VCRIGHT_frontSeatBackLog m1: 52|1@1+ (1,0) [0|0] "" X
 SG_ VCRIGHT_frontSeatLiftPos m2: 8|16@1- (1,0) [0|0] "" X
 SG_ VCRIGHT_frontSeatLiftCurrent m2: 24|12@1- (0.01,0) [0|0] "A" X
 SG_ VCRIGHT_frontSeatLiftDuty m2: 36|12@1- (0.1,0) [0|0] "%" X
 SG_ VCRIGHT_frontSeatLiftState m2: 48|3@1+ (1,0) [0|0] "" X
 SG_ VCRIGHT_frontSeatLiftCalibrated m2: 51|1@1+ (1,0) [0|0] "" X
 SG_ VCRIGHT_frontSeatLiftLog m2: 52|1@1+ (1,0) [0|0] "" X
 SG_ VCRIGHT_frontSeatTiltPos m3: 8|16@1- (1,0) [0|0] "" X
 SG_ VCRIGHT_frontSeatTiltCurrent m3: 24|12@1- (0.01,0) [0|0] "A" X
 SG_ VCRIGHT_frontSeatTiltDuty m3: 36|12@1- (0.1,0) [0|0] "%" X
 SG_ VCRIGHT_frontSeatTiltState m3: 48|3@1+ (1,0) [0|0] "" X
 SG_ VCRIGHT_frontSeatTiltCalibrated m3: 51|1@1+ (1,0) [0|0] "" X
 SG_ VCRIGHT_frontSeatTiltLog m3: 52|1@1+ (1,0) [0|0] "" X
 SG_ VCRIGHT_lumbarAState m4: 3|3@1+ (1,0) [0|0] "" X
 SG_ VCRIGHT_lumbarBState m4: 8|3@1+ (1,0) [0|0] "" X
 SG_ VCRIGHT_lumbarAPressureHpa m4: 16|16@1+ (1,0) [0|0] "" X
 SG_ VCRIGHT_lumbarBPressureHpa m4: 32|16@1+ (1,0) [0|0] "" X
 SG_ VCRIGHT_lumbarActiveTooLongErr m4: 48|1@1+ (1,0) [0|0] "" X
 SG_ VCRIGHT_lumbarMaxPErr m4: 49|1@1+ (1,0) [0|0] "" X
 SG_ VCRIGHT_lumbarOvercurrentErr m4: 50|1@1+ (1,0) [0|0] "" X
 SG_ VCRIGHT_lumbarMaxOperatingPErr m4: 51|1@1+ (1,0) [0|0] "" X
 SG_ VCRIGHT_lumbarMinPErr m4: 52|1@1+ (1,0) [0|0] "" X
 SG_ VCRIGHT_lumbarGeneralErr m4: 53|1@1+ (1,0) [0|0] "" X
 SG_ VCRIGHT_lumbarDevMaxPumpPressA m4: 54|1@1+ (1,0) [0|0] "" X
 SG_ VCRIGHT_lumbarDevMaxPumpPressB m4: 55|1@1+ (1,0) [0|0] "" X
 SG_ VCRIGHT_frontSeatTrackPosReal m5: 3|12@1- (1,0) [0|0] "mm" X
 SG_ VCRIGHT_frontSeatBackPosReal m5: 16|12@1- (0.1,0) [0|0] "deg" X
 SG_ VCRIGHT_frontSeatLiftPosReal m5: 28|12@1- (1,0) [0|0] "mm" X
 SG_ VCRIGHT_frontSeatTiltPosReal m5: 40|12@1- (0.1,0) [0|0] "deg" X

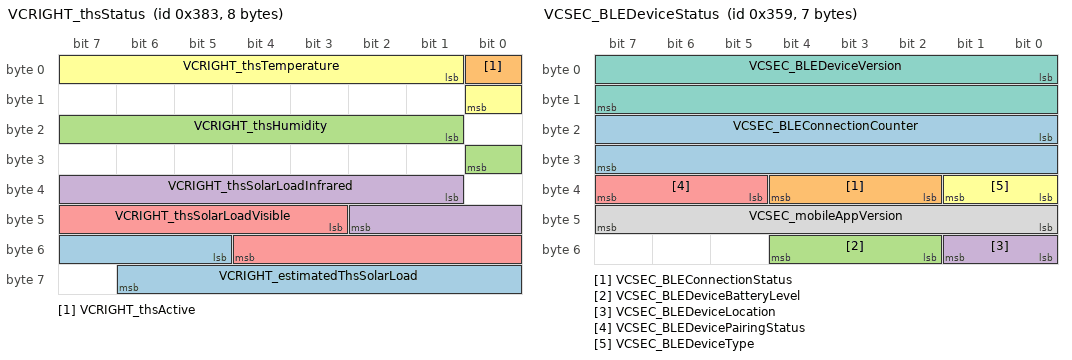
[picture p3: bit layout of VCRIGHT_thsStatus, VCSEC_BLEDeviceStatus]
BO_ 899 VCRIGHT_thsStatus: 8 VEH
 SG_ VCRIGHT_estimatedThsSolarLoad: 53|10@1+ (1,0) [0|0] "W/m2" X
 SG_ VCRIGHT_thsActive: 0|1@1+ (1,0) [0|0] "" X
 SG_ VCRIGHT_thsHumidity: 17|8@1+ (1,0) [0|0] "%" X
 SG_ VCRIGHT_thsSolarLoadInfrared: 33|10@1+ (1,0) [0|0] "W/m2" X
 SG_ VCRIGHT_thsSolarLoadVisible: 43|10@1+ (1,0) [0|0] "W/m2" X
 SG_ VCRIGHT_thsTemperature: 1|8@1- (1,-40) [0|0] "degC" X

BO_ 857 VCSEC_BLEDeviceStatus: 7 VEH
 SG_ VCSEC_BLEConnectionCounter: 16|16@1+ (1,0) [0|0] "" X
 SG_ VCSEC_BLEConnectionStatus: 34|3@1+ (1,0) [0|0] "" X
 SG_ VCSEC_BLEDeviceBatteryLevel: 50|3@1+ (1,0) [0|0] "" X
 SG_ VCSEC_BLEDeviceLocation: 48|2@1+ (1,0) [0|0] "" X
 SG_ VCSEC_BLEDevicePairingStatus: 37|3@1+ (1,0) [0|0] "" X
 SG_ VCSEC_BLEDeviceType: 32|2@1+ (1,0) [0|0] "" X
 SG_ VCSEC_BLEDeviceVersion: 0|16@1+ (1,0) [0|0] "" X
 SG_ VCSEC_mobileAppVersion: 40|8@1+ (1,0) [0|0] "" X

BO_ 969 VCSEC_BLEEndpointInfo: 8 VEH
 SG_ VCSEC_BLEEndpointInfoIndex M: 0|3@1+ (1,0) [0|0] "" X
 SG_ VCSEC_BLELEFTCrc m0: 8|32@1+ (1,0) [0|0] "" X
 SG_ VCSEC_BLELEFTComponentID m0: 40|16@1+ (1,0) [0|0] "" X
 SG_ VCSEC_BLELEFTPcbaID m0: 56|8@1+ (1,0) [0|0] "" X
 SG_ VCSEC_BLERIGHTCrc m1: 8|32@1+ (1,0) [0|0] "" X
 SG_ VCSEC_BLERIGHTComponentID m1: 40|16@1+ (1,0) [0|0] "" X
 SG_ VCSEC_BLERIGHTPcbaID m1: 56|8@1+ (1,0) [0|0] "" X
 SG_ VCSEC_BLEREARCrc m2: 8|32@1+ (1,0) [0|0] "" X
 SG_ VCSEC_BLEREARComponentID m2: 40|16@1+ (1,0) [0|0] "" X
 SG_ VCSEC_BLEREARPcbaID m2: 56|8@1+ (1,0) [0|0] "" X
 SG_ VCSEC_BLECENTERCrc m3: 8|32@1+ (1,0) [0|0] "" X
 SG_ VCSEC_BLECENTERComponentID m3: 40|16@1+ (1,0) [0|0] "" X
 SG_ VCSEC_BLECENTERPcbaID m3: 56|8@1+ (1,0) [0|0] "" X
 SG_ VCSEC_BLELEFTAppGitHashByte m4: 10|54@1+ (4,0) [0|0] "" X
 SG_ VCSEC_BLERIGHTAppGitHashByte m5: 10|54@1+ (4,0) [0|0] "" X
 SG_ VCSEC_BLEREARAppGitHashByte m6: 10|54@1+ (4,0) [0|0] "" X
 SG_ VCSEC_BLECENTERAppGitHashByte m7: 10|54@1+ (4,0) [0|0] "" X

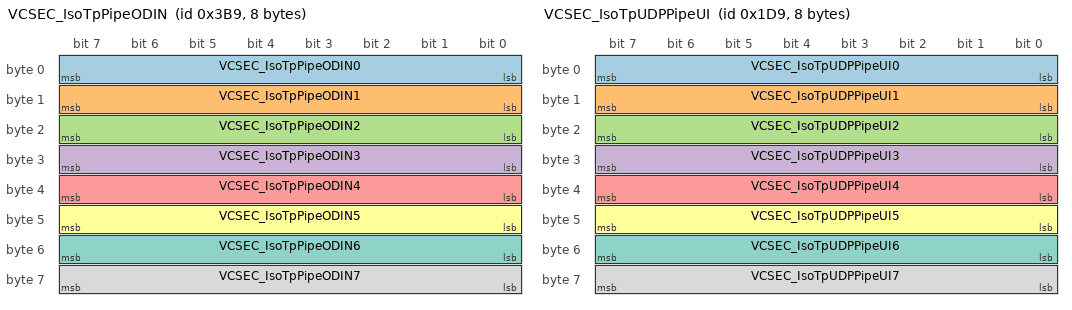
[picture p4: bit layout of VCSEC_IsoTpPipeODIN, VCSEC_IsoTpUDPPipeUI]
BO_ 953 VCSEC_IsoTpPipeODIN: 8 VEH
 SG_ VCSEC_IsoTpPipeODIN0: 0|8@1+ (1,0) [0|0] "" X
 SG_ VCSEC_IsoTpPipeODIN1: 8|8@1+ (1,0) [0|0] "" X
 SG_ VCSEC_IsoTpPipeODIN2: 16|8@1+ (1,0) [0|0] "" X
 SG_ VCSEC_IsoTpPipeODIN3: 24|8@1+ (1,0) [0|0] "" X
 SG_ VCSEC_IsoTpPipeODIN4: 32|8@1+ (1,0) [0|0] "" X
 SG_ VCSEC_IsoTpPipeODIN5: 40|8@1+ (1,0) [0|0] "" X
 SG_ VCSEC_IsoTpPipeODIN6: 48|8@1+ (1,0) [0|0] "" X
 SG_ VCSEC_IsoTpPipeODIN7: 56|8@1+ (1,0) [0|0] "" X

BO_ 473 VCSEC_IsoTpUDPPipeUI: 8 VEH
 SG_ VCSEC_IsoTpUDPPipeUI0: 0|8@1+ (1,0) [0|0] "" X
 SG_ VCSEC_IsoTpUDPPipeUI1: 8|8@1+ (1,0) [0|0] "" X
 SG_ VCSEC_IsoTpUDPPipeUI2: 16|8@1+ (1,0) [0|0] "" X
 SG_ VCSEC_IsoTpUDPPipeUI3: 24|8@1+ (1,0) [0|0] "" X
 SG_ VCSEC_IsoTpUDPPipeUI4: 32|8@1+ (1,0) [0|0] "" X
 SG_ VCSEC_IsoTpUDPPipeUI5: 40|8@1+ (1,0) [0|0] "" X
 SG_ VCSEC_IsoTpUDPPipeUI6: 48|8@1+ (1,0) [0|0] "" X
 SG_ VCSEC_IsoTpUDPPipeUI7: 56|8@1+ (1,0) [0|0] "" X

BO_ 1017 VCSEC_alertMatrix: 8 VEH
 SG_ VCSEC_matrixIndex M: 0|4@1+ (1,0) [0|0] "" X
 SG_ VCSEC_a001_WatchdogReset m0: 4|1@1+ (1,0) [0|0] "" X
 SG_ VCSEC_a002_PowerLossReset m0: 5|1@1+ (1,0) [0|0] "" X
 SG_ VCSEC_a003_SWAssertion m0: 6|1@1+ (1,0) [0|0] "" X
 SG_ VCSEC_a010_ExtSupplyVoltError m0: 13|1@1+ (1,0) [0|0] "" X
 SG_ VCSEC_a012_CPUReset m0: 15|1@1+ (1,0) [0|0] "" X
 SG_ VCSEC_a013_AlertManagerFault m0: 16|1@1+ (1,0) [0|0] "" X
 SG_ VCSEC_a015_NVMMAlert m0: 18|1@1+ (1,0) [0|0] "" X
 SG_ VCSEC_a021_TaskSchedulerError m0: 24|1@1+ (1,0) [0|0] "" X
 SG_ VCSEC_a022_TaskInitError m0: 25|1@1+ (1,0) [0|0] "" X
 SG_ VCSEC_a031_UDSActive m0: 34|1@1+ (1,0) [0|0] "" X
 SG_ VCSEC_a041_HighCPULoad m0: 44|1@1+ (1,0) [0|0] "" X
 SG_ VCSEC_a042_HighStackUsage m0: 45|1@1+ (1,0) [0|0] "" X
 SG_ VCSEC_a043_Task1msError m0: 46|1@1+ (1,0) [0|0] "" X
 SG_ VCSEC_a044_Task10msError m0: 47|1@1+ (1,0) [0|0] "" X
 SG_ VCSEC_a045_Task100msError m0: 48|1@1+ (1,0) [0|0] "" X
 SG_ VCSEC_a046_Task1000msError m0: 49|1@1+ (1,0) [0|0] "" X
 SG_ VCSEC_a059_inputResistanceHigh m0: 62|1@1+ (1,0) [0|0] "" X
 SG_ VCSEC_a060_engineeringBuild m0: 63|1@1+ (1,0) [0|0] "" X
 SG_ VCSEC_a061_XCPConnected m1: 4|1@1+ (1,0) [0|0] "" X
 SG_ VCSEC_a062_XCPWasConnected m1: 5|1@1+ (1,0) [0|0] "" X
 SG_ VCSEC_a063_SwitchFault m1: 6|1@1+ (1,0) [0|0] "" X
 SG_ VCSEC_a064_busSleepReqTimeout m1: 7|1@1+ (1,0) [0|0] "" X
 SG_ VCSEC_a097_CMP_MIA m1: 40|1@1+ (1,0) [0|0] "" X
 SG_ VCSEC_a098_DI_THERMAL_MIA m1: 41|1@1+ (1,0) [0|0] "" X
 SG_ VCSEC_a099_PARK_MIA m1: 42|1@1+ (1,0) [0|0] "" X
 SG_ VCSEC_a100_CANbus_MIA m1: 43|1@1+ (1,0) [0|0] "" X
 SG_ VCSEC_a101_PM_MIA m1: 44|1@1+ (1,0) [0|0] "" X
 SG_ VCSEC_a102_PTC_MIA m1: 45|1@1+ (1,0) [0|0] "" X
 SG_ VCSEC_a103_CP_MIA m1: 46|1@1+ (1,0) [0|0] "" X
 SG_ VCSEC_a104_DAS_MIA m1: 47|1@1+ (1,0) [0|0] "" X
 SG_ VCSEC_a105_TAS_MIA m1: 48|1@1+ (1,0) [0|0] "" X
 SG_ VCSEC_a106_PCS_MIA m1: 49|1@1+ (1,0) [0|0] "" X
 SG_ VCSEC_a107_BMS_MIA m1: 50|1@1+ (1,0) [0|0] "" X
 SG_ VCSEC_a108_DIS_MIA m1: 51|1@1+ (1,0) [0|0] "" X
 SG_ VCSEC_a109_RCM_MIA m1: 52|1@1+ (1,0) [0|0] "" X
 SG_ VCSEC_a110_GTW_MIA m1: 53|1@1+ (1,0) [0|0] "" X
 SG_ VCSEC_a111_EPBR_MIA m1: 54|1@1+ (1,0) [0|0] "" X
 SG_ VCSEC_a112_EPBL_MIA m1: 55|1@1+ (1,0) [0|0] "" X
 SG_ VCSEC_a113_UI_MIA m1: 56|1@1+ (1,0) [0|0] "" X
 SG_ VCSEC_a114_ESP_MIA m1: 57|1@1+ (1,0) [0|0] "" X
 SG_ VCSEC_a115_VCSEC_MIA m1: 58|1@1+ (1,0) [0|0] "" X
 SG_ VCSEC_a116_VCRIGHT_MIA m1: 59|1@1+ (1,0) [0|0] "" X
 SG_ VCSEC_a117_VCLEFT_MIA m1: 60|1@1+ (1,0) [0|0] "" X
 SG_ VCSEC_a118_VCFRONT_MIA m1: 61|1@1+ (1,0) [0|0] "" X
 SG_ VCSEC_a119_SCCM_MIA m1: 62|1@1+ (1,0) [0|0] "" X
 SG_ VCSEC_a120_DI_DRIVE_MIA m1: 63|1@1+ (1,0) [0|0] "" X
 SG_ VCSEC_a133_alarmTriggered m2: 16|1@1+ (1,0) [0|0] "" X
 SG_ VCSEC_a134_badCertificate m2: 17|1@1+ (1,0) [0|0] "" X
 SG_ VCSEC_a135_centerEndpointMIA m2: 18|1@1+ (1,0) [0|0] "" X
 SG_ VCSEC_a136_leftEndpointMIA m2: 19|1@1+ (1,0) [0|0] "" X
 SG_ VCSEC_a137_rightEndpointMIA m2: 20|1@1+ (1,0) [0|0] "" X
 SG_ VCSEC_a138_rearEndpointMIA m2: 21|1@1+ (1,0) [0|0] "" X
 SG_ VCSEC_a140_nfcAuthentication m2: 23|1@1+ (1,0) [0|0] "" X
 SG_ VCSEC_a141_tooFewKeysOnWhitelist m2: 24|1@1+ (1,0) [0|0] "" X
 SG_ VCSEC_a142_bleGattAlertC m2: 25|1@1+ (1,0) [0|0] "" X
 SG_ VCSEC_a143_bleGattAlertL m2: 26|1@1+ (1,0) [0|0] "" X
 SG_ VCSEC_a144_bleGattAlertR m2: 27|1@1+ (1,0) [0|0] "" X
 SG_ VCSEC_a145_bleGattAlertRe m2: 28|1@1+ (1,0) [0|0] "" X
 SG_ VCSEC_a147_protobufRXTimeout m2: 30|1@1+ (1,0) [0|0] "" X
 SG_ VCSEC_a148_keyWhitelistFull m2: 31|1@1+ (1,0) [0|0] "" X
 SG_ VCSEC_a149_attrsWentMissingL m2: 32|1@1+ (1,0) [0|0] "" X
 SG_ VCSEC_a150_attrsWentMissingR m2: 33|1@1+ (1,0) [0|0] "" X
 SG_ VCSEC_a151_attrsWentMissingRe m2: 34|1@1+ (1,0) [0|0] "" X
 SG_ VCSEC_a153_srvcCmdTimeoutC m2: 36|1@1+ (1,0) [0|0] "" X
 SG_ VCSEC_a154_srvcCmdTimeoutL m2: 37|1@1+ (1,0) [0|0] "" X
 SG_ VCSEC_a155_srvcCmdTimeoutR m2: 38|1@1+ (1,0) [0|0] "" X
 SG_ VCSEC_a156_srvcCmdTimeoutRe m2: 39|1@1+ (1,0) [0|0] "" X
 SG_ VCSEC_a158_hciFaultC m2: 41|1@1+ (1,0) [0|0] "" X
 SG_ VCSEC_a159_hciFaultL m2: 42|1@1+ (1,0) [0|0] "" X
 SG_ VCSEC_a161_hciFaultR m2: 44|1@1+ (1,0) [0|0] "" X
 SG_ VCSEC_a162_hciFaultRe m2: 45|1@1+ (1,0) [0|0] "" X
 SG_ VCSEC_a164_attrsWentMissingC m2: 47|1@1+ (1,0) [0|0] "" X
 SG_ VCSEC_a165_ephemeralKeyGenerated m2: 48|1@1+ (1,0) [0|0] "" X
 SG_ VCSEC_a166_BLECenterPowerCycled m2: 49|1@1+ (1,0) [0|0] "" X
 SG_ VCSEC_a167_BLECenterSoftReset m2: 50|1@1+ (1,0) [0|0] "" X
 SG_ VCSEC_a168_BLELeftSoftReset m2: 51|1@1+ (1,0) [0|0] "" X
 SG_ VCSEC_a169_BLERightSoftReset m2: 52|1@1+ (1,0) [0|0] "" X
 SG_ VCSEC_a170_BLERearSoftReset m2: 53|1@1+ (1,0) [0|0] "" X
 SG_ VCSEC_a172_BLEUnexpectedResetC m2: 55|1@1+ (1,0) [0|0] "" X
 SG_ VCSEC_a173_BLEUnexpectedResetL m2: 56|1@1+ (1,0) [0|0] "" X
 SG_ VCSEC_a174_BLEUnexpectedResetRi m2: 57|1@1+ (1,0) [0|0] "" X
 SG_ VCSEC_a175_BLEUnexpectedResetRe m2: 58|1@1+ (1,0) [0|0] "" X
 SG_ VCSEC_a177_whitelistAddedKey m2: 60|1@1+ (1,0) [0|0] "" X
 SG_ VCSEC_a178_whitelistRemovedKey m2: 61|1@1+ (1,0) [0|0] "" X
 SG_ VCSEC_a179_wlistAddedPermission m2: 62|1@1+ (1,0) [0|0] "" X
 SG_ VCSEC_a180_wlistRemovedPermission m2: 63|1@1+ (1,0) [0|0] "" X
 SG_ VCSEC_a181_signedMessageFault m3: 4|1@1+ (1,0) [0|0] "" X
 SG_ VCSEC_a182_cryptoHighStackUsage m3: 5|1@1+ (1,0) [0|0] "" X
 SG_ VCSEC_a183_centerEndpointRFMia m3: 6|1@1+ (1,0) [0|0] "" X
 SG_ VCSEC_a184_driverEndpointRFMia m3: 7|1@1+ (1,0) [0|0] "" X
 SG_ VCSEC_a185_passengerEndpointRFMia m3: 8|1@1+ (1,0) [0|0] "" X
 SG_ VCSEC_a186_rearEndpointRFMia m3: 9|1@1+ (1,0) [0|0] "" X
 SG_ VCSEC_a187_badConnectionDropped m3: 10|1@1+ (1,0) [0|0] "" X
 SG_ VCSEC_a188_protobufDecodeError m3: 11|1@1+ (1,0) [0|0] "" X
 SG_ VCSEC_a189_protoExpLengthTooLarge m3: 12|1@1+ (1,0) [0|0] "" X
 SG_ VCSEC_a190_protoTooManyBytes m3: 13|1@1+ (1,0) [0|0] "" X
 SG_ VCSEC_a191_macIDWlistingFailedC m3: 14|1@1+ (1,0) [0|0] "" X
 SG_ VCSEC_a192_macIDWlistingFailedL m3: 15|1@1+ (1,0) [0|0] "" X
 SG_ VCSEC_a193_macIDWlistingFailedRi m3: 16|1@1+ (1,0) [0|0] "" X
 SG_ VCSEC_a194_macIDWlistingFailedRe m3: 17|1@1+ (1,0) [0|0] "" X
 SG_ VCSEC_a195_keyMissingInDrive m3: 18|1@1+ (1,0) [0|0] "" X
 SG_ VCSEC_a196_protobufTXTimeout m3: 19|1@1+ (1,0) [0|0] "" X
 SG_ VCSEC_a197_indicationFault m3: 20|1@1+ (1,0) [0|0] "" X
 SG_ VCSEC_a198_BPillarNFCReaderMIA m3: 21|1@1+ (1,0) [0|0] "" X
 SG_ VCSEC_a199_CenterNFCReaderMIA m3: 22|1@1+ (1,0) [0|0] "" X
 SG_ VCSEC_a200_centerEndpointLostComm m3: 23|1@1+ (1,0) [0|0] "" X
 SG_ VCSEC_a201_leftEndpointLostComm m3: 24|1@1+ (1,0) [0|0] "" X
 SG_ VCSEC_a202_rightEndpointLostComm m3: 25|1@1+ (1,0) [0|0] "" X
 SG_ VCSEC_a203_rearEndpointLostComm m3: 26|1@1+ (1,0) [0|0] "" X
 SG_ VCSEC_a204_SharedSecretsWritten m3: 27|1@1+ (1,0) [0|0] "" X
 SG_ VCSEC_a205_MTUUpdateNotConfirmed m3: 28|1@1+ (1,0) [0|0] "" X
 SG_ VCSEC_a206_BLELeftAssertFailure m3: 29|1@1+ (1,0) [0|0] "" X
 SG_ VCSEC_a207_BLERightAssertFailure m3: 30|1@1+ (1,0) [0|0] "" X
 SG_ VCSEC_a208_BLERearAssertFailure m3: 31|1@1+ (1,0) [0|0] "" X
 SG_ VCSEC_a209_BLECenterAssertFailure m3: 32|1@1+ (1,0) [0|0] "" X

BO_ 825 VCSEC_authentication: 8 VEH
 SG_ VCSEC_MCUCommandType: 36|3@1+ (1,0) [0|0] "" X
 SG_ VCSEC_alarmStatus: 43|4@1+ (1,0) [0|0] "" X
 SG_ VCSEC_authRequested: 60|1@1+ (1,0) [0|0] "" X
 SG_ VCSEC_authenticationStatus: 16|2@1+ (1,0) [0|0] "" X
 SG_ VCSEC_chargePortLockStatus: 18|1@1+ (1,0) [0|0] "" X
 SG_ VCSEC_frunkRequest: 34|2@1+ (1,0) [0|0] "" X
 SG_ VCSEC_immobilizerState: 48|3@1+ (1,0) [0|0] "" X
 SG_ VCSEC_keyChannelIndexed: 56|4@1+ (1,0) [0|0] "" X
 SG_ VCSEC_leftFrontLockStatus: 19|1@1+ (1,0) [0|0] "" X
 SG_ VCSEC_leftRearLockStatus: 20|1@1+ (1,0) [0|0] "" X
 SG_ VCSEC_lockIndicationRequest: 51|3@1+ (1,0) [0|0] "" X
 SG_ VCSEC_lockRequestType: 24|5@1+ (1,0) [0|0] "" X
 SG_ VCSEC_numberOfPubKeysOnWhitelist: 6|5@1+ (1,0) [0|0] "" X
 SG_ VCSEC_prsntRsnDeltaD: 3|1@1+ (1,0) [0|0] "" X
 SG_ VCSEC_prsntRsnDeltaP: 39|1@1+ (1,0) [0|0] "" X
 SG_ VCSEC_prsntRsnDeltaR: 4|1@1+ (1,0) [0|0] "" X
 SG_ VCSEC_prsntRsnHighThresholdC: 0|1@1+ (1,0) [0|0] "" X
 SG_ VCSEC_prsntRsnHighThresholdD: 1|1@1+ (1,0) [0|0] "" X
 SG_ VCSEC_prsntRsnHighThresholdP: 2|1@1+ (1,0) [0|0] "" X
 SG_ VCSEC_prsntRsnHighThresholdR: 5|1@1+ (1,0) [0|0] "" X
 SG_ VCSEC_rightFrontLockStatus: 21|1@1+ (1,0) [0|0] "" X
 SG_ VCSEC_rightRearLockStatus: 22|1@1+ (1,0) [0|0] "" X
 SG_ VCSEC_simpleLockStatus: 54|2@1+ (1,0) [0|0] "" X
 SG_ VCSEC_summonRequest: 29|3@1+ (1,0) [0|0] "" X
 SG_ VCSEC_trunkLockStatus: 23|1@1+ (1,0) [0|0] "" X
 SG_ VCSEC_trunkRequest: 32|2@1+ (1,0) [0|0] "" X
 SG_ VCSEC_usingModifiedMACAddress: 40|1@1+ (1,0) [0|0] "" X
 SG_ VCSEC_vehicleLockStatus: 12|4@1+ (1,0) [0|0] "" X

BO_ 793 VCSEC_info: 8 VEH
 SG_ VCSEC_infoIndex M: 0|8@1+ (1,0) [0|0] "" X
 SG_ VCSEC_infoBuildType m10: 8|3@1+ (1,0) [0|0] "" X
 SG_ VCSEC_infoBuildConfigId m10: 16|16@1+ (1,0) [0|0] "" X
 SG_ VCSEC_infoHardwareId m10: 32|16@1+ (1,0) [0|0] "" X
 SG_ VCSEC_infoComponentId m10: 48|16@1+ (1,0) [0|0] "" X
 SG_ VCSEC_infoPcbaId m11: 8|8@1+ (1,0) [0|0] "" X
 SG_ VCSEC_infoAssemblyId m11: 16|8@1+ (1,0) [0|0] "" X
 SG_ VCSEC_infoUsageId m11: 32|16@1+ (1,0) [0|0] "" X
 SG_ VCSEC_infoSubUsageId m11: 48|16@1+ (1,0) [0|0] "" X
 SG_ VCSEC_infoAppCrc m13: 32|32@1+ (1,0) [0|0] "" X
 SG_ VCSEC_infoSubcomponent1 m16: 32|32@1+ (1,0) [0|0] "" X
 SG_ VCSEC_infoAppGitHash m17: 10|54@1+ (4,0) [0|0] "" X
 SG_ VCSEC_infoBootGitHash m18: 10|54@1+ (4,0) [0|0] "" X
 SG_ VCSEC_infoPlatformType m19: 8|8@1+ (1,0) [0|0] "" X
 SG_ VCSEC_infoBootUdsProtoVersion m20: 8|16@1+ (1,0) [0|0] "" X
 SG_ VCSEC_infoBootCrc m20: 24|32@1+ (1,0) [0|0] "" X
 SG_ VCSEC_infoSubcomponent2 m23: 32|32@1+ (1,0) [0|0] "" X
 SG_ VCSEC_infoSubcomponent3 m24: 32|32@1+ (1,0) [0|0] "" X
 SG_ VCSEC_infoSubcomponent4 m31: 32|32@1+ (1,0) [0|0] "" X

BO_ 505 VCSEC_requests: 1 VEH
 SG_ VCSEC_chargePortRequest: 0|2@1+ (1,0) [0|0] "" X
 SG_ VCSEC_driveAttemptedWithoutAuth: 2|1@1+ (1,0) [0|0] "" X

BO_ 1657 UI_ambientLightingCtrls: 8 VEH
 SG_ UI_ambientLightingRed : 8|8@1+ (1,0) [0|255] "" X
 SG_ UI_ambientLightingGreen : 16|8@1+ (1,0) [0|255] "" X
 SG_ UI_ambientLightingBlue : 24|8@1+ (1,0) [0|255] "" X
 SG_ UI_ambientLightingBrightness : 32|7@1+ (1,0) [0|100] "%" X

BA_DEF_ BO_ "GenMsgSendType" ENUM "Cyclic";
BA_DEF_ BO_ "GenMsgCycleTime" INT 0 10000;

BA_ "GenMsgSendType" BO_ 864 0;
BA_ "GenMsgCycleTime" BO_ 864 100;

BA_ "GenMsgSendType" BO_ 258 0;
BA_ "GenMsgCycleTime" BO_ 258 100;

BA_ "GenMsgSendType" BO_ 626 0;
BA_ "GenMsgCycleTime" BO_ 626 50;

BA_ "GenMsgSendType" BO_ 642 0;
BA_ "GenMsgCycleTime" BO_ 642 50;

BA_ "GenMsgSendType" BO_ 770 0;
BA_ "GenMsgCycleTime" BO_ 770 1000;

BA_ "GenMsgSendType" BO_ 1860 0;
BA_ "GenMsgCycleTime" BO_ 1860 1000;

BA_ "GenMsgSendType" BO_ 778 0;
BA_ "GenMsgCycleTime" BO_ 778 50;

BA_ "GenMsgSendType" BO_ 1250 0;
BA_ "GenMsgCycleTime" BO_ 1250 100;

BA_ "GenMsgSendType" BO_ 930 0;
BA_ "GenMsgCycleTime" BO_ 930 50;

BA_ "GenMsgSendType" BO_ 610 0;
BA_ "GenMsgCycleTime" BO_ 610 100;

BA_ "GenMsgSendType" BO_ 962 0;
BA_ "GenMsgCycleTime" BO_ 962 50;

BA_ "GenMsgSendType" BO_ 960 0;
BA_ "GenMsgCycleTime" BO_ 960 100;

BA_ "GenMsgSendType" BO_ 1795 0;
BA_ "GenMsgCycleTime" BO_ 1795 10;

BA_ "GenMsgSendType" BO_ 259 0;
BA_ "GenMsgCycleTime" BO_ 259 100;

BA_ "GenMsgSendType" BO_ 915 0;
BA_ "GenMsgCycleTime" BO_ 915 50;

BA_ "GenMsgSendType" BO_ 579 0;
BA_ "GenMsgCycleTime" BO_ 579 100;

BA_ "GenMsgSendType" BO_ 524 0;
BA_ "GenMsgCycleTime" BO_ 524 100;

BA_ "GenMsgSendType" BO_ 774 0;
BA_ "GenMsgCycleTime" BO_ 774 1000;

BA_ "GenMsgSendType" BO_ 995 0;
BA_ "GenMsgCycleTime" BO_ 995 100;

BA_ "GenMsgSendType" BO_ 611 0;
BA_ "GenMsgCycleTime" BO_ 611 20;

BA_ "GenMsgSendType" BO_ 691 0;
BA_ "GenMsgCycleTime" BO_ 691 90;

BA_ "GenMsgSendType" BO_ 1859 0;
BA_ "GenMsgCycleTime" BO_ 1859 1000;

BA_ "GenMsgSendType" BO_ 794 0;
BA_ "GenMsgCycleTime" BO_ 794 50;

BA_ "GenMsgSendType" BO_ 1251 0;
BA_ "GenMsgCycleTime" BO_ 1251 100;

BA_ "GenMsgSendType" BO_ 899 0;
BA_ "GenMsgCycleTime" BO_ 899 100;

BA_ "GenMsgSendType" BO_ 857 0;
BA_ "GenMsgCycleTime" BO_ 857 100;

BA_ "GenMsgSendType" BO_ 969 0;
BA_ "GenMsgCycleTime" BO_ 969 1000;

BA_ "GenMsgSendType" BO_ 1017 0;
BA_ "GenMsgCycleTime" BO_ 1017 100;

BA_ "GenMsgSendType" BO_ 825 0;
BA_ "GenMsgCycleTime" BO_ 825 100;

BA_ "GenMsgSendType" BO_ 793 0;
BA_ "GenMsgCycleTime" BO_ 793 1000;

BA_ "GenMsgSendType" BO_ 505 0;
BA_ "GenMsgCycleTime" BO_ 505 100;

VAL_ 864 VCLEFT_matrixIndex 0 "AlertMatrix0" 1 "AlertMatrix1" 2 "AlertMatrix2" 3 "AlertMatrix3" 4 "AlertMatrix4" 5 "AlertMatrix5";

VAL_ 258 VCLEFT_frontLatchStatus 0 "SNA" 1 "OPENED" 2 "CLOSED" 3 "CLOSING" 4 "OPENING" 5 "AJAR" 6 "TIMEOUT" 7 "DEFAULT" 8 "FAULT";
VAL_ 258 VCLEFT_mirrorFoldState 0 "UNKNOWN" 1 "FOLDED" 2 "UNFOLDED" 3 "FOLDING" 4 "UNFOLDING";
VAL_ 258 VCLEFT_mirrorHeatState 0 "SNA" 1 "ON" 2 "OFF" 3 "OFF_UNAVAILABLE" 4 "FAULT";
VAL_ 258 VCLEFT_mirrorRecallState 0 "INIT" 1 "RECALLING_AXIS_1" 2 "RECALLING_AXIS_2" 3 "RECALLING_COMPLETE" 4 "RECALLING_FAILED" 5 "RECALLING_STOPPED";
VAL_ 258 VCLEFT_mirrorState 0 "IDLE" 1 "TILT_X" 2 "TILT_Y" 3 "FOLD_UNFOLD" 4 "RECALL";
VAL_ 258 VCLEFT_rearLatchStatus 0 "SNA" 1 "OPENED" 2 "CLOSED" 3 "CLOSING" 4 "OPENING" 5 "AJAR" 6 "TIMEOUT" 7 "DEFAULT" 8 "FAULT";

VAL_ 626 VCLEFT_epbmDebugIndex 0 "STATES" 1 "TRANSITIONS";
VAL_ 626 VCLEFT_epbmCaliperState 0 "UNSAVED" 1 "UNKNOWN" 2 "REAPPLY" 3 "PARK" 4 "OPEN" 5 "SERVICE";
VAL_ 626 VCLEFT_summonFaultReason 0 "NONE" 1 "DI_MIA" 2 "DAS_MIA" 3 "ESP_MIA" 4 "EPBM_MIA" 5 "DI_FAULT" 6 "DI_APC_FAULT" 7 "DAS_FAULT" 8 "ESP_FAULT" 9 "VEH_CAN_FAULT" 10 "EAC_NOT_ALLOWED" 11 "EPBM_REQUEST" 12 "SPEED" 13 "EXTERNAL" 14 "PARK_MIA" 15 "PM_MIA" 16 "PM_REQUEST" 17 "OOC" 18 "MISMATCH" 19 "EPB_FAULT" 20 "DI_STATE_INVALID" 21 "PASSIVE_REQUEST" 22 "EPBREMOTE_MIA" 23 "REMOTE_SUMMON_FAULTED" 24 "LOCAL_UNIT_FAULTED" 25 "REMOTE_UNIT_FAULTED" 26 "START_IN_UNAVAILABLE" 27 "INVALID_REMOTE_STATE" 28 "REMOTE_DID_NOT_START";
VAL_ 626 VCLEFT_epbSummonState 0 "INIT" 1 "IDLE" 2 "ARMED" 3 "ACTIVE" 4 "COMPLETE" 5 "FAULT" 6 "UNAVAILABLE";
VAL_ 626 VCLEFT_epbmSummonState 0 "INIT" 1 "IDLE" 2 "ARMED" 3 "ACTIVE" 4 "COMPLETE" 5 "FAULT" 6 "UNAVAILABLE";
VAL_ 626 VCLEFT_epbmUnitStatus 0 "UNKNOWN" 1 "OPEN" 2 "DYNAMIC" 3 "PARK" 4 "START" 5 "SERVICE" 6 "WINCHMODE" 7 "WINCHMODE_RELEASING" 8 "PARKING" 9 "DYNAMIC_APPLYING" 10 "RELEASING" 11 "SERVICE_RELEASING" 12 "PARK_PENDING" 13 "WINCHMODE_PENDING" 14 "SUMMON" 15 "SUMMON_RELEASING" 16 "SUMMON_PARKING" 17 "EXTERNAL_DYNAMIC" 18 "RELEASING_FOR_EXTERNAL_PARK" 19 "EXTERNAL_PARKING" 20 "DYNAMIC_PARKING" 21 "COUNT";
VAL_ 626 VCLEFT_epbUnitStatus 0 "UNKNOWN" 1 "OPEN" 2 "DYNAMIC" 3 "PARK" 4 "START" 5 "SERVICE" 6 "WINCHMODE" 7 "WINCHMODE_RELEASING" 8 "PARKING" 9 "DYNAMIC_APPLYING" 10 "RELEASING" 11 "SERVICE_RELEASING" 12 "PARK_PENDING" 13 "WINCHMODE_PENDING" 14 "SUMMON" 15 "SUMMON_RELEASING" 16 "SUMMON_PARKING" 17 "EXTERNAL_DYNAMIC" 18 "RELEASING_FOR_EXTERNAL_PARK" 19 "EXTERNAL_PARKING" 20 "DYNAMIC_PARKING" 21 "COUNT";
VAL_ 626 VCLEFT_epbmFaultStatus 0 "NOMINAL" 1 "RETRY" 2 "FAULT" 3 "FAULT_IDLE";
VAL_ 626 VCLEFT_epbFaultStatus 0 "NOMINAL" 1 "RETRY" 2 "FAULT" 3 "FAULT_IDLE";
VAL_ 626 VCLEFT_cdpEnumDummy 0 "IDLE" 1 "VALID" 2 "INVALID";

VAL_ 642 VCLEFT_blowerIndex 0 "FEEDBACK_SIGNALS" 1 "VARS";
VAL_ 642 VCLEFT_hvacBlowerOutputDuty 127 "SNA";
VAL_ 642 VCLEFT_hvacBlowerRPMTarget 1023 "SNA";
VAL_ 642 VCLEFT_hvacBlowerTorque -128 "SNA";
VAL_ 642 VCLEFT_hvacBlowerFETTemp 255 "SNA";
VAL_ 642 VCLEFT_hvacBlowerITerm 255 "SNA";
VAL_ 642 VCLEFT_hvacBlowerRs 255 "SNA";
VAL_ 642 VCLEFT_hvacBlowerIPhase0 255 "SNA";
VAL_ 642 VCLEFT_hvacBlowerIPhase1 255 "SNA";
VAL_ 642 VCLEFT_hvacBlowerIPhase2 255 "SNA";

VAL_ 770 VCLEFT_infoIndex 0 "DEPRECATED_0" 1 "DEPRECATED_1" 2 "DEPRECATED_2" 3 "DEPRECATED_3" 4 "DEPRECATED_4" 5 "DEPRECATED_5" 6 "DEPRECATED_6" 7 "DEPRECATED_7" 8 "DEPRECATED_8" 9 "DEPRECATED_9" 10 "BUILD_HWID_COMPONENTID" 11 "PCBAID_ASSYID_USAGEID" 13 "APP_CRC" 14 "BOOTLOADER_SVN" 15 "BOOTLOADER_CRC" 16 "SUBCOMPONENT1" 17 "APP_GITHASH" 18 "BOOTLOADER_GITHASH" 19 "VERSION_DEPRECATED" 20 "UDS_PROTOCOL_BOOTCRC" 23 "SUBCOMPONENT2" 24 "SUBCOMPONENT3" 31 "SUBCOMPONENT4" 255 "END";
VAL_ 770 VCLEFT_infoBuildType 0 "UNKNOWN_BUILD" 1 "PLATFORM_BUILD" 2 "LOCAL_BUILD" 3 "TRACEABLE_CI_BUILD" 4 "MFG_BUILD";
VAL_ 770 VCLEFT_infoAssemblyId 1 "ASSEMBLY1" 255 "ASSEMBLY_SNA";

VAL_ 1860 VCLEFT_columnRecallStatus 0 "SNA" 1 "IN_PROGRESS" 2 "COMPLETE" 3 "INTERRUPTED";
VAL_ 1860 VCLEFT_mirrorRecallStatus 0 "SNA" 1 "IN_PROGRESS" 2 "COMPLETE" 3 "INTERRUPTED";
VAL_ 1860 VCLEFT_seatRecallStatus 0 "SNA" 1 "IN_PROGRESS" 2 "COMPLETE" 3 "INTERRUPTED";
VAL_ 1860 VCLEFT_systemRecallStatus 0 "SNA" 1 "IN_PROGRESS" 2 "COMPLETE" 3 "INTERRUPTED";

VAL_ 778 VCLEFT_frontBuckleStatus 0 "UNLATCHED" 1 "LATCHED" 2 "FAULTED" 3 "SNA";
VAL_ 778 VCLEFT_frontOccupancyStatus 0 "UNOCCUPIED" 1 "OCCUPIED" 2 "OCCUPANCY_FAULTED" 3 "NOT_CONFIGURED" 7 "OCCUPANCY_SNA";
VAL_ 778 VCLEFT_rearCenterOccupancyStatus 0 "UNOCCUPIED" 1 "OCCUPIED" 2 "OCCUPANCY_FAULTED" 3 "OCCUPANCY_SNA";
VAL_ 778 VCLEFT_rearLeftBuckleStatus 0 "UNLATCHED" 1 "LATCHED" 2 "FAULTED" 3 "SNA";
VAL_ 778 VCLEFT_rearLeftOccupancyStatus 0 "UNOCCUPIED" 1 "OCCUPIED" 2 "OCCUPANCY_FAULTED" 3 "OCCUPANCY_SNA";
VAL_ 778 VCLEFT_rearRightOccupancyStatus 0 "UNOCCUPIED" 1 "OCCUPIED" 2 "OCCUPANCY_FAULTED" 3 "OCCUPANCY_SNA";

VAL_ 1250 VCLEFT_seatStatusIndex 0 "TRACK" 1 "BACK" 2 "LIFT" 3 "TILT" 4 "LUMBAR" 5 "POSITION";
VAL_ 1250 VCLEFT_frontSeatTrackState 0 "STOPPED" 1 "MOVING_UP" 2 "MOVING_DOWN" 3 "RECALLING" 4 "CALIBRATING" 5 "UNDEFINED";
VAL_ 1250 VCLEFT_frontSeatBackState 0 "STOPPED" 1 "MOVING_UP" 2 "MOVING_DOWN" 3 "RECALLING" 4 "CALIBRATING" 5 "UNDEFINED";
VAL_ 1250 VCLEFT_frontSeatLiftState 0 "STOPPED" 1 "MOVING_UP" 2 "MOVING_DOWN" 3 "RECALLING" 4 "CALIBRATING" 5 "UNDEFINED";
VAL_ 1250 VCLEFT_frontSeatTiltState 0 "STOPPED" 1 "MOVING_UP" 2 "MOVING_DOWN" 3 "RECALLING" 4 "CALIBRATING" 5 "UNDEFINED";
VAL_ 1250 VCLEFT_lumbarAState 0 "STOPPED" 1 "MOVING_UP" 2 "MOVING_DOWN" 3 "RECALLING" 4 "CALIBRATING" 5 "UNDEFINED";
VAL_ 1250 VCLEFT_lumbarBState 0 "STOPPED" 1 "MOVING_UP" 2 "MOVING_DOWN" 3 "RECALLING" 4 "CALIBRATING" 5 "UNDEFINED";

VAL_ 930 VCLEFT_statusIndex 0 "MUX0" 1 "MUX1";
VAL_ 930 VCLEFT_vehiclePowerStateDBG 0 "OFF" 1 "CONDITIONING" 2 "ACCESSORY" 3 "DRIVE";
VAL_ 930 VCLEFT_swcInputVoltage 255 "SNA";
VAL_ 930 VCLEFT_swcPCBATemperature -128 "SNA";
VAL_ 930 VCLEFT_tlcPCBATemperature -128 "SNA";

VAL_ 610 VCLEFT_steeringColumnLastRequest 0 "SNA" 1 "NONE" 2 "UP" 3 "DOWN" 4 "IN" 5 "OUT";
VAL_ 610 VCLEFT_steeringColumnSMState 0 "SNA" 1 "RECALL" 2 "CALIBRATE" 3 "MANUAL_CONTROL";

VAL_ 962 VCLEFT_switchStatusIndex 0 "0" 1 "1" 2 "INVALID";
VAL_ 962 VCLEFT_rightMirrorTilt 0 "STOP" 1 "DOWN" 2 "UP" 3 "RIGHT" 4 "LEFT";
VAL_ 962 VCLEFT_frontSeatTrackBack 0 "SNA" 1 "OFF" 2 "ON" 3 "FAULT";
VAL_ 962 VCLEFT_frontSeatTrackForward 0 "SNA" 1 "OFF" 2 "ON" 3 "FAULT";
VAL_ 962 VCLEFT_frontSeatTiltDown 0 "SNA" 1 "OFF" 2 "ON" 3 "FAULT";
VAL_ 962 VCLEFT_frontSeatTiltUp 0 "SNA" 1 "OFF" 2 "ON" 3 "FAULT";
VAL_ 962 VCLEFT_frontSeatLiftDown 0 "SNA" 1 "OFF" 2 "ON" 3 "FAULT";
VAL_ 962 VCLEFT_frontSeatLiftUp 0 "SNA" 1 "OFF" 2 "ON" 3 "FAULT";
VAL_ 962 VCLEFT_frontSeatBackrestBack 0 "SNA" 1 "OFF" 2 "ON" 3 "FAULT";
VAL_ 962 VCLEFT_frontSeatBackrestForward 0 "SNA" 1 "OFF" 2 "ON" 3 "FAULT";
VAL_ 962 VCLEFT_frontSeatLumbarDown 0 "SNA" 1 "OFF" 2 "ON" 3 "FAULT";
VAL_ 962 VCLEFT_frontSeatLumbarUp 0 "SNA" 1 "OFF" 2 "ON" 3 "FAULT";
VAL_ 962 VCLEFT_frontSeatLumbarIn 0 "SNA" 1 "OFF" 2 "ON" 3 "FAULT";
VAL_ 962 VCLEFT_frontSeatLumbarOut 0 "SNA" 1 "OFF" 2 "ON" 3 "FAULT";
VAL_ 962 VCLEFT_frontBuckleSwitch 0 "SNA" 1 "OFF" 2 "ON" 3 "FAULT";
VAL_ 962 VCLEFT_frontOccupancySwitch 0 "SNA" 1 "OFF" 2 "ON" 3 "FAULT";
VAL_ 962 VCLEFT_rearLeftBuckleSwitch 0 "SNA" 1 "OFF" 2 "ON" 3 "FAULT";
VAL_ 962 VCLEFT_rearCenterOccupancySwitch 0 "SNA" 1 "OFF" 2 "ON" 3 "FAULT";
VAL_ 962 VCLEFT_rearLeftOccupancySwitch 0 "SNA" 1 "OFF" 2 "ON" 3 "FAULT";
VAL_ 962 VCLEFT_rearRightOccupancySwitch 0 "SNA" 1 "OFF" 2 "ON" 3 "FAULT";
VAL_ 962 VCLEFT_swcLeftTiltRight 0 "SNA" 1 "OFF" 2 "ON" 3 "FAULT";
VAL_ 962 VCLEFT_swcLeftPressed 0 "SNA" 1 "OFF" 2 "ON" 3 "FAULT";
VAL_ 962 VCLEFT_swcRightTiltLeft 0 "SNA" 1 "OFF" 2 "ON" 3 "FAULT";
VAL_ 962 VCLEFT_swcRightTiltRight 0 "SNA" 1 "OFF" 2 "ON" 3 "FAULT";
VAL_ 962 VCLEFT_swcRightPressed 0 "SNA" 1 "OFF" 2 "ON" 3 "FAULT";
VAL_ 962 VCLEFT_swcLeftTiltLeft 0 "SNA" 1 "OFF" 2 "ON" 3 "FAULT";

VAL_ 960 VCRIGHT_matrixIndex 0 "AlertMatrix0" 1 "AlertMatrix1" 2 "AlertMatrix2" 3 "AlertMatrix3" 4 "AlertMatrix4" 5 "AlertMatrix5";

VAL_ 1795 VCRIGHT_debugThermal10HzIndex 0 "heaterAndEvapWatts" 1 "temps" 2 "airflow" 3 "cabinModel" 4 "actuatorStatus" 5 "END";
VAL_ 1795 VCRIGHT_tempEvapAdjustmentLeft 255 "SNA";
VAL_ 1795 VCRIGHT_tempEvapAdjustmentRight 255 "SNA";
VAL_ 1795 VCRIGHT_cabinTempThs 255 "SNA";
VAL_ 1795 VCRIGHT_cabinTempThsBracket 255 "SNA";
VAL_ 1795 VCRIGHT_cabinTempProbe 255 "SNA";
VAL_ 1795 VCRIGHT_setTempAdjustmentLeft 255 "SNA";
VAL_ 1795 VCRIGHT_setTempAdjustmentRight 255 "SNA";

VAL_ 259 VCRIGHT_frontLatchStatus 0 "SNA" 1 "OPENED" 2 "CLOSED" 3 "CLOSING" 4 "OPENING" 5 "AJAR" 6 "TIMEOUT" 7 "DEFAULT" 8 "FAULT";
VAL_ 259 VCRIGHT_mirrorFoldState 0 "UNKNOWN" 1 "FOLDED" 2 "UNFOLDED" 3 "FOLDING" 4 "UNFOLDING";
VAL_ 259 VCRIGHT_mirrorRecallState 0 "INIT" 1 "RECALLING_AXIS_1" 2 "RECALLING_AXIS_2" 3 "RECALLING_COMPLETE" 4 "RECALLING_FAILED" 5 "RECALLING_STOPPED";
VAL_ 259 VCRIGHT_mirrorState 0 "IDLE" 1 "TILT_X" 2 "TILT_Y" 3 "FOLD_UNFOLD" 4 "RECALL";
VAL_ 259 VCRIGHT_rearLatchStatus 0 "SNA" 1 "OPENED" 2 "CLOSED" 3 "CLOSING" 4 "OPENING" 5 "AJAR" 6 "TIMEOUT" 7 "DEFAULT" 8 "FAULT";
VAL_ 259 VCRIGHT_trunkLatchStatus 0 "SNA" 1 "OPENED" 2 "CLOSED" 3 "CLOSING" 4 "OPENING" 5 "AJAR" 6 "TIMEOUT" 7 "DEFAULT" 8 "FAULT";

VAL_ 915 VCRIGHT_epbmDebugIndex 0 "STATES" 1 "TRANSITIONS";
VAL_ 915 VCRIGHT_epbmCaliperState 0 "UNSAVED" 1 "UNKNOWN" 2 "REAPPLY" 3 "PARK" 4 "OPEN" 5 "SERVICE";
VAL_ 915 VCRIGHT_summonFaultReason 0 "NONE" 1 "DI_MIA" 2 "DAS_MIA" 3 "ESP_MIA" 4 "EPBM_MIA" 5 "DI_FAULT" 6 "DI_APC_FAULT" 7 "DAS_FAULT" 8 "ESP_FAULT" 9 "VEH_CAN_FAULT" 10 "EAC_NOT_ALLOWED" 11 "EPBM_REQUEST" 12 "SPEED" 13 "EXTERNAL" 14 "PARK_MIA" 15 "PM_MIA" 16 "PM_REQUEST" 17 "OOC" 18 "MISMATCH" 19 "EPB_FAULT" 20 "DI_STATE_INVALID" 21 "PASSIVE_REQUEST" 22 "EPBREMOTE_MIA" 23 "REMOTE_SUMMON_FAULTED" 24 "LOCAL_UNIT_FAULTED" 25 "REMOTE_UNIT_FAULTED" 26 "START_IN_UNAVAILABLE" 27 "INVALID_REMOTE_STATE" 28 "REMOTE_DID_NOT_START";
VAL_ 915 VCRIGHT_epbSummonState 0 "INIT" 1 "IDLE" 2 "ARMED" 3 "ACTIVE" 4 "COMPLETE" 5 "FAULT" 6 "UNAVAILABLE";
VAL_ 915 VCRIGHT_epbmSummonState 0 "INIT" 1 "IDLE" 2 "ARMED" 3 "ACTIVE" 4 "COMPLETE" 5 "FAULT" 6 "UNAVAILABLE";
VAL_ 915 VCRIGHT_epbUnitStatus 0 "UNKNOWN" 1 "OPEN" 2 "DYNAMIC" 3 "PARK" 4 "START" 5 "SERVICE" 6 "WINCHMODE" 7 "WINCHMODE_RELEASING" 8 "PARKING" 9 "DYNAMIC_APPLYING" 10 "RELEASING" 11 "SERVICE_RELEASING" 12 "PARK_PENDING" 13 "WINCHMODE_PENDING" 14 "SUMMON" 15 "SUMMON_RELEASING" 16 "SUMMON_PARKING" 17 "EXTERNAL_DYNAMIC" 18 "RELEASING_FOR_EXTERNAL_PARK" 19 "EXTERNAL_PARKING" 20 "DYNAMIC_PARKING" 21 "COUNT";
VAL_ 915 VCRIGHT_epbmFaultStatus 0 "NOMINAL" 1 "RETRY" 2 "FAULT" 3 "FAULT_IDLE";
VAL_ 915 VCRIGHT_epbFaultStatus 0 "NOMINAL" 1 "RETRY" 2 "FAULT" 3 "FAULT_IDLE";
VAL_ 915 VCRIGHT_cdpEnumDummy 0 "IDLE" 1 "VALID" 2 "INVALID";

VAL_ 579 VCRIGHT_hvacACRunning 0 "OFF" 1 "ON";
VAL_ 579 VCRIGHT_hvacAirDistributionMode 0 "NONE" 1 "FLOOR" 2 "PANEL" 3 "PANEL_FLOOR" 4 "DEFROST" 5 "DEFROST_FLOOR" 6 "DEFROST_PANEL" 7 "DEFROST_PANEL_FLOOR";
VAL_ 579 VCRIGHT_hvacBlowerSegment 0 "OFF" 1 "1" 2 "2" 3 "3" 4 "4" 5 "5" 6 "6" 7 "7" 8 "8" 9 "9" 10 "10" 11 "11";
VAL_ 579 VCRIGHT_hvacPowerState 0 "OFF" 1 "ON" 2 "PRECONDITION" 3 "OVERHEAT_PROTECT_FANONLY" 4 "OVERHEAT_PROTECT";
VAL_ 579 VCRIGHT_hvacRecirc 0 "AUTO" 1 "RECIRC" 2 "FRESH";
VAL_ 579 VCRIGHT_hvacSecondRowState 0 "AUTO" 1 "OFF" 2 "LOW" 3 "MED" 4 "HIGH";

VAL_ 524 VCRIGHT_tempEvaporator 2047 "SNA";
VAL_ 524 VCRIGHT_tempEvaporatorTarget 255 "SNA";

VAL_ 774 VCRIGHT_infoIndex 0 "DEPRECATED_0" 1 "DEPRECATED_1" 2 "DEPRECATED_2" 3 "DEPRECATED_3" 4 "DEPRECATED_4" 5 "DEPRECATED_5" 6 "DEPRECATED_6" 7 "DEPRECATED_7" 8 "DEPRECATED_8" 9 "DEPRECATED_9" 10 "BUILD_HWID_COMPONENTID" 11 "PCBAID_ASSYID_USAGEID" 13 "APP_CRC" 14 "BOOTLOADER_SVN" 15 "BOOTLOADER_CRC" 16 "SUBCOMPONENT1" 17 "APP_GITHASH" 18 "BOOTLOADER_GITHASH" 19 "VERSION_DEPRECATED" 20 "UDS_PROTOCOL_BOOTCRC" 23 "SUBCOMPONENT2" 24 "SUBCOMPONENT3" 31 "SUBCOMPONENT4" 255 "END";
VAL_ 774 VCRIGHT_infoBuildType 0 "UNKNOWN_BUILD" 1 "PLATFORM_BUILD" 2 "LOCAL_BUILD" 3 "TRACEABLE_CI_BUILD" 4 "MFG_BUILD";
VAL_ 774 VCRIGHT_infoAssemblyId 1 "ASSEMBLY1" 255 "ASSEMBLY_SNA";

VAL_ 995 VCRIGHT_brakeLightStatus 0 "OFF" 1 "ON" 2 "FAULT" 3 "SNA";
VAL_ 995 VCRIGHT_rearFogLightStatus 0 "OFF" 1 "ON" 2 "FAULT" 3 "SNA";
VAL_ 995 VCRIGHT_reverseLightStatus 0 "OFF" 1 "ON" 2 "FAULT" 3 "SNA";
VAL_ 995 VCRIGHT_tailLightStatus 0 "OFF" 1 "ON" 2 "FAULT" 3 "SNA";
VAL_ 995 VCRIGHT_turnSignalStatus 0 "OFF" 1 "ON" 2 "FAULT" 3 "SNA";

VAL_ 611 VCRIGHT_logging10HzIndex 0 "HVAC_ACTUATOR_TARGETS" 1 "HVAC_ACTUATOR_POSITIONS" 2 "HVAC_ACTUATOR_STATE" 3 "END";
VAL_ 611 VCRIGHT_evapPulldownBias 255 "SNA" ;
VAL_ 611 VCRIGHT_hvacLHBleedOperationMode 0 "NORMAL" 1 "CALIBRATION";
VAL_ 611 VCRIGHT_hvacRHBleedOperationMode 0 "NORMAL" 1 "CALIBRATION";
VAL_ 611 VCRIGHT_hvacLHVaneOperationMode 0 "NORMAL" 1 "CALIBRATION";
VAL_ 611 VCRIGHT_hvacRHVaneOperationMode 0 "NORMAL" 1 "CALIBRATION";
VAL_ 611 VCRIGHT_hvacUpperModeOpMode 0 "NORMAL" 1 "CALIBRATION";
VAL_ 611 VCRIGHT_hvacLowerModeOpMode 0 "NORMAL" 1 "CALIBRATION";
VAL_ 611 VCRIGHT_hvacIntakeOperationMode 0 "NORMAL" 1 "CALIBRATION";
VAL_ 611 VCRIGHT_hvacLHBleedActuatorState 0 "BRAKING" 1 "RUNNING" 2 "COASTING";
VAL_ 611 VCRIGHT_hvacRHBleedActuatorState 0 "BRAKING" 1 "RUNNING" 2 "COASTING";
VAL_ 611 VCRIGHT_hvacLHVaneActuatorState 0 "BRAKING" 1 "RUNNING" 2 "COASTING";
VAL_ 611 VCRIGHT_hvacRHVaneActuatorState 0 "BRAKING" 1 "RUNNING" 2 "COASTING";
VAL_ 611 VCRIGHT_hvacUpperModeActState 0 "BRAKING" 1 "RUNNING" 2 "COASTING";
VAL_ 611 VCRIGHT_hvacLowerModeActState 0 "BRAKING" 1 "RUNNING" 2 "COASTING";
VAL_ 611 VCRIGHT_hvacIntakeActuatorState 0 "BRAKING" 1 "RUNNING" 2 "COASTING";

VAL_ 579 VCRIGHT_tempDuctLeft 511 "SNA";
VAL_ 579 VCRIGHT_tempDuctRight 511 "SNA";
VAL_ 579 VCRIGHT_hvacDuctTargetLeft 255 "SNA";
VAL_ 579 VCRIGHT_hvacDuctTargetRight 255 "SNA";
VAL_ 579 VCRIGHT_hvacModelInitStatus 4 "INIT_FORWARD_CALC" 2 "INIT_FROM_SENSORS" 3 "INIT_FROM_SENSORS_PREDICTION_ERROR" 5 "INIT_WAITING_FOR_SENSORS" 1 "NOT_INIT_WAIT_FOR_GTW" 0 "NOT_INIT_WAIT_FOR_SENSORS" ;
VAL_ 579 VCRIGHT_hvacPowerState 0 "OFF" 1 "ON" 4 "OVERHEAT_PROTECT" 3 "OVERHEAT_PROTECT_FANONLY" 2 "PRECONDITION" ;
VAL_ 579 VCRIGHT_hvacRecirc 0 "AUTO" 2 "FRESH" 1 "RECIRC" ;
VAL_ 579 VCRIGHT_hvacSecondRowState 0 "AUTO" 4 "HIGH" 2 "LOW" 3 "MED" 1 "OFF" ;
VAL_ 579 VCRIGHT_hvacVentStatus 0 "BOTH" 1 "LEFT" 2 "RIGHT" ;
VAL_ 579 VCRIGHT_tempDuctLeft 255 "SNA" ;
VAL_ 579 VCRIGHT_tempDuctLeftLower 255 "SNA" ;
VAL_ 579 VCRIGHT_tempDuctLeftUpper 255 "SNA" ;
VAL_ 579 VCRIGHT_tempDuctRight 255 "SNA" ;
VAL_ 579 VCRIGHT_tempDuctRightLower 255 "SNA" ;
VAL_ 579 VCRIGHT_tempDuctRightUpper 255 "SNA" ;

VAL_ 691 VCRIGHT_logging1HzIndex 0 "HVAC_TEMP_SENSORS_AND_ESTIMATES_1" 1 "HVAC_TEMP_SENSORS_AND_ESTIMATES_2" 2 "HVAC_HUMIDITY_HEATER" 3 "HVAC_STATUS_AIRFLOW" 4 "HVAC_COMFORT_SOLAR" 5 "HEATER_AND_DUCT_TARGETS" 6 "HVAC_ACTUATOR_VOLTAGES" 7 "HVAC_ACTUATOR_ENDSTOP" 8 "HVAC_ACTUATOR_ZEROSTOP" 9 "HVAC_MISCELLANEOUS_1" 10 "HVAC_MISCELLANEOUS_2" 11 "END";
VAL_ 691 VCRIGHT_tempIncarCabinProbe 255 "SNA";
VAL_ 691 VCRIGHT_tempIncarCabinMid 250 "SNA";
VAL_ 691 VCRIGHT_tempIncarCabinDeep 255 "SNA";
VAL_ 691 VCRIGHT_cabinTempInteriorL2 240 "SNA";
VAL_ 691 VCRIGHT_cabinTempInteriorSunnyL2 240 "SNA";
VAL_ 691 VCRIGHT_cabinTempGlassRoof 255 "SNA";
VAL_ 691 VCRIGHT_cabinTempWindshield 255 "SNA";
VAL_ 691 VCRIGHT_cabinTempInterior 240 "SNA";
VAL_ 691 VCRIGHT_cabinTempInteriorSunny 240 "SNA";
VAL_ 691 VCRIGHT_cabinTempSideGlassLeft 255 "SNA";
VAL_ 691 VCRIGHT_cabinTempSideGlassRight 255 "SNA";
VAL_ 691 VCRIGHT_cabinTempBreathLevel 255 "SNA";
VAL_ 691 VCRIGHT_hvacAutoTransitionReason 0 "NONE" 1 "HUMIDITY_HIGH" 2 "HUMIDITY_MODERATE" 3 "HUMIDITY_LOW" 4 "TEMP_TARGET_BELOW_THRESHOLD" 5 "TEMP_TARGET_ABOVE_THRESHOLD" 6 "EXCESS_OCCUPANT_CONVECTION" 7 "OCCUPANT_CONVECTION_REQUIREMENT" 8 "TEMP_TARGET_LOW" 9 "DUCTS_COLD" 10 "BI_LEVEL_LANDING" 11 "DEFOG_OVERRIDE" 12 "SET_TEMP_LO" 13 "SET_TEMP_HI" 14 "CABIN_PURGE" 15 "EVAP_DRYING" 16 "HVAC_OFF" 17 "END";
VAL_ 691 VCRIGHT_hvacAirFlowModeRow1 0 "NONE" 1 "FLOOR" 2 "PANEL" 3 "PANEL_FLOOR" 4 "DEFROST" 5 "DEFROST_FLOOR" 6 "DEFROST_PANEL" 7 "DEFROST_PANEL_FLOOR";
VAL_ 691 VCRIGHT_hvacAirFlowModeRow2 0 "NONE" 1 "FLOOR" 2 "PANEL" 3 "PANEL_FLOOR" 4 "DEFROST" 5 "DEFROST_FLOOR" 6 "DEFROST_PANEL" 7 "DEFROST_PANEL_FLOOR";
VAL_ 691 VCRIGHT_hvacAirflowReason 0 "HVAC_OFF" 1 "MANUAL_FAN_SPEED" 2 "UI_SHORTCUT" 3 "CABIN_TEMPERATURE_CONTROL" 4 "MINIMUM_AUTO_AIRFLOW" 5 "STRATIFICATION_GLASS_ROOF" 6 "STRATIFICATION_INTERIOR_SURFACES" 7 "OCCUPANT_CONVECTION_REQUIREMENT" 8 "COLD_DUCT_LOCKOUT" 9 "CABIN_PURGE" 10 "CABIN_OVERHEAT_PROTECT" 11 "SCREEN_PROTECTION" 12 "EVAP_DRYING" 13 "NONE";
VAL_ 691 VCRIGHT_convectionTargetLeft 255 "SNA";
VAL_ 691 VCRIGHT_convectionTargetRight 255 "SNA";
VAL_ 691 VCRIGHT_convectionDeliveredLeft 255 "SNA";
VAL_ 691 VCRIGHT_convectionDeliveredRight 255 "SNA";
VAL_ 691 VCRIGHT_solarLoadRightOccupant 255 "SNA";
VAL_ 691 VCRIGHT_solarLoadLeftOccupant 255 "SNA";
VAL_ 691 VCRIGHT_solarLoadOnVehicle 255 "SNA";
VAL_ 691 VCRIGHT_solarLoadOnVehFiltered 255 "SNA";
VAL_ 691 VCRIGHT_cabinTempInteriorL3 240 "SNA";
VAL_ 691 VCRIGHT_cabinTempInteriorSunnyL3 240 "SNA";
VAL_ 691 VCRIGHT_cabinTempTopPadAir 240 "SNA";
VAL_ 691 VCRIGHT_tempDuctModeledLeft 511 "SNA";
VAL_ 691 VCRIGHT_tempDuctModeledRight 511 "SNA";
VAL_ 691 VCRIGHT_tempHtrSurfaceModeledL 511 "SNA";
VAL_ 691 VCRIGHT_tempHtrSurfaceModeledR 511 "SNA";

VAL_ 1859 VCRIGHT_mirrorRecallStatus 0 "SNA" 1 "IN_PROGRESS" 2 "COMPLETE" 3 "INTERRUPTED";
VAL_ 1859 VCRIGHT_seatRecallStatus 0 "SNA" 1 "IN_PROGRESS" 2 "COMPLETE" 3 "INTERRUPTED";
VAL_ 1859 VCRIGHT_systemRecallStatus 0 "SNA" 1 "IN_PROGRESS" 2 "COMPLETE" 3 "INTERRUPTED";

VAL_ 794 VCRIGHT_frontBuckleStatus 0 "UNLATCHED" 1 "LATCHED" 2 "FAULTED" 3 "SNA";
VAL_ 794 VCRIGHT_frontOccupancyStatus 0 "UNOCCUPIED" 1 "OCCUPIED" 2 "OCCUPANCY_FAULTED" 3 "NOT_CONFIGURED" 7 "OCCUPANCY_SNA";
VAL_ 794 VCRIGHT_rearCenterBuckleStatus 0 "UNLATCHED" 1 "LATCHED" 2 "FAULTED" 3 "SNA";
VAL_ 794 VCRIGHT_rearRightBuckleStatus 0 "UNLATCHED" 1 "LATCHED" 2 "FAULTED" 3 "SNA";

VAL_ 1251 VCRIGHT_seatStatusIndex 0 "TRACK" 1 "BACK" 2 "LIFT" 3 "TILT" 4 "LUMBAR" 5 "POSITION";
VAL_ 1251 VCRIGHT_frontSeatTrackState 0 "STOPPED" 1 "MOVING_UP" 2 "MOVING_DOWN" 3 "RECALLING" 4 "CALIBRATING" 5 "UNDEFINED";
VAL_ 1251 VCRIGHT_frontSeatBackState 0 "STOPPED" 1 "MOVING_UP" 2 "MOVING_DOWN" 3 "RECALLING" 4 "CALIBRATING" 5 "UNDEFINED";
VAL_ 1251 VCRIGHT_frontSeatLiftState 0 "STOPPED" 1 "MOVING_UP" 2 "MOVING_DOWN" 3 "RECALLING" 4 "CALIBRATING" 5 "UNDEFINED";
VAL_ 1251 VCRIGHT_frontSeatTiltState 0 "STOPPED" 1 "MOVING_UP" 2 "MOVING_DOWN" 3 "RECALLING" 4 "CALIBRATING" 5 "UNDEFINED";
VAL_ 1251 VCRIGHT_lumbarAState 0 "STOPPED" 1 "MOVING_UP" 2 "MOVING_DOWN" 3 "RECALLING" 4 "CALIBRATING" 5 "UNDEFINED";
VAL_ 1251 VCRIGHT_lumbarBState 0 "STOPPED" 1 "MOVING_UP" 2 "MOVING_DOWN" 3 "RECALLING" 4 "CALIBRATING" 5 "UNDEFINED";

VAL_ 899 VCRIGHT_estimatedThsSolarLoad 1023 "SNA";
VAL_ 899 VCRIGHT_thsHumidity 255 "SNA";
VAL_ 899 VCRIGHT_thsSolarLoadInfrared 1023 "SNA";
VAL_ 899 VCRIGHT_thsSolarLoadVisible 1023 "SNA";
VAL_ 899 VCRIGHT_thsTemperature -128 "SNA";

VAL_ 857 VCSEC_BLEConnectionStatus 0 "NOT_CONNECTED" 1 "CONNECTED" 2 "WRITE" 3 "NOTIFICATION" 4 "READ" 5 "UPDATE_SPEED";
VAL_ 857 VCSEC_BLEDeviceLocation 0 "NOT_PRESENT" 1 "CONNECTION_RANGE" 2 "AUTHENTICATION_RANGE";
VAL_ 857 VCSEC_BLEDevicePairingStatus 0 "IDLE" 1 "STEP1" 2 "STEP2" 3 "STEP3" 4 "SUCCESS" 5 "FAILURE";
VAL_ 857 VCSEC_BLEDeviceType 0 "UNKNOWN" 1 "ANDROID" 2 "IOS" 3 "OTHER";

VAL_ 969 VCSEC_BLEEndpointInfoIndex 0 "LEFT_INFO" 1 "RIGHT_INFO" 2 "REAR_INFO" 3 "CENTER_INFO" 4 "LEFT_APP_GITHASH" 5 "RIGHT_APP_GITHASH" 6 "REAR_APP_GITHASH" 7 "CENTER_APP_GITHASH";

VAL_ 1017 VCSEC_matrixIndex 0 "AlertMatrix0" 1 "AlertMatrix1" 2 "AlertMatrix2" 3 "AlertMatrix3";

VAL_ 825 VCSEC_MCUCommandType 0 "NONE" 1 "REMOTE_UNLOCK" 2 "REMOTE_START" 3 "COMMAND3" 4 "COMMAND4" 5 "COMMAND5";
VAL_ 825 VCSEC_alarmStatus 0 "DISARMED" 1 "ARMED" 2 "PARTIAL_ARMED" 3 "TRIGGERED_FLASH_ACTIVE" 4 "ERROR" 5 "TRIGGERED_FLASH_INACTIVE" 6 "IMMINENT" 7 "DEFAULT" 15 "SNA";
VAL_ 825 VCSEC_authenticationStatus 0 "NONE" 1 "AUTHENTICATED_FOR_UNLOCK" 2 "AUTHENTICATED_FOR_DRIVE";
VAL_ 825 VCSEC_chargePortLockStatus 0 "UNLOCKED" 1 "LOCKED";
VAL_ 825 VCSEC_frunkRequest 0 "NONE" 1 "OPEN" 2 "SNA";
VAL_ 825 VCSEC_immobilizerState 0 "IDLE" 1 "PREPARE" 2 "ENCRYPT_BEGIN" 3 "ENCRYPT" 4 "SEND_AUTH_RESPONSE" 5 "SEND_NO_GO_AUTH_RESPONSE";
VAL_ 825 VCSEC_keyChannelIndexed 15 "SNA";
VAL_ 825 VCSEC_leftFrontLockStatus 0 "UNLOCKED" 1 "LOCKED";
VAL_ 825 VCSEC_leftRearLockStatus 0 "UNLOCKED" 1 "LOCKED";
VAL_ 825 VCSEC_lockIndicationRequest 0 "NONE_SNA" 1 "SINGLE" 2 "DOUBLE" 3 "TRIPLE" 4 "HOLD";
VAL_ 825 VCSEC_lockRequestType 0 "NONE" 1 "PASSIVE_SHIFT_TO_P_UNLOCK" 2 "PASSIVE_PARKBUTTON_UNLOCK" 3 "PASSIVE_INTERNAL_HANDLE_UNLOCK" 4 "PASSIVE_DRIVE_AWAY_LOCK" 5 "PASSIVE_BLE_WALKUP_UNLOCK" 6 "PASSIVE_BLE_EXTERIOR_CHARGEHANDLEBUTTON_UNLOCK" 7 "PASSIVE_BLE_EXTERIOR_HANDLE_UNLOCK" 8 "PASSIVE_BLE_INTERIOR_HANDLE_UNLOCK" 9 "PASSIVE_BLE_LOCK" 10 "CRASH_UNLOCK" 11 "ACTIVE_UI_BUTTON_UNLOCK" 12 "ACTIVE_UI_BUTTON_LOCK" 13 "ACTIVE_REMOTE_UNLOCK" 14 "ACTIVE_REMOTE_LOCK" 15 "ACTIVE_NFC_UNLOCK" 16 "ACTIVE_NFC_LOCK" 17 "ACTIVE_BLE_UNLOCK" 18 "ACTIVE_BLE_LOCK" 19 "PASSIVE_INTERNAL_LOCK_PROMOTION";
VAL_ 825 VCSEC_rightFrontLockStatus 0 "UNLOCKED" 1 "LOCKED";
VAL_ 825 VCSEC_rightRearLockStatus 0 "UNLOCKED" 1 "LOCKED";
VAL_ 825 VCSEC_simpleLockStatus 0 "SNA" 1 "UNLOCKED" 2 "LOCKED";
VAL_ 825 VCSEC_summonRequest 0 "IDLE" 1 "PRIME" 2 "FORWARD" 3 "BACKWARD" 4 "STOP" 5 "SNA";
VAL_ 825 VCSEC_trunkLockStatus 0 "UNLOCKED" 1 "LOCKED";
VAL_ 825 VCSEC_trunkRequest 0 "NONE" 1 "OPEN" 2 "SNA";
VAL_ 825 VCSEC_vehicleLockStatus 0 "SNA" 1 "ACTIVE_NFC_UNLOCKED" 2 "ACTIVE_NFC_LOCKED" 3 "PASSIVE_SELECTIVE_UNLOCKED" 4 "PASSIVE_BLE_UNLOCKED" 5 "PASSIVE_BLE_LOCKED" 6 "ACTIVE_SELECTIVE_UNLOCKED" 7 "ACTIVE_BLE_UNLOCKED" 8 "ACTIVE_BLE_LOCKED" 9 "ACTIVE_UI_UNLOCKED" 10 "ACTIVE_UI_LOCKED" 11 "ACTIVE_REMOTE_UNLOCKED" 12 "ACTIVE_REMOTE_LOCKED" 13 "CRASH_UNLOCKED" 14 "PASSIVE_INTERNAL_UNLOCKED" 15 "PASSIVE_INTERNAL_LOCKED";

VAL_ 793 VCSEC_infoIndex 0 "DEPRECATED_0" 1 "DEPRECATED_1" 2 "DEPRECATED_2" 3 "DEPRECATED_3" 4 "DEPRECATED_4" 5 "DEPRECATED_5" 6 "DEPRECATED_6" 7 "DEPRECATED_7" 8 "DEPRECATED_8" 9 "DEPRECATED_9" 10 "BUILD_HWID_COMPONENTID" 11 "PCBAID_ASSYID_USAGEID" 13 "APP_CRC" 14 "BOOTLOADER_SVN" 15 "BOOTLOADER_CRC" 16 "SUBCOMPONENT1" 17 "APP_GITHASH" 18 "BOOTLOADER_GITHASH" 19 "VERSION_DEPRECATED" 20 "UDS_PROTOCOL_BOOTCRC" 23 "SUBCOMPONENT2" 24 "SUBCOMPONENT3" 31 "SUBCOMPONENT4" 255 "END";
VAL_ 793 VCSEC_infoBuildType 0 "UNKNOWN_BUILD" 1 "PLATFORM_BUILD" 2 "LOCAL_BUILD" 3 "TRACEABLE_CI_BUILD" 4 "MFG_BUILD";
VAL_ 793 VCSEC_infoAssemblyId 1 "ASSEMBLY1" 255 "ASSEMBLY_SNA";

VAL_ 505 VCSEC_chargePortRequest 0 "NONE" 1 "OPEN" 2 "CLOSE" 3 "SNA";

BO_ 290 VCLEFT_doorStatus2: 8 Vector__XXX
 SG_ VCLEFT_mirrorTiltYOffset m1 : 56|8@1- (0.02,0) [0|0] "" Vector__XXX
 SG_ VCLEFT_rearHandlePWM m0 : 56|7@1+ (1,0) [0|0] "" Vector__XXX
 SG_ VCLEFT_frontHandlePWM m0 : 48|7@1+ (1,0) [0|0] "" Vector__XXX
 SG_ VCLEFT_mirrorTiltXOffset m1 : 48|8@1- (0.02,0) [0|0] "" Vector__XXX
 SG_ VCLEFT_mirrorDimmed m0 : 47|1@1+ (1,0) [0|0] "" Vector__XXX
 SG_ VCLEFT_BPillarCameraHeaterCurrent m1 : 40|6@1+ (0.02,0) [0|0] "" Vector__XXX
 SG_ VCLEFT_mirrorFoldCurrent m0 : 40|7@1- (0.05,0) [0|0] "" Vector__XXX
 SG_ VCLEFT_rearHandle5vEnable m0 : 39|1@1+ (1,0) [0|0] "" Vector__XXX
 SG_ VCLEFT_frontHandle5vEnable m0 : 38|1@1+ (1,0) [0|0] "" Vector__XXX
 SG_ VCLEFT_rearHandleDebounceStatus m0 : 35|3@1+ (1,0) [0|0] "" Vector__XXX
 SG_ VCLEFT_frontHandleDebounceStatus m0 : 32|3@1+ (1,0) [0|0] "" Vector__XXX
 SG_ VCLEFT_mirrorFoldType m0 : 30|2@1+ (1,0) [0|0] "" Vector__XXX
 SG_ VCLEFT_rearHandleRawStatus m0 : 27|3@1+ (1,0) [0|0] "" Vector__XXX
 SG_ VCLEFT_frontHandleRawStatus m0 : 24|3@1+ (1,0) [0|0] "" Vector__XXX
 SG_ VCLEFT_rearDoorState m0 : 20|3@1+ (1,0) [0|0] "" Vector__XXX
 SG_ VCLEFT_frontDoorState m0 : 17|3@1+ (1,0) [0|0] "" Vector__XXX
 SG_ VCLEFT_BPillarCameraHeaterState m1 : 16|3@1+ (1,0) [0|0] "" Vector__XXX
 SG_ VCLEFT_vehicleInMotion m0 : 16|1@1+ (1,0) [0|0] "" Vector__XXX
 SG_ VCLEFT_frontLatchRelDuty m1 : 8|8@1+ (1,0) [0|0] "" Vector__XXX
 SG_ VCLEFT_rearLatchRelDuty m0 : 8|8@1+ (1,0) [0|0] "" Vector__XXX
 SG_ VCLEFT_doorStatus2Index M : 0|1@1+ (1,0) [0|0] "" Vector__XXX

BO_ 296 DI_systemLimits: 6 Vector__XXX
 SG_ DI_immobilizerAuthLevel : 33|2@1+ (1,0) [0|0] "" Vector__XXX
 SG_ DI_undersideAbuse : 32|1@1+ (1,0) [0|0] "" Vector__XXX
 SG_ DI_limitClosureNotClosed : 31|1@1+ (1,0) [0|0] "" Vector__XXX
 SG_ DI_proximity : 30|1@1+ (1,0) [0|0] "" Vector__XXX
 SG_ DI_vehicleSpeedLimitReason : 25|5@1+ (1,0) [0|0] "" Vector__XXX
 SG_ DI_vehicleSpeedLimit : 16|9@1+ (1,0) [0|0] "" Vector__XXX
 SG_ DI_vehicleSpeedLimitType : 14|2@1+ (1,0) [0|0] "" Vector__XXX
 SG_ DI_limitCdp : 13|1@1+ (1,0) [0|0] "" Vector__XXX
 SG_ DI_limitSystemSpinDownLearning : 12|1@1+ (1,0) [0|0] "" Vector__XXX
 SG_ DI_limitBmsMiaFreeze : 11|1@1+ (1,0) [0|0] "" Vector__XXX
 SG_ DI_limitVehicleSpeed : 10|1@1+ (1,0) [0|0] "" Vector__XXX
 SG_ DI_limitRegenTorque : 9|1@1+ (1,0) [0|0] "" Vector__XXX
 SG_ DI_limitDriveTorque : 8|1@1+ (1,0) [0|0] "" Vector__XXX
 SG_ DI_limitShift : 7|1@1+ (1,0) [0|0] "" Vector__XXX
 SG_ DI_limitSystemGPO : 6|1@1+ (1,0) [0|0] "" Vector__XXX
 SG_ DI_limitSystemLimp : 5|1@1+ (1,0) [0|0] "" Vector__XXX
 SG_ DI_limitObstacleDetection : 4|1@1+ (1,0) [0|0] "" Vector__XXX
 SG_ DI_limitVBatHigh : 3|1@1+ (1,0) [0|0] "" Vector__XXX
 SG_ DI_limitVBatLow : 2|1@1+ (1,0) [0|0] "" Vector__XXX
 SG_ DI_limitIBat : 1|1@1+ (1,0) [0|0] "" Vector__XXX
 SG_ DI_limitRegenPower : 0|1@1+ (1,0) [0|0] "" Vector__XXX

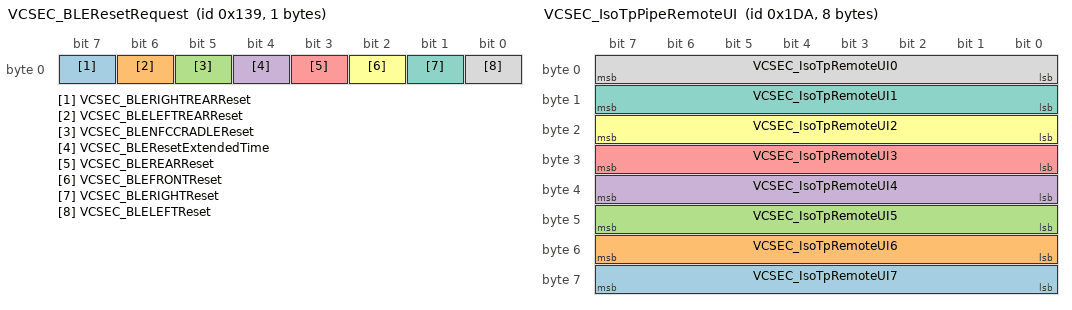
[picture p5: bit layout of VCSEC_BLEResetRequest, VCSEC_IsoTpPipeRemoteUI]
BO_ 313 VCSEC_BLEResetRequest: 1 Vector__XXX
 SG_ VCSEC_BLERIGHTREARReset : 7|1@1+ (1,0) [0|0] "" Vector__XXX
 SG_ VCSEC_BLELEFTREARReset : 6|1@1+ (1,0) [0|0] "" Vector__XXX
 SG_ VCSEC_BLENFCCRADLEReset : 5|1@1+ (1,0) [0|0] "" Vector__XXX
 SG_ VCSEC_BLEResetExtendedTime : 4|1@1+ (1,0) [0|0] "" Vector__XXX
 SG_ VCSEC_BLEREARReset : 3|1@1+ (1,0) [0|0] "" Vector__XXX
 SG_ VCSEC_BLEFRONTReset : 2|1@1+ (1,0) [0|0] "" Vector__XXX
 SG_ VCSEC_BLERIGHTReset : 1|1@1+ (1,0) [0|0] "" Vector__XXX
 SG_ VCSEC_BLELEFTReset : 0|1@1+ (1,0) [0|0] "" Vector__XXX

BO_ 474 VCSEC_IsoTpPipeRemoteUI: 8 Vector__XXX
 SG_ VCSEC_IsoTpRemoteUI7 : 56|8@1+ (1,0) [0|0] "" Vector__XXX
 SG_ VCSEC_IsoTpRemoteUI6 : 48|8@1+ (1,0) [0|0] "" Vector__XXX
 SG_ VCSEC_IsoTpRemoteUI5 : 40|8@1+ (1,0) [0|0] "" Vector__XXX
 SG_ VCSEC_IsoTpRemoteUI4 : 32|8@1+ (1,0) [0|0] "" Vector__XXX
 SG_ VCSEC_IsoTpRemoteUI3 : 24|8@1+ (1,0) [0|0] "" Vector__XXX
 SG_ VCSEC_IsoTpRemoteUI2 : 16|8@1+ (1,0) [0|0] "" Vector__XXX
 SG_ VCSEC_IsoTpRemoteUI1 : 8|8@1+ (1,0) [0|0] "" Vector__XXX
 SG_ VCSEC_IsoTpRemoteUI0 : 0|8@1+ (1,0) [0|0] "" Vector__XXX

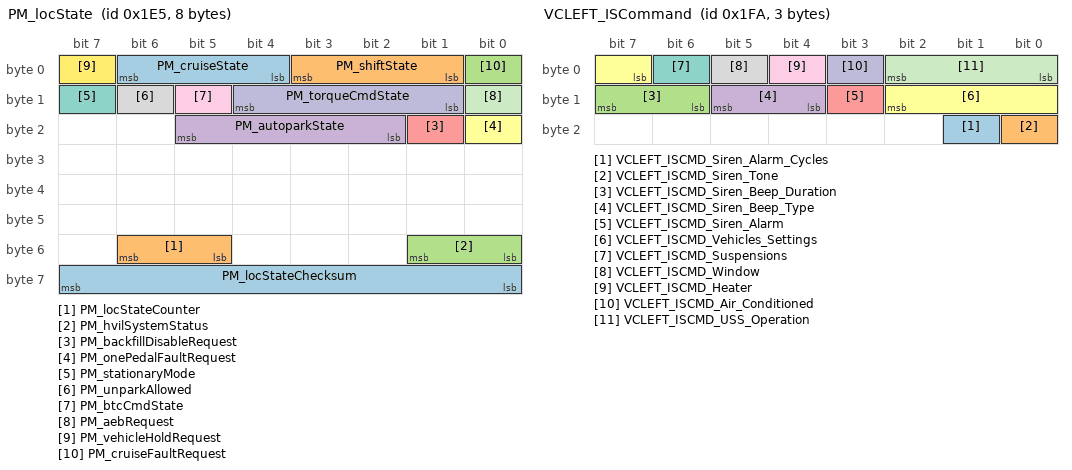
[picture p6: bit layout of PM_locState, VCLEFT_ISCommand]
BO_ 485 PM_locState: 8 Vector__XXX
 SG_ PM_locStateChecksum : 56|8@1+ (1,0) [0|0] "" Vector__XXX
 SG_ PM_locStateCounter : 53|2@1+ (1,0) [0|0] "" Vector__XXX
 SG_ PM_hvilSystemStatus : 48|2@1+ (1,0) [0|0] "" Vector__XXX
 SG_ PM_autoparkState : 18|4@1+ (1,0) [0|0] "" Vector__XXX
 SG_ PM_backfillDisableRequest : 17|1@1+ (1,0) [0|0] "" Vector__XXX
 SG_ PM_onePedalFaultRequest : 16|1@1+ (1,0) [0|0] "" Vector__XXX
 SG_ PM_stationaryMode : 15|1@1+ (1,0) [0|0] "" Vector__XXX
 SG_ PM_unparkAllowed : 14|1@1+ (1,0) [0|0] "" Vector__XXX
 SG_ PM_btcCmdState : 13|1@1+ (1,0) [0|0] "" Vector__XXX
 SG_ PM_torqueCmdState : 9|4@1+ (1,0) [0|0] "" Vector__XXX
 SG_ PM_aebRequest : 8|1@1+ (1,0) [0|0] "" Vector__XXX
 SG_ PM_vehicleHoldRequest : 7|1@1+ (1,0) [0|0] "" Vector__XXX
 SG_ PM_cruiseState : 4|3@1+ (1,0) [0|0] "" Vector__XXX
 SG_ PM_shiftState : 1|3@1+ (1,0) [0|0] "" Vector__XXX
 SG_ PM_cruiseFaultRequest : 0|1@1+ (1,0) [0|0] "" Vector__XXX

BO_ 504 VCLEFT_intrusionSensorStatus: 4 Vector__XXX
 SG_ VCLEFT_intrusionUltraTripped : 26|1@1+ (1,0) [0|0] "" Vector__XXX
 SG_ VCLEFT_intrusionTiltTripped : 25|1@1+ (1,0) [0|0] "" Vector__XXX
 SG_ VCLEFT_sirenMIA : 24|1@1+ (1,0) [0|0] "" Vector__XXX
 SG_ VCLEFT_DBG_System_Error : 23|1@1+ (1,0) [0|0] "" Vector__XXX
 SG_ VCLEFT_DBG_LM_SelfTest_Status : 22|1@1+ (1,0) [0|0] "" Vector__XXX
 SG_ VCLEFT_DBG_USS_SelfTest_Status : 21|1@1+ (1,0) [0|0] "" Vector__XXX
 SG_ VCLEFT_DBG_Eeprom_ST_Status : 20|1@1+ (1,0) [0|0] "" Vector__XXX
 SG_ VCLEFT_DBG_Reserved_08 : 19|1@1+ (1,0) [0|0] "" Vector__XXX
 SG_ VCLEFT_DBG_Reserved_07 : 18|1@1+ (1,0) [0|0] "" Vector__XXX
 SG_ VCLEFT_DBG_Siren_is_sounding : 17|1@1+ (1,0) [0|0] "" Vector__XXX
 SG_ VCLEFT_DBG_Invalid_Parameter : 16|1@1+ (1,0) [0|0] "" Vector__XXX
 SG_ VCLEFT_DBG_Siren_Int_Trigger : 15|1@1+ (1,0) [0|0] "" Vector__XXX
 SG_ VCLEFT_DBG_Siren_ST_Status : 14|1@1+ (1,0) [0|0] "" Vector__XXX
 SG_ VCLEFT_DBG_LM_Alarm_Status : 13|1@1+ (1,0) [0|0] "" Vector__XXX
 SG_ VCLEFT_DBG_USS_Alarm_Status : 12|1@1+ (1,0) [0|0] "" Vector__XXX
 SG_ VCLEFT_DBG_Veh_Settings_Status : 8|4@1+ (1,0) [0|0] "" Vector__XXX
 SG_ VCLEFT_DBG_SelfTest_Status : 7|1@1+ (1,0) [0|0] "" Vector__XXX
 SG_ VCLEFT_DBG_Suspensions_Status : 6|1@1+ (1,0) [0|0] "" Vector__XXX
 SG_ VCLEFT_DBG_Window_Status : 5|1@1+ (1,0) [0|0] "" Vector__XXX
 SG_ VCLEFT_DBG_Heater_Status : 4|1@1+ (1,0) [0|0] "" Vector__XXX
 SG_ VCLEFT_DBG_Air_Cond_Status : 3|1@1+ (1,0) [0|0] "" Vector__XXX
 SG_ VCLEFT_DBG_System_Status : 0|3@1+ (1,0) [0|0] "" Vector__XXX

BO_ 506 VCLEFT_ISCommand: 3 Vector__XXX
 SG_ VCLEFT_ISCMD_Siren_Alarm_Cycles : 17|1@1+ (1,0) [0|0] "" Vector__XXX
 SG_ VCLEFT_ISCMD_Siren_Tone : 16|1@1+ (1,0) [0|0] "" Vector__XXX
 SG_ VCLEFT_ISCMD_Siren_Beep_Duration : 14|2@1+ (1,0) [0|0] "" Vector__XXX
 SG_ VCLEFT_ISCMD_Siren_Beep_Type : 12|2@1+ (1,0) [0|0] "" Vector__XXX
 SG_ VCLEFT_ISCMD_Siren_Alarm : 11|1@1+ (1,0) [0|0] "" Vector__XXX
 SG_ VCLEFT_ISCMD_Vehicles_Settings : 7|4@1+ (1,0) [0|0] "" Vector__XXX
 SG_ VCLEFT_ISCMD_Suspensions : 6|1@1+ (1,0) [0|0] "" Vector__XXX
 SG_ VCLEFT_ISCMD_Window : 5|1@1+ (1,0) [0|0] "" Vector__XXX
 SG_ VCLEFT_ISCMD_Heater : 4|1@1+ (1,0) [0|0] "" Vector__XXX
 SG_ VCLEFT_ISCMD_Air_Conditioned : 3|1@1+ (1,0) [0|0] "" Vector__XXX
 SG_ VCLEFT_ISCMD_USS_Operation : 0|3@1+ (1,0) [0|0] "" Vector__XXX

BO_ 507 VCLEFT_TLCStatus: 8 Vector__XXX
 SG_ VCLEFT_TLCTotalCurrent m0 : 56|8@1+ (0.1,0) [0|0] "" Vector__XXX
 SG_ VCLEFT_TLCReverseCurrent m0 : 48|8@1+ (0.1,0) [0|0] "" Vector__XXX
 SG_ VCLEFT_TLCState_Reverse m1 : 41|3@1+ (1,0) [0|0] "" Vector__XXX
 SG_ VCLEFT_TLCFogCurrent m0 : 40|8@1+ (0.1,0) [0|0] "" Vector__XXX
 SG_ VCLEFT_TLCState_Fog m1 : 38|3@1+ (1,0) [0|0] "" Vector__XXX
 SG_ VCLEFT_TLCState_Stop m1 : 35|3@1+ (1,0) [0|0] "" Vector__XXX
 SG_ VCLEFT_TLCState_Tail m1 : 32|3@1+ (1,0) [0|0] "" Vector__XXX
 SG_ VCLEFT_TLCStopCurrent m0 : 32|8@1+ (0.1,0) [0|0] "" Vector__XXX
 SG_ VCLEFT_TLCState_RightTurn m1 : 29|3@1+ (1,0) [0|0] "" Vector__XXX
 SG_ VCLEFT_TLCState_LeftTurn m1 : 26|3@1+ (1,0) [0|0] "" Vector__XXX
 SG_ VCLEFT_TLCTailCurrent m0 : 24|8@1+ (0.1,0) [0|0] "" Vector__XXX
 SG_ VCLEFT_TLCRightTurnVoltage m1 : 18|8@1+ (0.1,0) [0|0] "" Vector__XXX
 SG_ VCLEFT_TLCRightTurnCurrent m0 : 16|8@1+ (0.1,0) [0|0] "" Vector__XXX
 SG_ VCLEFT_TLCLeftTurnVoltage m1 : 10|8@1+ (0.1,0) [0|0] "" Vector__XXX
 SG_ VCLEFT_TLCLeftTurnCurrent m0 : 8|8@1+ (0.1,0) [0|0] "" Vector__XXX
 SG_ VCLEFT_TLCTemperature m1 : 2|8@1- (1,68) [0|0] "" Vector__XXX
 SG_ VCLEFT_TLCStatusIndex M : 0|2@1+ (1,0) [0|0] "" Vector__XXX

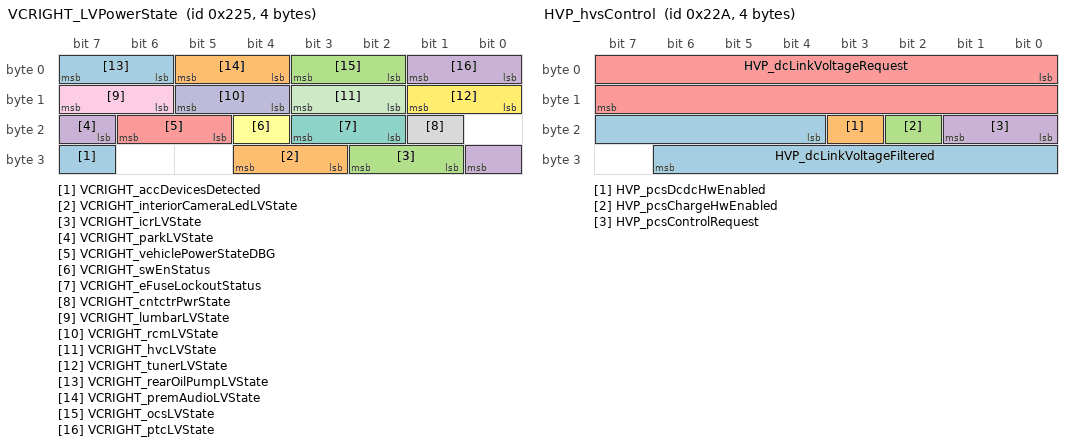
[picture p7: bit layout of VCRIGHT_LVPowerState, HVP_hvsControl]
BO_ 549 VCRIGHT_LVPowerState: 4 Vector__XXX
 SG_ VCRIGHT_accDevicesDetected : 31|1@1+ (1,0) [0|0] "" Vector__XXX
 SG_ VCRIGHT_interiorCameraLedLVState : 27|2@1+ (1,0) [0|0] "" Vector__XXX
 SG_ VCRIGHT_icrLVState : 25|2@1+ (1,0) [0|0] "" Vector__XXX
 SG_ VCRIGHT_parkLVState : 23|2@1+ (1,0) [0|0] "" Vector__XXX
 SG_ VCRIGHT_vehiclePowerStateDBG : 21|2@1+ (1,0) [0|0] "" Vector__XXX
 SG_ VCRIGHT_swEnStatus : 20|1@1+ (1,0) [0|0] "" Vector__XXX
 SG_ VCRIGHT_eFuseLockoutStatus : 18|2@1+ (1,0) [0|0] "" Vector__XXX
 SG_ VCRIGHT_cntctrPwrState : 17|1@1+ (1,0) [0|0] "" Vector__XXX
 SG_ VCRIGHT_lumbarLVState : 14|2@1+ (1,0) [0|0] "" Vector__XXX
 SG_ VCRIGHT_rcmLVState : 12|2@1+ (1,0) [0|0] "" Vector__XXX
 SG_ VCRIGHT_hvcLVState : 10|2@1+ (1,0) [0|0] "" Vector__XXX
 SG_ VCRIGHT_tunerLVState : 8|2@1+ (1,0) [0|0] "" Vector__XXX
 SG_ VCRIGHT_rearOilPumpLVState : 6|2@1+ (1,0) [0|0] "" Vector__XXX
 SG_ VCRIGHT_premAudioLVState : 4|2@1+ (1,0) [0|0] "" Vector__XXX
 SG_ VCRIGHT_ocsLVState : 2|2@1+ (1,0) [0|0] "" Vector__XXX
 SG_ VCRIGHT_ptcLVState : 0|2@1+ (1,0) [0|0] "" Vector__XXX

BO_ 554 HVP_hvsControl: 4 Vector__XXX
 SG_ HVP_dcLinkVoltageFiltered : 20|11@1- (1,0) [0|0] "" Vector__XXX
 SG_ HVP_pcsDcdcHwEnabled : 19|1@1+ (1,0) [0|0] "" Vector__XXX
 SG_ HVP_pcsChargeHwEnabled : 18|1@1+ (1,0) [0|0] "" Vector__XXX
 SG_ HVP_pcsControlRequest : 16|2@1+ (1,0) [0|0] "" Vector__XXX
 SG_ HVP_dcLinkVoltageRequest : 0|16@1- (0.1,0) [0|0] "" Vector__XXX

BO_ 555 DAS_matrixHighBeamRequest: 8 Vector__XXX
 SG_ DAS_azimuthSegmentLightRequests : 0|64@1+ (1,0) [0|0] "" Vector__XXX

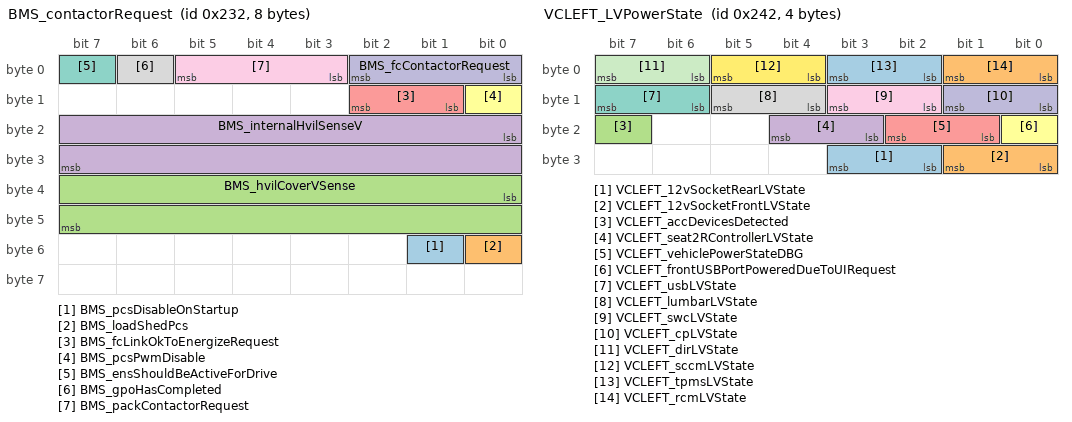
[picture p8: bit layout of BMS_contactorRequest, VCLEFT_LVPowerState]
BO_ 562 BMS_contactorRequest: 8 Vector__XXX
 SG_ BMS_pcsDisableOnStartup : 49|1@1+ (1,0) [0|0] "" Vector__XXX
 SG_ BMS_loadShedPcs : 48|1@1+ (1,0) [0|0] "" Vector__XXX
 SG_ BMS_hvilCoverVSense : 32|16@1+ (0.001,0) [0|0] "" Vector__XXX
 SG_ BMS_internalHvilSenseV : 16|16@1+ (0.001,0) [0|0] "" Vector__XXX
 SG_ BMS_fcLinkOkToEnergizeRequest : 9|2@1+ (1,0) [0|0] "" Vector__XXX
 SG_ BMS_pcsPwmDisable : 8|1@1+ (1,0) [0|0] "" Vector__XXX
 SG_ BMS_ensShouldBeActiveForDrive : 7|1@1+ (1,0) [0|0] "" Vector__XXX
 SG_ BMS_gpoHasCompleted : 6|1@1+ (1,0) [0|0] "" Vector__XXX
 SG_ BMS_packContactorRequest : 3|3@1+ (1,0) [0|0] "" Vector__XXX
 SG_ BMS_fcContactorRequest : 0|3@1+ (1,0) [0|0] "" Vector__XXX

BO_ 564 DCDC_power: 8 Vector__XXX
 SG_ DCDC_powerChecksum : 56|8@1+ (1,0) [0|0] "" Vector__XXX
 SG_ DCDC_powerCounter : 52|4@1+ (1,0) [0|0] "" Vector__XXX
 SG_ DCDC_powerMuxIndex M : 50|2@1+ (1,0) [0|0] "" Vector__XXX
 SG_ DCDC_type m0 : 45|2@1+ (1,0) [0|0] "" Vector__XXX
 SG_ DCDC_auxiliaryStageSaturationWarning m0 : 44|1@1+ (1,0) [0|0] "" Vector__XXX
 SG_ DCDC_packSideContLvOutputPowerLimit m1 : 40|10@1+ (10,0) [0|0] "" Vector__XXX
 SG_ DCDC_instantLvOutputPowerLimit m0 : 34|10@1+ (10,0) [0|0] "" Vector__XXX
 SG_ DCDC_minTargetContLvOutputPowerLimit m1 : 30|10@1+ (10,0) [0|0] "" Vector__XXX
 SG_ DCDC_continuousLvOutputPowerLimit m0 : 24|10@1+ (10,0) [0|0] "" Vector__XXX
 SG_ DCDC_severeOvLvInputPowerLimit m1 : 20|10@1+ (10,0) [0|0] "" Vector__XXX
 SG_ DCDC_filteredLvOutputPowerEstimated m0 : 12|12@1- (10,0) [0|0] "" Vector__XXX
 SG_ DCDC_severeUvLvOutputPowerLimit m1 : 10|10@1+ (10,0) [0|0] "" Vector__XXX
 SG_ DCDC_instantLvOutputPowerEstimated m0 : 0|12@1- (10,0) [0|0] "" Vector__XXX
 SG_ DCDC_transientLvOutputPowerLimit m1 : 0|10@1+ (10,0) [0|0] "" Vector__XXX

BO_ 578 VCLEFT_LVPowerState: 4 Vector__XXX
 SG_ VCLEFT_12vSocketRearLVState : 26|2@1+ (1,0) [0|0] "" Vector__XXX
 SG_ VCLEFT_12vSocketFrontLVState : 24|2@1+ (1,0) [0|0] "" Vector__XXX
 SG_ VCLEFT_accDevicesDetected : 23|1@1+ (1,0) [0|0] "" Vector__XXX
 SG_ VCLEFT_seat2RControllerLVState : 19|2@1+ (1,0) [0|0] "" Vector__XXX
 SG_ VCLEFT_vehiclePowerStateDBG : 17|2@1+ (1,0) [0|0] "" Vector__XXX
 SG_ VCLEFT_frontUSBPortPoweredDueToUIRequest : 16|1@1+ (1,0) [0|0] "" Vector__XXX
 SG_ VCLEFT_usbLVState : 14|2@1+ (1,0) [0|0] "" Vector__XXX
 SG_ VCLEFT_lumbarLVState : 12|2@1+ (1,0) [0|0] "" Vector__XXX
 SG_ VCLEFT_swcLVState : 10|2@1+ (1,0) [0|0] "" Vector__XXX
 SG_ VCLEFT_cpLVState : 8|2@1+ (1,0) [0|0] "" Vector__XXX
 SG_ VCLEFT_dirLVState : 6|2@1+ (1,0) [0|0] "" Vector__XXX
 SG_ VCLEFT_sccmLVState : 4|2@1+ (1,0) [0|0] "" Vector__XXX
 SG_ VCLEFT_tpmsLVState : 2|2@1+ (1,0) [0|0] "" Vector__XXX
 SG_ VCLEFT_rcmLVState : 0|2@1+ (1,0) [0|0] "" Vector__XXX

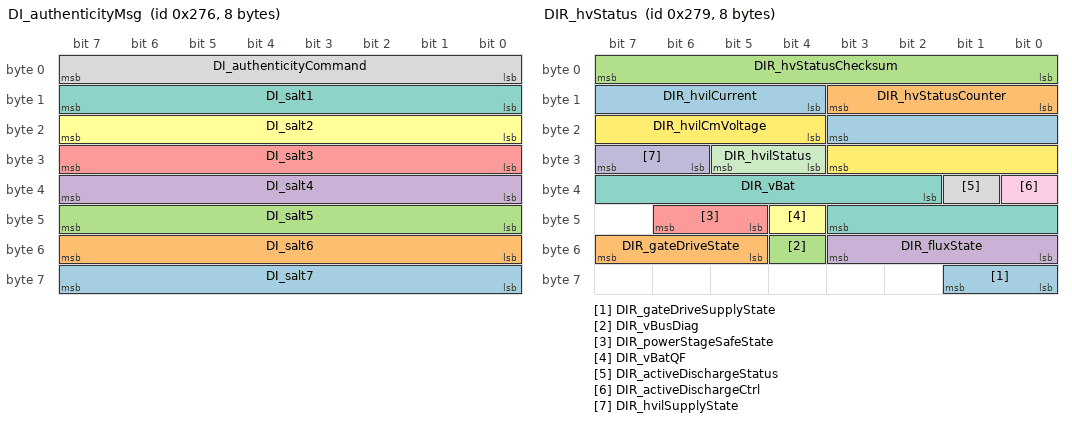
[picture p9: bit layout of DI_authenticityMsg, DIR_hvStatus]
BO_ 630 DI_authenticityMsg: 8 Vector__XXX
 SG_ DI_salt7 : 56|8@1+ (1,0) [0|0] "" Vector__XXX
 SG_ DI_salt6 : 48|8@1+ (1,0) [0|0] "" Vector__XXX
 SG_ DI_salt5 : 40|8@1+ (1,0) [0|0] "" Vector__XXX
 SG_ DI_salt4 : 32|8@1+ (1,0) [0|0] "" Vector__XXX
 SG_ DI_salt3 : 24|8@1+ (1,0) [0|0] "" Vector__XXX
 SG_ DI_salt2 : 16|8@1+ (1,0) [0|0] "" Vector__XXX
 SG_ DI_salt1 : 8|8@1+ (1,0) [0|0] "" Vector__XXX
 SG_ DI_authenticityCommand : 0|8@1+ (1,0) [0|0] "" Vector__XXX

BO_ 633 DIR_hvStatus: 8 Vector__XXX
 SG_ DIR_gateDriveSupplyState : 56|2@1+ (1,0) [0|0] "" Vector__XXX
 SG_ DIR_gateDriveState : 53|3@1+ (1,0) [0|0] "" Vector__XXX
 SG_ DIR_vBusDiag : 52|1@1+ (1,0) [0|0] "" Vector__XXX
 SG_ DIR_fluxState : 48|4@1+ (1,0) [0|0] "" Vector__XXX
 SG_ DIR_powerStageSafeState : 45|2@1+ (1,0) [0|0] "" Vector__XXX
 SG_ DIR_vBatQF : 44|1@1+ (1,0) [0|0] "" Vector__XXX
 SG_ DIR_vBat : 34|10@1+ (1,0) [0|0] "" Vector__XXX
 SG_ DIR_activeDischargeStatus : 33|1@1+ (1,0) [0|0] "" Vector__XXX
 SG_ DIR_activeDischargeCtrl : 32|1@1+ (1,0) [0|0] "" Vector__XXX
 SG_ DIR_hvilSupplyState : 30|2@1+ (1,0) [0|0] "" Vector__XXX
 SG_ DIR_hvilStatus : 28|2@1+ (1,0) [0|0] "" Vector__XXX
 SG_ DIR_hvilCmVoltage : 20|8@1+ (0.08,0) [0|0] "" Vector__XXX
 SG_ DIR_hvilCurrent : 12|8@1+ (0.1,0) [0|0] "" Vector__XXX
 SG_ DIR_hvStatusCounter : 8|4@1+ (1,0) [0|0] "" Vector__XXX
 SG_ DIR_hvStatusChecksum : 0|8@1+ (1,0) [0|0] "" Vector__XXX

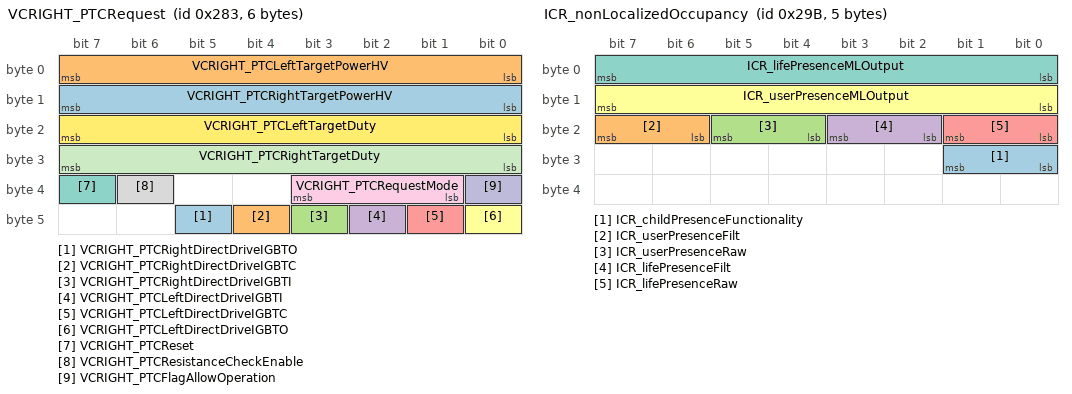
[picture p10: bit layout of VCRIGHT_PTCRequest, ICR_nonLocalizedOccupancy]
BO_ 643 VCRIGHT_PTCRequest: 6 Vector__XXX
 SG_ VCRIGHT_PTCRightDirectDriveIGBTO : 45|1@1+ (1,0) [0|0] "" Vector__XXX
 SG_ VCRIGHT_PTCRightDirectDriveIGBTC : 44|1@1+ (1,0) [0|0] "" Vector__XXX
 SG_ VCRIGHT_PTCRightDirectDriveIGBTI : 43|1@1+ (1,0) [0|0] "" Vector__XXX
 SG_ VCRIGHT_PTCLeftDirectDriveIGBTI : 42|1@1+ (1,0) [0|0] "" Vector__XXX
 SG_ VCRIGHT_PTCLeftDirectDriveIGBTC : 41|1@1+ (1,0) [0|0] "" Vector__XXX
 SG_ VCRIGHT_PTCLeftDirectDriveIGBTO : 40|1@1+ (1,0) [0|0] "" Vector__XXX
 SG_ VCRIGHT_PTCReset : 39|1@1+ (1,0) [0|0] "" Vector__XXX
 SG_ VCRIGHT_PTCResistanceCheckEnable : 38|1@1+ (1,0) [0|0] "" Vector__XXX
 SG_ VCRIGHT_PTCRequestMode : 33|3@1+ (1,0) [0|0] "" Vector__XXX
 SG_ VCRIGHT_PTCFlagAllowOperation : 32|1@1+ (1,0) [0|0] "" Vector__XXX
 SG_ VCRIGHT_PTCRightTargetDuty : 24|8@1+ (0.5,0) [0|0] "" Vector__XXX
 SG_ VCRIGHT_PTCLeftTargetDuty : 16|8@1+ (0.5,0) [0|0] "" Vector__XXX
 SG_ VCRIGHT_PTCRightTargetPowerHV : 8|8@1+ (30,0) [0|0] "" Vector__XXX
 SG_ VCRIGHT_PTCLeftTargetPowerHV : 0|8@1+ (30,0) [0|0] "" Vector__XXX

BO_ 649 VCLEFT_logging10Hz: 8 Vector__XXX
 SG_ VCLEFT_hvacBlowerRsOnlineActive m0 : 63|1@1+ (1,0) [0|0] "" Vector__XXX
 SG_ VCLEFT_hvacBlowerSpiError m0 : 62|1@1+ (1,0) [0|0] "" Vector__XXX
 SG_ VCLEFT_hvacBlowerITerm m0 : 55|7@1+ (0.05,-1.5) [0|0] "" Vector__XXX
 SG_ VCLEFT_hvacBlowerCBCCtrlState m0 : 52|3@1+ (1,0) [0|0] "" Vector__XXX
 SG_ VCLEFT_hvacBlowerCBCEstState m0 : 48|4@1+ (1,0) [0|0] "" Vector__XXX
 SG_ VCLEFT_hvacBlower_IO_CBC_numUartErr m0 : 40|8@1+ (1,0) [0|0] "" Vector__XXX
 SG_ VCLEFT_hvacBlower_IO_CBC_Status m0 : 39|1@1+ (1,0) [0|0] "" Vector__XXX
 SG_ VCLEFT_hvacBlower_IO_CBC_TAIL_valid m0 : 38|1@1+ (1,0) [0|0] "" Vector__XXX
 SG_ VCLEFT_hvacBlower_IO_CBC_TAIL m0 : 34|4@1+ (1,0) [0|0] "" Vector__XXX
 SG_ VCLEFT_hvacBlower_IO_CBC_HEAD m0 : 30|4@1+ (1,0) [0|0] "" Vector__XXX
 SG_ VCLEFT_hvacBlowerIPhase2 m0 : 23|7@1+ (0.4,0) [0|0] "" Vector__XXX
 SG_ VCLEFT_hvacBlowerIPhase1 m0 : 16|7@1+ (0.4,0) [0|0] "" Vector__XXX
 SG_ VCLEFT_hvacBlowerIPhase0 m0 : 9|7@1+ (0.4,0) [0|0] "" Vector__XXX
 SG_ VCLEFT_hvacBlowerRs m0 : 1|8@1+ (0.25,0) [0|0] "" Vector__XXX
 SG_ VCLEFT_logging10HzIndex M : 0|1@1+ (1,0) [0|0] "" Vector__XXX

BO_ 660 UI_vehicleControl3: 8 Vector__XXX
 SG_ UI_selfParkStandingBy : 62|1@1+ (1,0) [0|0] "" Vector__XXX
 SG_ UI_derivedLoadshedFeature : 59|1@1+ (1,0) [0|0] "" Vector__XXX
 SG_ UI_closeTrunkRequest : 55|1@1+ (1,0) [0|0] "" Vector__XXX
 SG_ UI_windowRequest : 52|3@1+ (1,0) [0|0] "" Vector__XXX
 SG_ UI_windowRequestedRR : 51|1@1+ (1,0) [0|0] "" Vector__XXX
 SG_ UI_windowRequestedRL : 50|1@1+ (1,0) [0|0] "" Vector__XXX
 SG_ UI_windowRequestedFR : 49|1@1+ (1,0) [0|0] "" Vector__XXX
 SG_ UI_windowRequestedFL : 48|1@1+ (1,0) [0|0] "" Vector__XXX
 SG_ UI_windowPercentageRequest : 42|6@1- (5,0) [0|0] "" Vector__XXX
 SG_ UI_keepOnAccessoryPortsReq : 38|1@1+ (1,0) [0|0] "" Vector__XXX
 SG_ UI_blindSpotIndicatorLightRequest : 35|1@1+ (1,0) [0|0] "" Vector__XXX
 SG_ UI_displayRedShiftActive : 24|1@1+ (1,0) [0|0] "" Vector__XXX
 SG_ UI_UMC3UpdateInhibit : 22|1@1+ (1,0) [0|0] "" Vector__XXX
 SG_ UI_packTempLoggingRequest : 18|1@1+ (1,0) [0|0] "" Vector__XXX
 SG_ UI_shortHornRequest : 17|1@1+ (1,0) [0|0] "" Vector__XXX
 SG_ UI_VCSECFeature5 : 16|1@1+ (1,0) [0|0] "" Vector__XXX
 SG_ UI_VCSECFeature4 : 15|1@1+ (1,0) [0|0] "" Vector__XXX
 SG_ UI_VCSECFeature3 : 14|1@1+ (1,0) [0|0] "" Vector__XXX
 SG_ UI_VCSECFeature2 : 13|1@1+ (1,0) [0|0] "" Vector__XXX
 SG_ UI_headlightPulseRequest : 12|1@1+ (1,0) [0|0] "" Vector__XXX
 SG_ UI_steeringWheelHeatLevelReq : 10|2@1+ (1,0) [0|0] "" Vector__XXX
 SG_ UI_steeringWheelHeatAutoReq : 9|1@1+ (1,0) [0|0] "" Vector__XXX
 SG_ UI_lightShowClosuresEnabled : 8|1@1+ (1,0) [0|0] "" Vector__XXX
 SG_ UI_keyPairResponse : 6|2@1+ (1,0) [0|0] "" Vector__XXX
 SG_ UI_drivingSideVEH : 4|2@1+ (1,0) [0|0] "" Vector__XXX
 SG_ UI_phoneCallActive : 3|1@1+ (1,0) [0|0] "" Vector__XXX
 SG_ UI_keylessDrivingEnabled : 2|1@1+ (1,0) [0|0] "" Vector__XXX
 SG_ UI_lightFlashRequest : 0|2@1+ (1,0) [0|0] "" Vector__XXX

BO_ 661 UI_powerRationalityConfig: 8 Vector__XXX
 SG_ UI_powerRationalityConfigIndex M : 56|8@1+ (1,0) [0|0] "" Vector__XXX
 SG_ UI_vcleftCfgCutoffDynamicC m8 : 32|16@1- (50,0) [0|0] "" Vector__XXX
 SG_ UI_vcleftCfgCutoffStaticC m7 : 32|16@1- (50,0) [0|0] "" Vector__XXX
 SG_ UI_vcleftCfgRationalityDynamicC m2 : 32|16@1- (50,0) [0|0] "" Vector__XXX
 SG_ UI_vcleftCfgRationalityStaticC m1 : 32|16@1- (50,0) [0|0] "" Vector__XXX
 SG_ UI_vcrightCfgCutoffDynamicC m11 : 32|16@1- (50,0) [0|0] "" Vector__XXX
 SG_ UI_vcrightCfgCutoffStaticC m10 : 32|16@1- (50,0) [0|0] "" Vector__XXX
 SG_ UI_vcrightCfgRationalityDynamicC m5 : 32|16@1- (50,0) [0|0] "" Vector__XXX
 SG_ UI_vcrightCfgRationalityStaticC m4 : 32|16@1- (50,0) [0|0] "" Vector__XXX
 SG_ UI_vcleftCfgCutoffDynamicB m8 : 16|16@1- (1,0) [0|0] "" Vector__XXX
 SG_ UI_vcleftCfgCutoffStaticB m7 : 16|16@1- (1,0) [0|0] "" Vector__XXX
 SG_ UI_vcleftCfgRationalityDynamicB m2 : 16|16@1- (1,0) [0|0] "" Vector__XXX
 SG_ UI_vcleftCfgRationalityStaticB m1 : 16|16@1- (1,0) [0|0] "" Vector__XXX
 SG_ UI_vcrightCfgCutoffDynamicB m11 : 16|16@1- (1,0) [0|0] "" Vector__XXX
 SG_ UI_vcrightCfgCutoffStaticB m10 : 16|16@1- (1,0) [0|0] "" Vector__XXX
 SG_ UI_vcrightCfgRationalityDynamicB m5 : 16|16@1- (1,0) [0|0] "" Vector__XXX
 SG_ UI_vcrightCfgRationalityStaticB m4 : 16|16@1- (1,0) [0|0] "" Vector__XXX
 SG_ UI_vcleftCfgCutoffTime1 m6 : 12|4@1+ (1,0) [0|0] "" Vector__XXX
 SG_ UI_vcleftCfgRationalityTime1 m0 : 12|4@1+ (1,0) [0|0] "" Vector__XXX
 SG_ UI_vcrightCfgCutoffTime1 m9 : 12|4@1+ (1,0) [0|0] "" Vector__XXX
 SG_ UI_vcrightCfgRationalityTime1 m3 : 12|4@1+ (1,0) [0|0] "" Vector__XXX
 SG_ UI_vcleftCfgCutoffThreshold1 m6 : 8|4@1+ (1,0) [0|0] "" Vector__XXX
 SG_ UI_vcleftCfgRationalityThreshold1 m0 : 8|4@1+ (1,0) [0|0] "" Vector__XXX
 SG_ UI_vcrightCfgCutoffThreshold1 m9 : 8|4@1+ (1,0) [0|0] "" Vector__XXX
 SG_ UI_vcrightCfgRationalityThreshold1 m3 : 8|4@1+ (1,0) [0|0] "" Vector__XXX
 SG_ UI_vcleftCfgCutoffTime0 m6 : 4|4@1+ (1,0) [0|0] "" Vector__XXX
 SG_ UI_vcleftCfgRationalityTime0 m0 : 4|4@1+ (1,0) [0|0] "" Vector__XXX
 SG_ UI_vcrightCfgCutoffTime0 m9 : 4|4@1+ (1,0) [0|0] "" Vector__XXX
 SG_ UI_vcrightCfgRationalityTime0 m3 : 4|4@1+ (1,0) [0|0] "" Vector__XXX
 SG_ UI_vcleftCfgCutoffDynamicA m8 : 0|16@1+ (50,0) [0|0] "" Vector__XXX
 SG_ UI_vcleftCfgCutoffStaticA m7 : 0|16@1+ (50,0) [0|0] "" Vector__XXX
 SG_ UI_vcleftCfgCutoffThreshold0 m6 : 0|4@1+ (1,0) [0|0] "" Vector__XXX
 SG_ UI_vcleftCfgRationalityDynamicA m2 : 0|16@1+ (50,0) [0|0] "" Vector__XXX
 SG_ UI_vcleftCfgRationalityStaticA m1 : 0|16@1+ (50,0) [0|0] "" Vector__XXX
 SG_ UI_vcleftCfgRationalityThreshold0 m0 : 0|4@1+ (1,0) [0|0] "" Vector__XXX
 SG_ UI_vcrightCfgCutoffDynamicA m11 : 0|16@1+ (50,0) [0|0] "" Vector__XXX
 SG_ UI_vcrightCfgCutoffStaticA m10 : 0|16@1+ (50,0) [0|0] "" Vector__XXX
 SG_ UI_vcrightCfgCutoffThreshold0 m9 : 0|4@1+ (1,0) [0|0] "" Vector__XXX
 SG_ UI_vcrightCfgRationalityDynamicA m5 : 0|16@1+ (50,0) [0|0] "" Vector__XXX
 SG_ UI_vcrightCfgRationalityStaticA m4 : 0|16@1+ (50,0) [0|0] "" Vector__XXX
 SG_ UI_vcrightCfgRationalityThreshold0 m3 : 0|4@1+ (1,0) [0|0] "" Vector__XXX

BO_ 667 ICR_nonLocalizedOccupancy: 5 Vector__XXX
 SG_ ICR_childPresenceFunctionality : 24|2@1+ (1,0) [0|0] "" Vector__XXX
 SG_ ICR_userPresenceFilt : 22|2@1+ (1,0) [0|0] "" Vector__XXX
 SG_ ICR_userPresenceRaw : 20|2@1+ (1,0) [0|0] "" Vector__XXX
 SG_ ICR_lifePresenceFilt : 18|2@1+ (1,0) [0|0] "" Vector__XXX
 SG_ ICR_lifePresenceRaw : 16|2@1+ (1,0) [0|0] "" Vector__XXX
 SG_ ICR_userPresenceMLOutput : 8|8@1+ (0.004,0) [0|0] "" Vector__XXX
 SG_ ICR_lifePresenceMLOutput : 0|8@1+ (0.004,0) [0|0] "" Vector__XXX

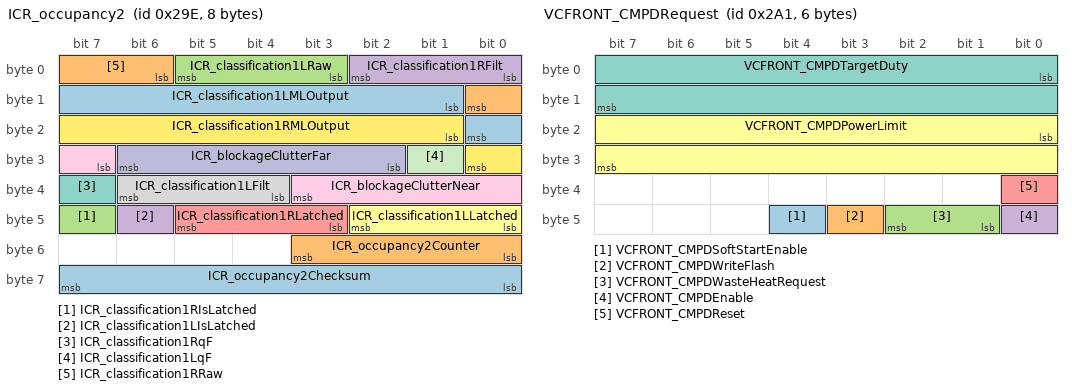
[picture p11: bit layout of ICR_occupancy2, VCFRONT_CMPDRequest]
BO_ 670 ICR_occupancy2: 8 Vector__XXX
 SG_ ICR_occupancy2Checksum : 56|8@1+ (1,0) [0|0] "" Vector__XXX
 SG_ ICR_occupancy2Counter : 48|4@1+ (1,0) [0|0] "" Vector__XXX
 SG_ ICR_classification1RIsLatched : 47|1@1+ (1,0) [0|0] "" Vector__XXX
 SG_ ICR_classification1LIsLatched : 46|1@1+ (1,0) [0|0] "" Vector__XXX
 SG_ ICR_classification1RLatched : 43|3@1+ (1,0) [0|0] "" Vector__XXX
 SG_ ICR_classification1LLatched : 40|3@1+ (1,0) [0|0] "" Vector__XXX
 SG_ ICR_classification1RqF : 39|1@1+ (1,0) [0|0] "" Vector__XXX
 SG_ ICR_classification1LFilt : 36|3@1+ (1,0) [0|0] "" Vector__XXX
 SG_ ICR_blockageClutterNear : 31|5@1- (0.5,-1.5) [0|0] "" Vector__XXX
 SG_ ICR_blockageClutterFar : 26|5@1- (0.5,-1.5) [0|0] "" Vector__XXX
 SG_ ICR_classification1LqF : 25|1@1+ (1,0) [0|0] "" Vector__XXX
 SG_ ICR_classification1RMLOutput : 17|8@1+ (0.004,0) [0|0] "" Vector__XXX
 SG_ ICR_classification1LMLOutput : 9|8@1+ (0.004,0) [0|0] "" Vector__XXX
 SG_ ICR_classification1RRaw : 6|3@1+ (1,0) [0|0] "" Vector__XXX
 SG_ ICR_classification1LRaw : 3|3@1+ (1,0) [0|0] "" Vector__XXX
 SG_ ICR_classification1RFilt : 0|3@1+ (1,0) [0|0] "" Vector__XXX

BO_ 673 VCFRONT_CMPDRequest: 6 Vector__XXX
 SG_ VCFRONT_CMPDSoftStartEnable : 44|1@1+ (1,0) [0|0] "" Vector__XXX
 SG_ VCFRONT_CMPDWriteFlash : 43|1@1+ (1,0) [0|0] "" Vector__XXX
 SG_ VCFRONT_CMPDWasteHeatRequest : 41|2@1+ (1,0) [0|0] "" Vector__XXX
 SG_ VCFRONT_CMPDEnable : 40|1@1+ (1,0) [0|0] "" Vector__XXX
 SG_ VCFRONT_CMPDReset : 32|1@1+ (1,0) [0|0] "" Vector__XXX
 SG_ VCFRONT_CMPDPowerLimit : 16|16@1+ (1,0) [0|0] "" Vector__XXX
 SG_ VCFRONT_CMPDTargetDuty : 0|16@1+ (0.1,0) [0|0] "" Vector__XXX

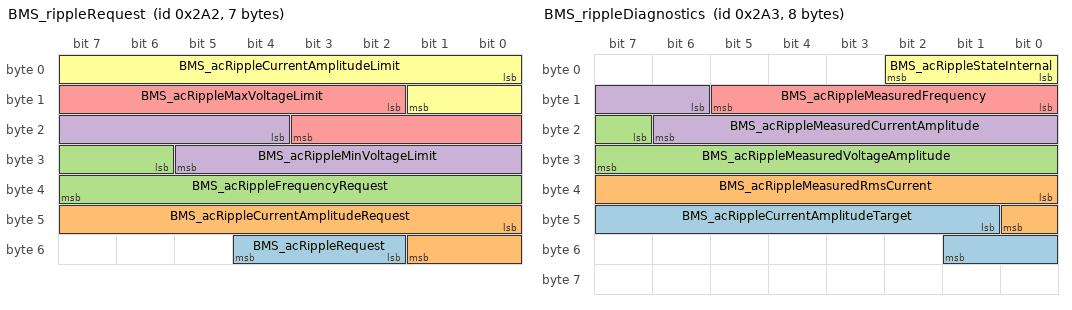
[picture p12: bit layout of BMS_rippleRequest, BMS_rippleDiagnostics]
BO_ 674 BMS_rippleRequest: 7 Vector__XXX
 SG_ BMS_acRippleRequest : 50|3@1+ (1,0) [0|0] "" Vector__XXX
 SG_ BMS_acRippleCurrentAmplitudeRequest : 40|10@1+ (1,0) [0|0] "" Vector__XXX
 SG_ BMS_acRippleFrequencyRequest : 30|10@1+ (1,0) [0|0] "" Vector__XXX
 SG_ BMS_acRippleMinVoltageLimit : 20|10@1+ (1,0) [0|0] "" Vector__XXX
 SG_ BMS_acRippleMaxVoltageLimit : 10|10@1+ (1,0) [0|0] "" Vector__XXX
 SG_ BMS_acRippleCurrentAmplitudeLimit : 0|10@1+ (1,0) [0|0] "" Vector__XXX

BO_ 675 BMS_rippleDiagnostics: 8 Vector__XXX
 SG_ BMS_acRippleCurrentAmplitudeTarget : 41|9@1+ (1,0) [0|0] "" Vector__XXX
 SG_ BMS_acRippleMeasuredRmsCurrent : 32|9@1+ (1,0) [0|0] "" Vector__XXX
 SG_ BMS_acRippleMeasuredVoltageAmplitude : 23|9@1+ (1,0) [0|0] "" Vector__XXX
 SG_ BMS_acRippleMeasuredCurrentAmplitude : 14|9@1+ (1,0) [0|0] "" Vector__XXX
 SG_ BMS_acRippleMeasuredFrequency : 8|6@1+ (1,80) [0|0] "" Vector__XXX
 SG_ BMS_acRippleStateInternal : 0|3@1+ (1,0) [0|0] "" Vector__XXX

BO_ 678 CMPD_motorState: 8 Vector__XXX
 SG_ CMPD_motorOverloadCountdown : 16|13@1+ (1,0) [0|0] "" Vector__XXX
 SG_ CMPD_motorCurrent : 0|16@1+ (0.1,0) [0|0] "" Vector__XXX

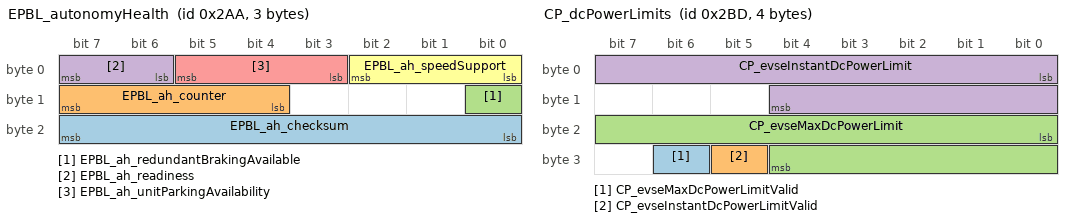
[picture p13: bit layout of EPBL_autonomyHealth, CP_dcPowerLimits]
BO_ 682 EPBL_autonomyHealth: 3 Vector__XXX
 SG_ EPBL_ah_checksum : 16|8@1+ (1,0) [0|0] "" Vector__XXX
 SG_ EPBL_ah_counter : 12|4@1+ (1,0) [0|0] "" Vector__XXX
 SG_ EPBL_ah_redundantBrakingAvailable : 8|1@1+ (1,0) [0|0] "" Vector__XXX
 SG_ EPBL_ah_readiness : 6|2@1+ (1,0) [0|0] "" Vector__XXX
 SG_ EPBL_ah_unitParkingAvailability : 3|3@1+ (1,0) [0|0] "" Vector__XXX
 SG_ EPBL_ah_speedSupport : 0|3@1+ (1,0) [0|0] "" Vector__XXX

BO_ 701 CP_dcPowerLimits: 4 Vector__XXX
 SG_ CP_evseMaxDcPowerLimitValid : 30|1@1+ (1,0) [0|0] "" Vector__XXX
 SG_ CP_evseInstantDcPowerLimitValid : 29|1@1+ (1,0) [0|0] "" Vector__XXX
 SG_ CP_evseMaxDcPowerLimit : 16|13@1+ (0.25,0) [0|0] "" Vector__XXX
 SG_ CP_evseInstantDcPowerLimit : 0|13@1+ (0.25,0) [0|0] "" Vector__XXX

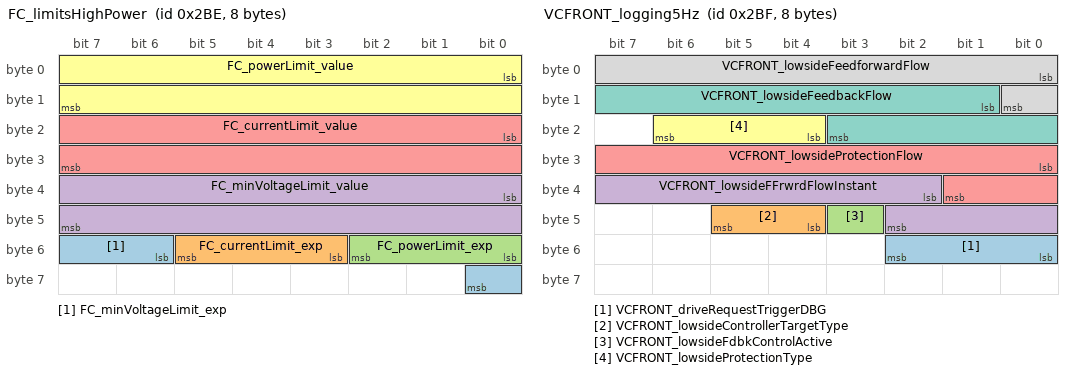
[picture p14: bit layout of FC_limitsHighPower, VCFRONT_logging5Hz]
BO_ 702 FC_limitsHighPower: 8 Vector__XXX
 SG_ FC_minVoltageLimit_exp : 54|3@1- (1,0) [0|0] "" Vector__XXX
 SG_ FC_currentLimit_exp : 51|3@1- (1,0) [0|0] "" Vector__XXX
 SG_ FC_powerLimit_exp : 48|3@1- (1,0) [0|0] "" Vector__XXX
 SG_ FC_minVoltageLimit_value : 32|16@1- (1,0) [0|0] "" Vector__XXX
 SG_ FC_currentLimit_value : 16|16@1- (1,0) [0|0] "" Vector__XXX
 SG_ FC_powerLimit_value : 0|16@1- (1,0) [0|0] "" Vector__XXX

BO_ 703 VCFRONT_logging5Hz: 8 Vector__XXX
 SG_ VCFRONT_driveRequestTriggerDBG : 48|3@1+ (1,0) [0|0] "" Vector__XXX
 SG_ VCFRONT_lowsideControllerTargetType : 44|2@1+ (1,0) [0|0] "" Vector__XXX
 SG_ VCFRONT_lowsideFdbkControlActive : 43|1@1+ (1,0) [0|0] "" Vector__XXX
 SG_ VCFRONT_lowsideFFrwrdFlowInstant : 34|9@1+ (0.2,0) [0|0] "" Vector__XXX
 SG_ VCFRONT_lowsideProtectionFlow : 24|10@1+ (0.1,0) [0|0] "" Vector__XXX
 SG_ VCFRONT_lowsideProtectionType : 20|3@1+ (1,0) [0|0] "" Vector__XXX
 SG_ VCFRONT_lowsideFeedbackFlow : 9|11@1- (0.1,0) [0|0] "" Vector__XXX
 SG_ VCFRONT_lowsideFeedforwardFlow : 0|9@1+ (0.2,0) [0|0] "" Vector__XXX

BO_ 706 VCLEFT_windowStatus: 8 Vector__XXX
 SG_ VCLEFT_windowCalibratedLR m0 : 63|1@1+ (1,0) [0|0] "" Vector__XXX
 SG_ VCLEFT_windowSpeedTableStatusLR m1 : 62|2@1+ (1,0) [0|0] "" Vector__XXX
 SG_ VCLEFT_windowSpeedTableStatusLF m1 : 60|2@1+ (1,0) [0|0] "" Vector__XXX
 SG_ VCLEFT_windowVehGearStateLR m1 : 58|2@1+ (1,0) [0|0] "" Vector__XXX
 SG_ VCLEFT_windowVehGearStateLF m1 : 56|2@1+ (1,0) [0|0] "" Vector__XXX
 SG_ VCLEFT_windowPositionLR m0 : 54|9@1- (1.25,265) [0|0] "" Vector__XXX
 SG_ VCLEFT_windowPositionStateLR m1 : 52|3@1+ (1,0) [0|0] "" Vector__XXX
 SG_ VCLEFT_windowPositionStateLF m1 : 49|3@1+ (1,0) [0|0] "" Vector__XXX
 SG_ VCLEFT_windowCurrentLR m0 : 48|6@1- (0.5,0) [0|0] "" Vector__XXX
 SG_ VCLEFT_windowCtrlUnavailableLR m1 : 45|3@1+ (1,0) [0|0] "" Vector__XXX
 SG_ VCLEFT_windowControlStateLR m1 : 42|2@1+ (1,0) [0|0] "" Vector__XXX
 SG_ VCLEFT_windowDutyLR m0 : 40|6@1- (5,0) [0|0] "" Vector__XXX
 SG_ VCLEFT_windowCtrlUnavailableLF m1 : 38|3@1+ (1,0) [0|0] "" Vector__XXX
 SG_ VCLEFT_windowControlStateLF m1 : 35|2@1+ (1,0) [0|0] "" Vector__XXX
 SG_ VCLEFT_windowStateLR m0 : 33|4@1+ (1,0) [0|0] "" Vector__XXX
 SG_ VCLEFT_windowCalibratedLF m0 : 32|1@1+ (1,0) [0|0] "" Vector__XXX
 SG_ VCLEFT_windowStopReqReasonLR m1 : 31|4@1+ (1,0) [0|0] "" Vector__XXX
 SG_ VCLEFT_windowStopReasonLR m1 : 28|3@1+ (1,0) [0|0] "" Vector__XXX
 SG_ VCLEFT_windowThermalModeLR m1 : 26|2@1+ (1,0) [0|0] "" Vector__XXX
 SG_ VCLEFT_windowPositionLF m0 : 22|9@1- (1.25,265) [0|0] "" Vector__XXX
 SG_ VCLEFT_windowThermalTCLR m1 : 18|8@1+ (1,0) [0|0] "" Vector__XXX
 SG_ VCLEFT_windowCurrentLF m0 : 16|6@1- (0.5,0) [0|0] "" Vector__XXX
 SG_ VCLEFT_windowStopReqReasonLF m1 : 14|4@1+ (1,0) [0|0] "" Vector__XXX
 SG_ VCLEFT_windowTrimClearActiveRequest m0 : 14|2@1+ (1,0) [0|0] "" Vector__XXX
 SG_ VCLEFT_windowStopReasonLF m1 : 11|3@1+ (1,0) [0|0] "" Vector__XXX
 SG_ VCLEFT_windowThermalModeLF m1 : 9|2@1+ (1,0) [0|0] "" Vector__XXX
 SG_ VCLEFT_windowDutyLF m0 : 8|6@1- (5,0) [0|0] "" Vector__XXX
 SG_ VCLEFT_windowTrimClearMoveRequest m0 : 5|2@1+ (1,0) [0|0] "" Vector__XXX
 SG_ VCLEFT_windowStateLF m0 : 1|4@1+ (1,0) [0|0] "" Vector__XXX
 SG_ VCLEFT_windowThermalTCLF m1 : 1|8@1+ (1,0) [0|0] "" Vector__XXX
 SG_ VCLEFT_windowStatusIndex M : 0|1@1+ (1,0) [0|0] "" Vector__XXX

BO_ 707 VCRIGHT_windowStatus: 8 Vector__XXX
 SG_ VCRIGHT_windowCalibratedRR m0 : 63|1@1+ (1,0) [0|0] "" Vector__XXX
 SG_ VCRIGHT_windowSpeedTableStatusRR m1 : 62|2@1+ (1,0) [0|0] "" Vector__XXX
 SG_ VCRIGHT_windowSpeedTableStatusRF m1 : 60|2@1+ (1,0) [0|0] "" Vector__XXX
 SG_ VCRIGHT_windowVehGearStateRR m1 : 58|2@1+ (1,0) [0|0] "" Vector__XXX
 SG_ VCRIGHT_windowVehGearStateRF m1 : 56|2@1+ (1,0) [0|0] "" Vector__XXX
 SG_ VCRIGHT_windowPositionRR m0 : 54|9@1- (1.25,265) [0|0] "" Vector__XXX
 SG_ VCRIGHT_windowPositionStateRR m1 : 52|3@1+ (1,0) [0|0] "" Vector__XXX
 SG_ VCRIGHT_windowPositionStateRF m1 : 49|3@1+ (1,0) [0|0] "" Vector__XXX
 SG_ VCRIGHT_windowCurrentRR m0 : 48|6@1- (0.5,0) [0|0] "" Vector__XXX
 SG_ VCRIGHT_windowCtrlUnavailableRR m1 : 45|3@1+ (1,0) [0|0] "" Vector__XXX
 SG_ VCRIGHT_windowControlStateRR m1 : 42|2@1+ (1,0) [0|0] "" Vector__XXX
 SG_ VCRIGHT_windowDutyRR m0 : 40|6@1- (5,0) [0|0] "" Vector__XXX
 SG_ VCRIGHT_windowCtrlUnavailableRF m1 : 38|3@1+ (1,0) [0|0] "" Vector__XXX
 SG_ VCRIGHT_windowControlStateRF m1 : 35|2@1+ (1,0) [0|0] "" Vector__XXX
 SG_ VCRIGHT_windowStateRR m0 : 33|4@1+ (1,0) [0|0] "" Vector__XXX
 SG_ VCRIGHT_windowCalibratedRF m0 : 32|1@1+ (1,0) [0|0] "" Vector__XXX
 SG_ VCRIGHT_windowStopReqReasonRR m1 : 31|4@1+ (1,0) [0|0] "" Vector__XXX
 SG_ VCRIGHT_windowStopReasonRR m1 : 28|3@1+ (1,0) [0|0] "" Vector__XXX
 SG_ VCRIGHT_windowThermalModeRR m1 : 26|2@1+ (1,0) [0|0] "" Vector__XXX
 SG_ VCRIGHT_windowPositionRF m0 : 22|9@1- (1.25,265) [0|0] "" Vector__XXX
 SG_ VCRIGHT_windowThermalTCRR m1 : 18|8@1+ (1,0) [0|0] "" Vector__XXX
 SG_ VCRIGHT_windowCurrentRF m0 : 16|6@1- (0.5,0) [0|0] "" Vector__XXX
 SG_ VCRIGHT_windowStopReqReasonRF m1 : 14|4@1+ (1,0) [0|0] "" Vector__XXX
 SG_ VCRIGHT_windowTrimClearActiveRequest m0 : 14|2@1+ (1,0) [0|0] "" Vector__XXX
 SG_ VCRIGHT_windowStopReasonRF m1 : 11|3@1+ (1,0) [0|0] "" Vector__XXX
 SG_ VCRIGHT_windowThermalModeRF m1 : 9|2@1+ (1,0) [0|0] "" Vector__XXX
 SG_ VCRIGHT_windowDutyRF m0 : 8|6@1- (5,0) [0|0] "" Vector__XXX
 SG_ VCRIGHT_windowTrimClearMoveRequest m0 : 5|2@1+ (1,0) [0|0] "" Vector__XXX
 SG_ VCRIGHT_windowStateRF m0 : 1|4@1+ (1,0) [0|0] "" Vector__XXX
 SG_ VCRIGHT_windowThermalTCRF m1 : 1|8@1+ (1,0) [0|0] "" Vector__XXX
 SG_ VCRIGHT_windowStatusIndex M : 0|1@1+ (1,0) [0|0] "" Vector__XXX

BO_ 711 CMPD_faultsAndExtras: 8 Vector__XXX
 SG_ CMPD_inputLVVoltage : 56|8@1+ (0.1,0) [0|0] "" Vector__XXX
 SG_ CMPD_inverterTemperature : 48|8@1+ (1,-40) [0|0] "" Vector__XXX
 SG_ CMPD_IGBTTemperature : 40|8@1+ (1,-40) [0|0] "" Vector__XXX
 SG_ CMPD_overloadDetectionOfSpeed : 32|1@1+ (1,0) [0|0] "" Vector__XXX
 SG_ CMPD_overloadRestrictionCurrent : 31|1@1+ (1,0) [0|0] "" Vector__XXX
 SG_ CMPD_overloadLossOfSync : 30|1@1+ (1,0) [0|0] "" Vector__XXX
 SG_ CMPD_overloadStartFaultDetection : 29|1@1+ (1,0) [0|0] "" Vector__XXX
 SG_ CMPD_overloadStatus : 27|2@1+ (1,0) [0|0] "" Vector__XXX
 SG_ CMPD_overCurrent : 26|1@1+ (1,0) [0|0] "" Vector__XXX
 SG_ CMPD_failedStartRepeated : 25|1@1+ (1,0) [0|0] "" Vector__XXX
 SG_ CMPD_failedStart : 24|1@1+ (1,0) [0|0] "" Vector__XXX
 SG_ CMPD_underTemperature : 23|1@1+ (1,0) [0|0] "" Vector__XXX
 SG_ CMPD_overTemperature : 22|1@1+ (1,0) [0|0] "" Vector__XXX
 SG_ CMPD_warnOverTemperature : 21|1@1+ (1,0) [0|0] "" Vector__XXX
 SG_ CMPD_shortCircuit : 20|1@1+ (1,0) [0|0] "" Vector__XXX
 SG_ CMPD_inverterOpenCircuit : 19|1@1+ (1,0) [0|0] "" Vector__XXX
 SG_ CMPD_internalPowerSupplyFault : 18|1@1+ (1,0) [0|0] "" Vector__XXX
 SG_ CMPD_selfTestFailCPU : 17|1@1+ (1,0) [0|0] "" Vector__XXX
 SG_ CMPD_currentSnsError : 16|1@1+ (1,0) [0|0] "" Vector__XXX
 SG_ CMPD_tempSnsFaultCPU : 15|1@1+ (1,0) [0|0] "" Vector__XXX
 SG_ CMPD_tempSnsFaultIPM2 : 14|1@1+ (1,0) [0|0] "" Vector__XXX
 SG_ CMPD_tempSnsFaultIPM1 : 13|1@1+ (1,0) [0|0] "" Vector__XXX
 SG_ CMPD_HVUnderVoltage : 12|1@1+ (1,0) [0|0] "" Vector__XXX
 SG_ CMPD_HVOverVoltage : 11|1@1+ (1,0) [0|0] "" Vector__XXX
 SG_ CMPD_LVOverVoltage : 10|1@1+ (1,0) [0|0] "" Vector__XXX
 SG_ CMPD_LVUnderVoltage : 9|1@1+ (1,0) [0|0] "" Vector__XXX
 SG_ CMPD_VCFRONTCANTimeout : 8|1@1+ (1,0) [0|0] "" Vector__XXX
 SG_ CMPD_limitOverCurrentHVDC : 2|1@1+ (1,0) [0|0] "" Vector__XXX
 SG_ CMPD_limitOverCurrentPhase : 1|1@1+ (1,0) [0|0] "" Vector__XXX
 SG_ CMPD_limitUnderVoltage : 0|1@1+ (1,0) [0|0] "" Vector__XXX

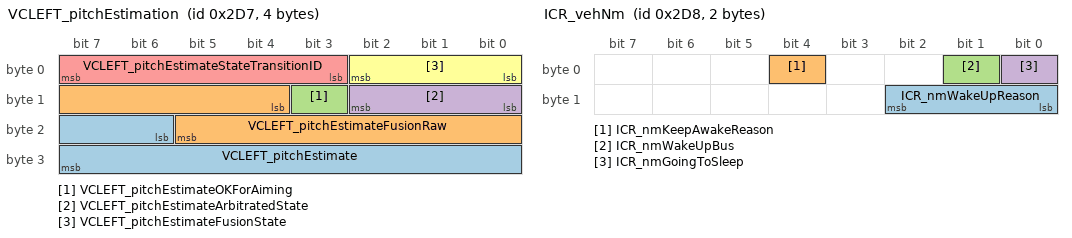
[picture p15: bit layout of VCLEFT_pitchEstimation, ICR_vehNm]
BO_ 727 VCLEFT_pitchEstimation: 4 Vector__XXX
 SG_ VCLEFT_pitchEstimate : 22|10@1- (0.0002,0) [0|0] "" Vector__XXX
 SG_ VCLEFT_pitchEstimateFusionRaw : 12|10@1- (0.0002,0) [0|0] "" Vector__XXX
 SG_ VCLEFT_pitchEstimateOKForAiming : 11|1@1+ (1,0) [0|0] "" Vector__XXX
 SG_ VCLEFT_pitchEstimateArbitratedState : 8|3@1+ (1,0) [0|0] "" Vector__XXX
 SG_ VCLEFT_pitchEstimateStateTransitionID : 3|5@1+ (1,0) [0|0] "" Vector__XXX
 SG_ VCLEFT_pitchEstimateFusionState : 0|3@1+ (1,0) [0|0] "" Vector__XXX

BO_ 728 ICR_vehNm: 2 Vector__XXX
 SG_ ICR_nmWakeUpReason : 8|3@1+ (1,0) [0|0] "" Vector__XXX
 SG_ ICR_nmKeepAwakeReason : 4|1@1+ (1,0) [0|0] "" Vector__XXX
 SG_ ICR_nmWakeUpBus : 1|1@1+ (1,0) [0|0] "" Vector__XXX
 SG_ ICR_nmGoingToSleep : 0|1@1+ (1,0) [0|0] "" Vector__XXX

BO_ 738 VCLEFT_seatStatus2: 8 Vector__XXX
 SG_ VC_AH_1RowLeftSeatHeatVentHealth m0 : 62|2@1+ (1,0) [0|0] "" Vector__XXX
 SG_ VC_AH_2RowCenterSeatHeatVentHealth m4 : 62|2@1+ (1,0) [0|0] "" Vector__XXX
 SG_ VC_AH_2RowLeftSeatHeatVentHealth m3 : 62|2@1+ (1,0) [0|0] "" Vector__XXX
 SG_ VC_AH_2RowRightSeatHeatVentHealth m5 : 62|2@1+ (1,0) [0|0] "" Vector__XXX
 SG_ VCLEFT_2RowSeatCenterSwitchVoltage m7 : 54|10@1+ (0.01,0) [0|0] "" Vector__XXX
 SG_ VCLEFT_rearCenterBuckleVoltage m2 : 52|8@1+ (0.02,0) [0|0] "" Vector__XXX
 SG_ VCLEFT_frontSeatHeatPowered m0 : 45|1@1+ (1,0) [0|0] "" Vector__XXX
 SG_ VCLEFT_rearCHeatPowered m4 : 45|1@1+ (1,0) [0|0] "" Vector__XXX
 SG_ VCLEFT_rearLBackHeatPowered m1 : 45|1@1+ (1,0) [0|0] "" Vector__XXX
 SG_ VCLEFT_rearLHeatPowered m3 : 45|1@1+ (1,0) [0|0] "" Vector__XXX
 SG_ VCLEFT_rearRCushionHeatPowered m5 : 45|1@1+ (1,0) [0|0] "" Vector__XXX
 SG_ VCLEFT_2RowSeatEasyEntrySwitchVoltage m7 : 44|10@1+ (0.01,0) [0|0] "" Vector__XXX
 SG_ VCLEFT_frontSeatHeatInhibited m0 : 44|1@1+ (1,0) [0|0] "" Vector__XXX
 SG_ VCLEFT_rearCHeatInhibited m4 : 44|1@1+ (1,0) [0|0] "" Vector__XXX
 SG_ VCLEFT_rearLBackHeatInhibited m1 : 44|1@1+ (1,0) [0|0] "" Vector__XXX
 SG_ VCLEFT_rearLHeatInhibited m3 : 44|1@1+ (1,0) [0|0] "" Vector__XXX
 SG_ VCLEFT_rearRCushionHeatInhibited m5 : 44|1@1+ (1,0) [0|0] "" Vector__XXX
 SG_ VCLEFT_rearRightOccupancyVoltage m2 : 44|8@1+ (0.02,0) [0|0] "" Vector__XXX
 SG_ VCLEFT_2RowSeatCenterActuatorDuty m6 : 40|12@1- (0.1,0) [0|0] "" Vector__XXX
 SG_ VCLEFT_frontSeatHeatTmpTarget m0 : 36|8@1- (0.5,0) [0|0] "" Vector__XXX
 SG_ VCLEFT_rearCHeatTmpTarget m4 : 36|8@1- (0.5,0) [0|0] "" Vector__XXX
 SG_ VCLEFT_rearCenterOccupancyVoltage m2 : 36|8@1+ (0.02,0) [0|0] "" Vector__XXX
 SG_ VCLEFT_rearLBackHeatTmpTarget m1 : 36|8@1- (0.5,0) [0|0] "" Vector__XXX
 SG_ VCLEFT_rearLHeatTmpTarget m3 : 36|8@1- (0.5,0) [0|0] "" Vector__XXX
 SG_ VCLEFT_rearRCushionHeatTmpTarget m5 : 36|8@1- (0.5,0) [0|0] "" Vector__XXX
 SG_ VCLEFT_2RowSeatReclineSwitchVoltage m7 : 34|10@1+ (0.01,0) [0|0] "" Vector__XXX
 SG_ VCLEFT_2RowSeatTrackPositionSwitch m9 : 31|2@1+ (1,0) [0|0] "" Vector__XXX
 SG_ VCLEFT_2RowSeatCenterActuatorCurrent m6 : 28|12@1- (0.01,0) [0|0] "" Vector__XXX
 SG_ VCLEFT_2RowSeatEasyEntryState m9 : 28|3@1+ (1,0) [0|0] "" Vector__XXX
 SG_ VCLEFT_rearLeftOccupancyVoltage m2 : 28|8@1+ (0.02,0) [0|0] "" Vector__XXX
 SG_ VCLEFT_frontSeatHeatTmp m0 : 24|12@1- (0.05,0) [0|0] "" Vector__XXX
 SG_ VCLEFT_frontSeatLiftTiltSwitchVoltage m7 : 24|10@1+ (0.01,0) [0|0] "" Vector__XXX
 SG_ VCLEFT_rearCHeatTmp m4 : 24|12@1- (0.05,0) [0|0] "" Vector__XXX
 SG_ VCLEFT_rearLBackHeatTmp m1 : 24|12@1- (0.05,0) [0|0] "" Vector__XXX
 SG_ VCLEFT_rearLHeatTmp m3 : 24|12@1- (0.05,0) [0|0] "" Vector__XXX
 SG_ VCLEFT_rearRCushionHeatTmp m5 : 24|12@1- (0.05,0) [0|0] "" Vector__XXX
 SG_ VCLEFT_rearLeftBuckleVoltage m2 : 20|8@1+ (0.02,0) [0|0] "" Vector__XXX
 SG_ VCLEFT_2RowSeatReclineActuatorDuty m6 : 16|12@1- (0.1,0) [0|0] "" Vector__XXX
 SG_ VCLEFT_2RowSeatTrackActuatorDuty m9 : 16|12@1- (0.1,0) [0|0] "" Vector__XXX
 SG_ VCLEFT_frontSeatHeatDuty m0 : 16|8@1+ (1,0) [0|0] "" Vector__XXX
 SG_ VCLEFT_rearCHeatDuty m4 : 16|8@1+ (1,0) [0|0] "" Vector__XXX
 SG_ VCLEFT_rearLBackHeatDuty m1 : 16|8@1+ (1,0) [0|0] "" Vector__XXX
 SG_ VCLEFT_rearLHeatDuty m3 : 16|8@1+ (1,0) [0|0] "" Vector__XXX
 SG_ VCLEFT_rearRCushionHeatDuty m5 : 16|8@1+ (1,0) [0|0] "" Vector__XXX
 SG_ VCLEFT_frontSeatLumbarSwitchVoltage m7 : 14|10@1+ (0.01,0) [0|0] "" Vector__XXX
 SG_ VCLEFT_trunkFoldFlatRightSwitchVoltage m8 : 14|10@1+ (0.01,0) [0|0] "" Vector__XXX
 SG_ VCLEFT_frontBuckleVoltage m2 : 12|8@1+ (0.02,0) [0|0] "" Vector__XXX
 SG_ VCLEFT_2RowSeatReclineActuatorCurrent m6 : 4|12@1- (0.01,0) [0|0] "" Vector__XXX
 SG_ VCLEFT_2RowSeatTrackActuatorCurrent m9 : 4|12@1- (0.01,0) [0|0] "" Vector__XXX
 SG_ VCLEFT_frontOccupancyVoltage m2 : 4|8@1+ (0.02,0) [0|0] "" Vector__XXX
 SG_ VCLEFT_frontSeatHeatCurrent m0 : 4|12@1+ (0.01,0) [0|0] "" Vector__XXX
 SG_ VCLEFT_frontSeatTrackBackrestSwitchVoltage m7 : 4|10@1+ (0.01,0) [0|0] "" Vector__XXX
 SG_ VCLEFT_rearCHeatCurrent m4 : 4|12@1+ (0.01,0) [0|0] "" Vector__XXX
 SG_ VCLEFT_rearLBackHeatCurrent m1 : 4|12@1+ (0.01,0) [0|0] "" Vector__XXX
 SG_ VCLEFT_rearLHeatCurrent m3 : 4|12@1+ (0.01,0) [0|0] "" Vector__XXX
 SG_ VCLEFT_rearRCushionHeatCurrent m5 : 4|12@1+ (0.01,0) [0|0] "" Vector__XXX
 SG_ VCLEFT_trunkFoldFlatLeftSwitchVoltage m8 : 4|10@1+ (0.004887585532746823,0) [0|0] "" Vector__XXX
 SG_ VCLEFT_seatStatus2Index M : 0|4@1+ (1,0) [0|0] "" Vector__XXX

BO_ 739 VCRIGHT_seatStatus2: 7 Vector__XXX
 SG_ VC_AH_1RowRightSeatHeatVentHealth m0 : 54|2@1+ (1,0) [0|0] "" Vector__XXX
 SG_ VCRIGHT_occupantClassificationHoldState m4 : 46|2@1+ (1,0) [0|0] "" Vector__XXX
 SG_ VCRIGHT_frontSeatHeatPowered m0 : 45|1@1+ (1,0) [0|0] "" Vector__XXX
 SG_ VCRIGHT_rearCSeatHeatPowered m2 : 45|1@1+ (1,0) [0|0] "" Vector__XXX
 SG_ VCRIGHT_rearLSeatHeatPowered m1 : 45|1@1+ (1,0) [0|0] "" Vector__XXX
 SG_ VCRIGHT_rearRSeatHeatPowered m3 : 45|1@1+ (1,0) [0|0] "" Vector__XXX
 SG_ VCRIGHT_2RowSeatEasyEntrySwitchVoltage m7 : 44|10@1+ (0.01,0) [0|0] "" Vector__XXX
 SG_ VCRIGHT_frontSeatHeatInhibited m0 : 44|1@1+ (1,0) [0|0] "" Vector__XXX
 SG_ VCRIGHT_rearCSeatHeatInhibited m2 : 44|1@1+ (1,0) [0|0] "" Vector__XXX
 SG_ VCRIGHT_rearLSeatHeatInhibited m1 : 44|1@1+ (1,0) [0|0] "" Vector__XXX
 SG_ VCRIGHT_rearRSeatHeatInhibited m3 : 44|1@1+ (1,0) [0|0] "" Vector__XXX
 SG_ VCRIGHT_frontSeatHeatTmpTarget m0 : 36|8@1- (0.5,0) [0|0] "" Vector__XXX
 SG_ VCRIGHT_rearCSeatHeatTmpTarget m2 : 36|8@1- (0.5,0) [0|0] "" Vector__XXX
 SG_ VCRIGHT_rearLSeatHeatTmpTarget m1 : 36|8@1- (0.5,0) [0|0] "" Vector__XXX
 SG_ VCRIGHT_rearRSeatHeatTmpTarget m3 : 36|8@1- (0.5,0) [0|0] "" Vector__XXX
 SG_ VCRIGHT_2RowSeatReclineSwitchVoltage m7 : 34|10@1+ (0.01,0) [0|0] "" Vector__XXX
 SG_ VCRIGHT_rearRightBuckleVoltage m4 : 34|10@1+ (0.01,0) [0|0] "" Vector__XXX
 SG_ VCRIGHT_ocsIEEState m10 : 32|3@1+ (1,0) [0|0] "" Vector__XXX
 SG_ VCRIGHT_2RowSeatTrackPositionSwitch m9 : 31|2@1+ (1,0) [0|0] "" Vector__XXX
 SG_ VCRIGHT_2RowSeatEasyEntryState m9 : 28|3@1+ (1,0) [0|0] "" Vector__XXX
 SG_ VCRIGHT_3RUSBPortsCurrentAvg m6 : 28|8@1+ (0.01,0) [0|0] "" Vector__XXX
 SG_ VCRIGHT_frontSeatHeatTmp m0 : 24|12@1- (0.05,0) [0|0] "" Vector__XXX
 SG_ VCRIGHT_frontSeatLiftTiltSwitchVoltage m7 : 24|10@1+ (0.01,0) [0|0] "" Vector__XXX
 SG_ VCRIGHT_rearCSeatHeatTmp m2 : 24|12@1- (0.05,0) [0|0] "" Vector__XXX
 SG_ VCRIGHT_rearCenterBuckleVoltage m4 : 24|10@1+ (0.01,0) [0|0] "" Vector__XXX
 SG_ VCRIGHT_rearLSeatHeatTmp m1 : 24|12@1- (0.05,0) [0|0] "" Vector__XXX
 SG_ VCRIGHT_rearRSeatHeatTmp m3 : 24|12@1- (0.05,0) [0|0] "" Vector__XXX
 SG_ VCRIGHT_ocsIEEPowerCurrent m10 : 20|12@1+ (0.001,0) [0|0] "" Vector__XXX
 SG_ VCRIGHT_ocsIEESnsrPassSeatCalRespSts m10 : 18|2@1+ (1,0) [0|0] "" Vector__XXX
 SG_ VCRIGHT_ocsIEEReqOfClrOfFlt m10 : 17|1@1+ (1,0) [0|0] "" Vector__XXX
 SG_ VCRIGHT_2RowSeatReclineActuatorDuty m6 : 16|12@1- (0.1,0) [0|0] "" Vector__XXX
 SG_ VCRIGHT_2RowSeatTrackActuatorDuty m9 : 16|12@1- (0.1,0) [0|0] "" Vector__XXX
 SG_ VCRIGHT_frontSeatHeatDuty m0 : 16|8@1+ (1,0) [0|0] "" Vector__XXX
 SG_ VCRIGHT_ocsIEEReqOfPassSeatCal m10 : 16|1@1+ (1,0) [0|0] "" Vector__XXX
 SG_ VCRIGHT_rearCSeatHeatDuty m2 : 16|8@1+ (1,0) [0|0] "" Vector__XXX
 SG_ VCRIGHT_rearLSeatHeatDuty m1 : 16|8@1+ (1,0) [0|0] "" Vector__XXX
 SG_ VCRIGHT_rearRSeatHeatDuty m3 : 16|8@1+ (1,0) [0|0] "" Vector__XXX
 SG_ VCRIGHT_ocsIEEFltResp8 m10 : 15|1@1+ (1,0) [0|0] "" Vector__XXX
 SG_ VCRIGHT_3RowSeatRightReclineSwitchVoltage m8 : 14|10@1+ (0.01,0) [0|0] "" Vector__XXX
 SG_ VCRIGHT_frontBuckleVoltage m4 : 14|10@1+ (0.01,0) [0|0] "" Vector__XXX
 SG_ VCRIGHT_frontSeatLumbarSwitchVoltage m7 : 14|10@1+ (0.01,0) [0|0] "" Vector__XXX
 SG_ VCRIGHT_ocsIEEFltResp7 m10 : 14|1@1+ (1,0) [0|0] "" Vector__XXX
 SG_ VCRIGHT_ocsIEEFltResp6 m10 : 13|1@1+ (1,0) [0|0] "" Vector__XXX
 SG_ VCRIGHT_ocsIEEFltResp5 m10 : 12|1@1+ (1,0) [0|0] "" Vector__XXX
 SG_ VCRIGHT_ocsIEEFltResp4 m10 : 11|1@1+ (1,0) [0|0] "" Vector__XXX
 SG_ VCRIGHT_ocsIEEFltResp3 m10 : 10|1@1+ (1,0) [0|0] "" Vector__XXX
 SG_ VCRIGHT_ocsIEEFltResp2 m10 : 9|1@1+ (1,0) [0|0] "" Vector__XXX
 SG_ VCRIGHT_ocsIEEFltResp1 m10 : 8|1@1+ (1,0) [0|0] "" Vector__XXX
 SG_ VCRIGHT_ocsIEEMIA m10 : 7|1@1+ (1,0) [0|0] "" Vector__XXX
 SG_ VCRIGHT_ocsIEEEcuFailr m10 : 6|1@1+ (1,0) [0|0] "" Vector__XXX
 SG_ VCRIGHT_2RowSeatReclineActuatorCurrent m6 : 4|12@1- (0.01,0) [0|0] "" Vector__XXX
 SG_ VCRIGHT_2RowSeatTrackActuatorCurrent m9 : 4|12@1- (0.01,0) [0|0] "" Vector__XXX
 SG_ VCRIGHT_3RowSeatLeftReclineSwitchVoltage m8 : 4|10@1+ (0.01,0) [0|0] "" Vector__XXX
 SG_ VCRIGHT_frontOccupancyVoltage m4 : 4|10@1+ (0.01,0) [0|0] "" Vector__XXX
 SG_ VCRIGHT_frontSeatHeatCurrent m0 : 4|12@1+ (0.01,0) [0|0] "" Vector__XXX
 SG_ VCRIGHT_frontSeatTrackBackrestSwitchVoltage m7 : 4|10@1+ (0.01,0) [0|0] "" Vector__XXX
 SG_ VCRIGHT_ocsIEEAirbAllwdSts m10 : 4|2@1+ (1,0) [0|0] "" Vector__XXX
 SG_ VCRIGHT_rearCSeatHeatCurrent m2 : 4|12@1+ (0.01,0) [0|0] "" Vector__XXX
 SG_ VCRIGHT_rearLSeatHeatCurrent m1 : 4|12@1+ (0.01,0) [0|0] "" Vector__XXX
 SG_ VCRIGHT_rearRSeatHeatCurrent m3 : 4|12@1+ (0.01,0) [0|0] "" Vector__XXX
 SG_ VCRIGHT_seatStatus2Index M : 0|4@1+ (1,0) [0|0] "" Vector__XXX

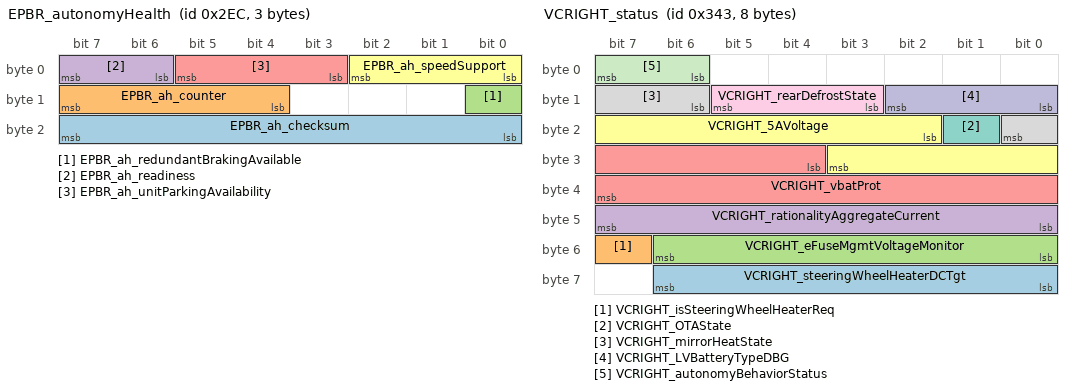
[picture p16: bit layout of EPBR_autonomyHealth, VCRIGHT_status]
BO_ 748 EPBR_autonomyHealth: 3 Vector__XXX
 SG_ EPBR_ah_checksum : 16|8@1+ (1,0) [0|0] "" Vector__XXX
 SG_ EPBR_ah_counter : 12|4@1+ (1,0) [0|0] "" Vector__XXX
 SG_ EPBR_ah_redundantBrakingAvailable : 8|1@1+ (1,0) [0|0] "" Vector__XXX
 SG_ EPBR_ah_readiness : 6|2@1+ (1,0) [0|0] "" Vector__XXX
 SG_ EPBR_ah_unitParkingAvailability : 3|3@1+ (1,0) [0|0] "" Vector__XXX
 SG_ EPBR_ah_speedSupport : 0|3@1+ (1,0) [0|0] "" Vector__XXX

BO_ 761 VCSEC_additionalAuthInfo: 8 Vector__XXX
 SG_ VCSEC_NFCAuthFromCenterConsoleFormFactor m5 : 35|3@1+ (1,0) [0|0] "" Vector__XXX
 SG_ VCSEC_BLEDeviceWithinSummonRange m4 : 32|32@1+ (1,0) [0|0] "" Vector__XXX
 SG_ VCSEC_NFCAuthFromBPillarFormFactor m5 : 32|3@1+ (1,0) [0|0] "" Vector__XXX
 SG_ VCSEC_activeKeySHA1 m0 : 32|32@1+ (1,0) [0|0] "" Vector__XXX
 SG_ VCSEC_keyWithinSummonRange0 m1 : 32|32@1+ (1,0) [0|0] "" Vector__XXX
 SG_ VCSEC_keyWithinSummonRange1 m2 : 32|32@1+ (1,0) [0|0] "" Vector__XXX
 SG_ VCSEC_keyWithinSummonRange2 m3 : 32|32@1+ (1,0) [0|0] "" Vector__XXX
 SG_ VCSEC_AdditionalAuthInfoIndex M : 27|3@1+ (1,0) [0|0] "" Vector__XXX
 SG_ VCSEC_activeKeyReason m0 : 24|3@1+ (1,0) [0|0] "" Vector__XXX
 SG_ VCSEC_bleConnetionAttemptWLEntry : 19|5@1+ (1,0) [0|0] "" Vector__XXX
 SG_ VCSEC_bleDisconnectionReason : 11|8@1+ (1,0) [0|0] "" Vector__XXX
 SG_ VCSEC_bleChannelDisconnected : 7|4@1+ (1,0) [0|0] "" Vector__XXX
 SG_ VCSEC_activeKeyDebug : 2|5@1+ (1,0) [0|0] "" Vector__XXX
 SG_ VCSEC_algoUsedForSummonRange0 m1 : 0|1@1+ (1,0) [0|0] "" Vector__XXX
 SG_ VCSEC_algoUsedForSummonRange1 m2 : 0|1@1+ (1,0) [0|0] "" Vector__XXX
 SG_ VCSEC_algoUsedForSummonRange2 m3 : 0|1@1+ (1,0) [0|0] "" Vector__XXX

BO_ 803 VCRIGHT_CPULoad: 5 Vector__XXX
 SG_ VCRIGHT_CPULoad1000msTask : 32|8@1+ (1,0) [0|0] "" Vector__XXX
 SG_ VCRIGHT_CPULoad100msTask : 24|8@1+ (1,0) [0|0] "" Vector__XXX
 SG_ VCRIGHT_CPULoad10msTask : 16|8@1+ (1,0) [0|0] "" Vector__XXX
 SG_ VCRIGHT_CPULoad1msTask : 8|8@1+ (1,0) [0|0] "" Vector__XXX
 SG_ VCRIGHT_CPULoadTotal : 0|8@1+ (1,0) [0|0] "" Vector__XXX

BO_ 804 UI_gpsTime: 8 Vector__XXX
 SG_ UI_gpsTime : 0|64@1+ (1,0) [0|0] "" Vector__XXX

BO_ 829 CP_plcInfo: 8 Vector__XXX
 SG_ CP_plcPibCrc : 32|32@1+ (1,0) [0|0] "" Vector__XXX
 SG_ CP_plcFwCrc : 0|32@1+ (1,0) [0|0] "" Vector__XXX

BO_ 835 VCRIGHT_status: 8 Vector__XXX
 SG_ VCRIGHT_steeringWheelHeaterDCTgt : 56|7@1+ (0.01,0) [0|0] "" Vector__XXX
 SG_ VCRIGHT_isSteeringWheelHeaterReq : 55|1@1+ (1,0) [0|0] "" Vector__XXX
 SG_ VCRIGHT_eFuseMgmtVoltageMonitor : 48|7@1+ (0.125,0) [0|0] "" Vector__XXX
 SG_ VCRIGHT_rationalityAggregateCurrent : 40|8@1+ (0.5,0) [0|0] "" Vector__XXX
 SG_ VCRIGHT_vbatProt : 28|12@1+ (0.005443676098,0) [0|0] "" Vector__XXX
 SG_ VCRIGHT_5AVoltage : 18|10@1+ (0.005443676098,0) [0|0] "" Vector__XXX
 SG_ VCRIGHT_OTAState : 17|1@1+ (1,0) [0|0] "" Vector__XXX
 SG_ VCRIGHT_mirrorHeatState : 14|3@1+ (1,0) [0|0] "" Vector__XXX
 SG_ VCRIGHT_rearDefrostState : 11|3@1+ (1,0) [0|0] "" Vector__XXX
 SG_ VCRIGHT_LVBatteryTypeDBG : 8|3@1+ (1,0) [0|0] "" Vector__XXX
 SG_ VCRIGHT_autonomyBehaviorStatus : 6|2@1+ (1,0) [0|0] "" Vector__XXX

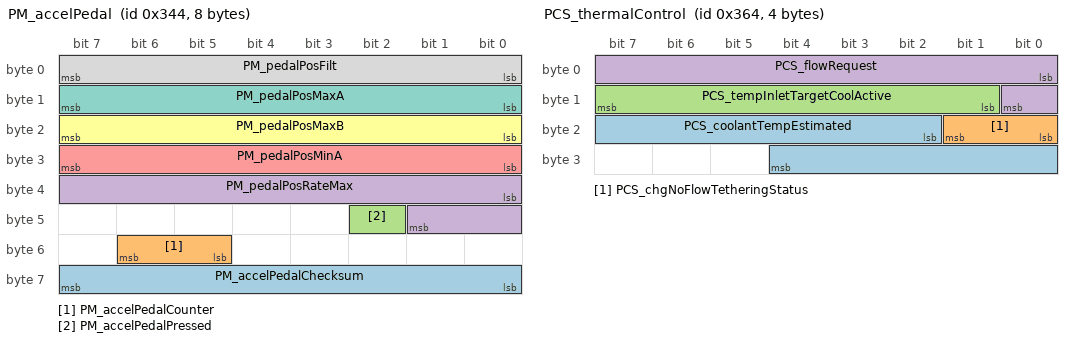
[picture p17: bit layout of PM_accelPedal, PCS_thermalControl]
BO_ 836 PM_accelPedal: 8 Vector__XXX
 SG_ PM_accelPedalChecksum : 56|8@1+ (1,0) [0|0] "" Vector__XXX
 SG_ PM_accelPedalCounter : 53|2@1+ (1,0) [0|0] "" Vector__XXX
 SG_ PM_accelPedalPressed : 42|1@1+ (1,0) [0|0] "" Vector__XXX
 SG_ PM_pedalPosRateMax : 32|10@1+ (3,0) [0|0] "" Vector__XXX
 SG_ PM_pedalPosMinA : 24|8@1+ (0.4,0) [0|0] "" Vector__XXX
 SG_ PM_pedalPosMaxB : 16|8@1+ (0.4,0) [0|0] "" Vector__XXX
 SG_ PM_pedalPosMaxA : 8|8@1+ (0.4,0) [0|0] "" Vector__XXX
 SG_ PM_pedalPosFilt : 0|8@1+ (0.4,0) [0|0] "" Vector__XXX

BO_ 842 VCSEC_NFCDebug: 8 Vector__XXX
 SG_ VCSEC_BPillarNFCStateReasonL m0 : 60|3@1+ (1,0) [0|0] "" Vector__XXX
 SG_ VCSEC_BPillarNFCStateReasonR m1 : 60|3@1+ (1,0) [0|0] "" Vector__XXX
 SG_ VCSEC_CenterNFCStateReason m2 : 60|4@1+ (1,0) [0|0] "" Vector__XXX
 SG_ VCSEC_BPillarNFCAntennaCalResultL m0 : 52|8@1+ (1,0) [0|0] "" Vector__XXX
 SG_ VCSEC_BPillarNFCAntennaCalResultR m1 : 52|8@1+ (1,0) [0|0] "" Vector__XXX
 SG_ VCSEC_CenterNFCAntennaCalResult m2 : 52|8@1+ (1,0) [0|0] "" Vector__XXX
 SG_ VCSEC_BPillarNFCDevLayerStateL m0 : 44|8@1+ (1,0) [0|0] "" Vector__XXX
 SG_ VCSEC_BPillarNFCDevLayerStateR m1 : 44|8@1+ (1,0) [0|0] "" Vector__XXX
 SG_ VCSEC_CenterNFCDevLayerState m2 : 44|8@1+ (1,0) [0|0] "" Vector__XXX
 SG_ VCSEC_BPillarNFCAmplitudeL m0 : 36|8@1+ (1,0) [0|0] "" Vector__XXX
 SG_ VCSEC_BPillarNFCAmplitudeR m1 : 36|8@1+ (1,0) [0|0] "" Vector__XXX
 SG_ VCSEC_CenterNFCAmplitude m2 : 36|8@1+ (1,0) [0|0] "" Vector__XXX
 SG_ VCSEC_BPillarNFCReaderStateL m0 : 28|2@1+ (1,0) [0|0] "" Vector__XXX
 SG_ VCSEC_BPillarNFCReaderStateR m1 : 28|2@1+ (1,0) [0|0] "" Vector__XXX
 SG_ VCSEC_CenterNFCReaderState m2 : 28|2@1+ (1,0) [0|0] "" Vector__XXX
 SG_ VCSEC_CenterNFCPhase m3 : 19|8@1+ (1,0) [0|0] "" Vector__XXX
 SG_ VCSEC_BPillarNFCWakeUpCounterL m0 : 12|16@1+ (1,0) [0|0] "" Vector__XXX
 SG_ VCSEC_BPillarNFCWakeUpCounterR m1 : 12|16@1+ (1,0) [0|0] "" Vector__XXX
 SG_ VCSEC_CenterNFCCardATQa m2 : 12|16@1+ (1,0) [0|0] "" Vector__XXX
 SG_ VCSEC_BPillarNFCPhaseR m3 : 11|8@1+ (1,0) [0|0] "" Vector__XXX
 SG_ VCSEC_BPillarNFCTrimSettingL m0 : 8|4@1+ (1,0) [0|0] "" Vector__XXX
 SG_ VCSEC_BPillarNFCTrimSettingR m1 : 8|4@1+ (1,0) [0|0] "" Vector__XXX
 SG_ VCSEC_CenterNFCTrimSetting m2 : 8|4@1+ (1,0) [0|0] "" Vector__XXX
 SG_ VCSEC_BPillarNFCCardUIDSizeL m0 : 4|4@1+ (1,0) [0|0] "" Vector__XXX
 SG_ VCSEC_BPillarNFCCardUIDSizeR m1 : 4|4@1+ (1,0) [0|0] "" Vector__XXX
 SG_ VCSEC_CenterNFCCardUIDSize m2 : 4|4@1+ (1,0) [0|0] "" Vector__XXX
 SG_ VCSEC_BPillarNFCCardCollisionL m0 : 3|1@1+ (1,0) [0|0] "" Vector__XXX
 SG_ VCSEC_BPillarNFCCardCollisionR m1 : 3|1@1+ (1,0) [0|0] "" Vector__XXX
 SG_ VCSEC_BPillarNFCPhaseL m3 : 3|8@1+ (1,0) [0|0] "" Vector__XXX
 SG_ VCSEC_CenterNFCCardCollision m2 : 3|1@1+ (1,0) [0|0] "" Vector__XXX
 SG_ VCSEC_NFCReaderIndexDebug M : 0|2@1+ (1,0) [0|0] "" Vector__XXX

BO_ 853 UI_vehicleControlThermal: 7 Vector__XXX
 SG_ UI_enableAutopilotAirPurge : 49|1@1+ (1,0) [0|0] "" Vector__XXX
 SG_ UI_enableHVACAPFanHeaterControl : 48|1@1+ (1,0) [0|0] "" Vector__XXX
 SG_ UI_enableThermalPowerBudget : 46|1@1+ (1,0) [0|0] "" Vector__XXX
 SG_ UI_isAtTeslaFacility : 45|1@1+ (1,0) [0|0] "" Vector__XXX
 SG_ UI_disablePhoneChargingPads : 43|1@1+ (1,0) [0|0] "" Vector__XXX
 SG_ UI_enableHVACCompressorWasteHeat : 42|1@1+ (1,0) [0|0] "" Vector__XXX
 SG_ UI_enableDefaultApTempTarget : 41|1@1+ (1,0) [0|0] "" Vector__XXX
 SG_ UI_enableConservativeBatteryHeating : 40|1@1+ (1,0) [0|0] "" Vector__XXX
 SG_ UI_allowConvenienceFeatures : 39|1@1+ (1,0) [0|0] "" Vector__XXX
 SG_ UI_convenienceFeatureLimit : 32|7@1+ (1,0) [0|0] "" Vector__XXX
 SG_ UI_geofencedLiftgateHeight : 24|8@1+ (1,0) [0|0] "" Vector__XXX
 SG_ UI_enableCoolantDasTarget : 23|1@1+ (1,0) [0|0] "" Vector__XXX
 SG_ UI_enableThermalDriverlessSelfTest : 22|1@1+ (1,0) [0|0] "" Vector__XXX
 SG_ UI_enableEXVFastCalibration : 21|1@1+ (1,0) [0|0] "" Vector__XXX
 SG_ UI_disableHvacCameraOnlyDefog : 20|1@1+ (1,0) [0|0] "" Vector__XXX
 SG_ UI_enableUserFacingLowFlowDeliveryAlert : 19|1@1+ (1,0) [0|0] "" Vector__XXX
 SG_ UI_enableLouverAutoDetection : 18|1@1+ (1,0) [0|0] "" Vector__XXX
 SG_ UI_enableCOP1CabinHeatingBatteryHeating : 17|1@1+ (1,0) [0|0] "" Vector__XXX
 SG_ UI_enableCOP1BatteryHeating : 16|1@1+ (1,0) [0|0] "" Vector__XXX
 SG_ UI_enableIncreasedEvapRampRate : 15|1@1+ (1,0) [0|0] "" Vector__XXX
 SG_ UI_enableCOP1HighSHOperation : 14|1@1+ (1,0) [0|0] "" Vector__XXX
 SG_ UI_enableCompLiquidPumpOut : 13|1@1+ (1,0) [0|0] "" Vector__XXX
 SG_ UI_disableHVPTThermalLoads : 12|1@1+ (1,0) [0|0] "" Vector__XXX
 SG_ UI_inletActiveCoolTarget : 5|7@1+ (1,0) [0|0] "" Vector__XXX
 SG_ UI_coolantFlowRequest : 0|5@1+ (1,0) [0|0] "" Vector__XXX

BO_ 863 BMS_gridFormControl: 1 Vector__XXX
 SG_ BMS_gridFormOutletRequest : 2|2@1+ (1,0) [0|0] "" Vector__XXX
 SG_ BMS_weldCheckCpRequest : 1|1@1+ (1,0) [0|0] "" Vector__XXX
 SG_ BMS_gridFormCpRequest : 0|1@1+ (1,0) [0|0] "" Vector__XXX

BO_ 865 VCFRONT_CPULoad: 5 Vector__XXX
 SG_ VCFRONT_CPULoad1000msTask : 32|8@1+ (1,0) [0|0] "" Vector__XXX
 SG_ VCFRONT_CPULoad100msTask : 24|8@1+ (1,0) [0|0] "" Vector__XXX
 SG_ VCFRONT_CPULoad10msTask : 16|8@1+ (1,0) [0|0] "" Vector__XXX
 SG_ VCFRONT_CPULoad1msTask : 8|8@1+ (1,0) [0|0] "" Vector__XXX
 SG_ VCFRONT_CPULoadTotal : 0|8@1+ (1,0) [0|0] "" Vector__XXX

BO_ 866 VCLEFT_crashStatus: 3 Vector__XXX
 SG_ VCLEFT_crashUnlockOverrideSet : 16|1@1+ (1,0) [0|0] "" Vector__XXX
 SG_ VCLEFT_crashNumSwitchesDisabled : 8|8@1+ (1,0) [0|0] "" Vector__XXX
 SG_ VCLEFT_crashState : 4|2@1+ (1,0) [0|0] "" Vector__XXX
 SG_ VCLEFT_crashDetectedType : 0|2@1+ (1,0) [0|0] "" Vector__XXX

BO_ 868 PCS_thermalControl: 4 Vector__XXX
 SG_ PCS_coolantTempEstimated : 18|11@1- (0.1,40) [0|0] "" Vector__XXX
 SG_ PCS_chgNoFlowTetheringStatus : 16|2@1+ (1,0) [0|0] "" Vector__XXX
 SG_ PCS_tempInletTargetCoolActive : 9|7@1+ (1,0) [0|0] "" Vector__XXX
 SG_ PCS_flowRequest : 0|9@1+ (0.1,0) [0|0] "" Vector__XXX

BO_ 870 CMPD_info: 8 Vector__XXX
 SG_ CMPD_infoComponentId m10 : 48|16@1+ (1,0) [0|0] "" Vector__XXX
 SG_ CMPD_infoSubUsageId m11 : 48|16@1+ (1,0) [0|0] "" Vector__XXX
 SG_ CMPD_infoBootCrc m20 : 32|32@1+ (1,0) [0|0] "" Vector__XXX
 SG_ CMPD_infoHardwareId m10 : 32|16@1+ (1,0) [0|0] "" Vector__XXX
 SG_ CMPD_infoUsageId m11 : 32|16@1+ (1,0) [0|0] "" Vector__XXX
 SG_ CMPD_infoAppCrc m13 : 39|32@0+ (1,0) [0|0] "" Vector__XXX
 SG_ CMPD_infoAssemblyId m11 : 24|8@1+ (1,0) [0|0] "" Vector__XXX
 SG_ CMPD_infoBuildConfigId m10 : 16|16@1+ (1,0) [0|0] "" Vector__XXX
 SG_ CMPD_infoPcbaId m11 : 16|8@1+ (1,0) [0|0] "" Vector__XXX
 SG_ CMPD_infoBootUdsProtoVersion m20 : 8|8@1+ (1,0) [0|0] "" Vector__XXX
 SG_ CMPD_infoBuildType m10 : 8|8@1+ (1,0) [0|0] "" Vector__XXX
 SG_ CMPD_infoPlatformType m13 : 8|8@1+ (1,0) [0|0] "" Vector__XXX
 SG_ CMPD_infoIndex M : 0|8@1+ (1,0) [0|0] "" Vector__XXX

BO_ 893 CP_thermalStatus: 8 Vector__XXX
 SG_ CP_pinTemp3Velocity m0 : 53|10@1- (0.15748,0) [0|0] "" Vector__XXX
 SG_ CP_pinTemp2Velocity m0 : 43|10@1- (0.15748,0) [0|0] "" Vector__XXX
 SG_ CP_pinTemp4Velocity m1 : 40|10@1- (0.15748,0) [0|0] "" Vector__XXX
 SG_ CP_pinTemp1Velocity m0 : 33|10@1- (0.15748,0) [0|0] "" Vector__XXX
 SG_ CP_pinTemperature4 m1 : 32|8@1+ (0.8039215686,-55) [0|0] "" Vector__XXX
 SG_ CP_acPinTemperature2 m0 : 25|8@1+ (0.8039215686,-55) [0|0] "" Vector__XXX
 SG_ CP_pinTemperature3 m1 : 24|8@1+ (0.8039215686,-55) [0|0] "" Vector__XXX
 SG_ CP_acPinTemperature m0 : 17|8@1+ (0.8039215686,-55) [0|0] "" Vector__XXX
 SG_ CP_pinTemperature2 m1 : 16|8@1+ (0.8039215686,-55) [0|0] "" Vector__XXX
 SG_ CP_dcPinTemperature2 m0 : 9|8@1+ (0.8039215686,-55) [0|0] "" Vector__XXX
 SG_ CP_pinTemperature1 m1 : 8|8@1+ (0.8039215686,-55) [0|0] "" Vector__XXX
 SG_ CP_dcPinTemperature m0 : 1|8@1+ (0.8039215686,-55) [0|0] "" Vector__XXX
 SG_ CP_thermalStatusSelect M : 0|1@1+ (1,0) [0|0] "" Vector__XXX

BO_ 898 VCLEFT_CPULoad: 5 Vector__XXX
 SG_ VCLEFT_CPULoad1000msTask : 32|8@1+ (1,0) [0|0] "" Vector__XXX
 SG_ VCLEFT_CPULoad100msTask : 24|8@1+ (1,0) [0|0] "" Vector__XXX
 SG_ VCLEFT_CPULoad10msTask : 16|8@1+ (1,0) [0|0] "" Vector__XXX
 SG_ VCLEFT_CPULoad1msTask : 8|8@1+ (1,0) [0|0] "" Vector__XXX
 SG_ VCLEFT_CPULoadTotal : 0|8@1+ (1,0) [0|0] "" Vector__XXX

BO_ 902 PMR_alertMatrix1: 8 Vector__XXX
 SG_ PMR_a064_torqueIntervention : 63|1@1+ (1,0) [0|0] "" Vector__XXX
 SG_ PMR_a062_eccError : 61|1@1+ (1,0) [0|0] "" Vector__XXX
 SG_ PMR_a061_DIPMVersionMismatch : 60|1@1+ (1,0) [0|0] "" Vector__XXX
 SG_ PMR_a057_canDataBusB : 56|1@1+ (1,0) [0|0] "" Vector__XXX
 SG_ PMR_a056_canHardwareBusB : 55|1@1+ (1,0) [0|0] "" Vector__XXX
 SG_ PMR_a055_resolver : 54|1@1+ (1,0) [0|0] "" Vector__XXX
 SG_ PMR_a054_uiMIA : 53|1@1+ (1,0) [0|0] "" Vector__XXX
 SG_ PMR_a053_vcfrontMIA : 52|1@1+ (1,0) [0|0] "" Vector__XXX
 SG_ PMR_a045_motorMovementDetected : 44|1@1+ (1,0) [0|0] "" Vector__XXX
 SG_ PMR_a042_gtwMIA : 41|1@1+ (1,0) [0|0] "" Vector__XXX
 SG_ PMR_a040_pmMIA : 39|1@1+ (1,0) [0|0] "" Vector__XXX
 SG_ PMR_a039_disMIA : 38|1@1+ (1,0) [0|0] "" Vector__XXX
 SG_ PMR_a037_hvpMIA : 36|1@1+ (1,0) [0|0] "" Vector__XXX
 SG_ PMR_a036_preWatchdog : 35|1@1+ (1,0) [0|0] "" Vector__XXX
 SG_ PMR_a035_udsTransactionInitiated : 34|1@1+ (1,0) [0|0] "" Vector__XXX
 SG_ PMR_a034_trqCrossCheck : 33|1@1+ (1,0) [0|0] "" Vector__XXX
 SG_ PMR_a033_selfTest : 32|1@1+ (1,0) [0|0] "" Vector__XXX
 SG_ PMR_a032_registerConfigError : 31|1@1+ (1,0) [0|0] "" Vector__XXX
 SG_ PMR_a031_highStackUsage : 30|1@1+ (1,0) [0|0] "" Vector__XXX
 SG_ PMR_a028_torqueCmdError : 27|1@1+ (1,0) [0|0] "" Vector__XXX
 SG_ PMR_a027_torqueEstimationOutOfBounds : 26|1@1+ (1,0) [0|0] "" Vector__XXX
 SG_ PMR_a026_diHeartBeatMIA : 25|1@1+ (1,0) [0|0] "" Vector__XXX
 SG_ PMR_a025_unintendedReset : 24|1@1+ (1,0) [0|0] "" Vector__XXX
 SG_ PMR_a019_statorTempIrrational : 18|1@1+ (1,0) [0|0] "" Vector__XXX
 SG_ PMR_a018_encoderIrrational : 17|1@1+ (1,0) [0|0] "" Vector__XXX
 SG_ PMR_a017_brakeMIA : 16|1@1+ (1,0) [0|0] "" Vector__XXX
 SG_ PMR_a013_canHardwareBusA : 12|1@1+ (1,0) [0|0] "" Vector__XXX
 SG_ PMR_a012_canDataBusA : 11|1@1+ (1,0) [0|0] "" Vector__XXX
 SG_ PMR_a011_phaseCurrentIrrational : 10|1@1+ (1,0) [0|0] "" Vector__XXX
 SG_ PMR_a010_diMIA : 9|1@1+ (1,0) [0|0] "" Vector__XXX
 SG_ PMR_a008_memoryError : 7|1@1+ (1,0) [0|0] "" Vector__XXX
 SG_ PMR_a005_torqueInNeutralOrPark : 4|1@1+ (1,0) [0|0] "" Vector__XXX
 SG_ PMR_a004_excessiveDecelTorque : 3|1@1+ (1,0) [0|0] "" Vector__XXX
 SG_ PMR_a003_excessiveReversalTorque : 2|1@1+ (1,0) [0|0] "" Vector__XXX
 SG_ PMR_a002_excessiveAccelTorque : 1|1@1+ (1,0) [0|0] "" Vector__XXX
 SG_ PMR_a001_absoluteTorque : 0|1@1+ (1,0) [0|0] "" Vector__XXX

BO_ 906 VCSEC_NFCCurrentCardUID: 8 Vector__XXX
 SG_ VCSEC_BPillarNFCCardUIDL m0 : 8|56@1+ (1,0) [0|0] "" Vector__XXX
 SG_ VCSEC_BPillarNFCCardUIDR m1 : 8|56@1+ (1,0) [0|0] "" Vector__XXX
 SG_ VCSEC_CenterNFCCardUID m3 : 8|56@1+ (1,0) [0|0] "" Vector__XXX
 SG_ VCSEC_NFCReaderIndexUID M : 0|2@1+ (1,0) [0|0] "" Vector__XXX

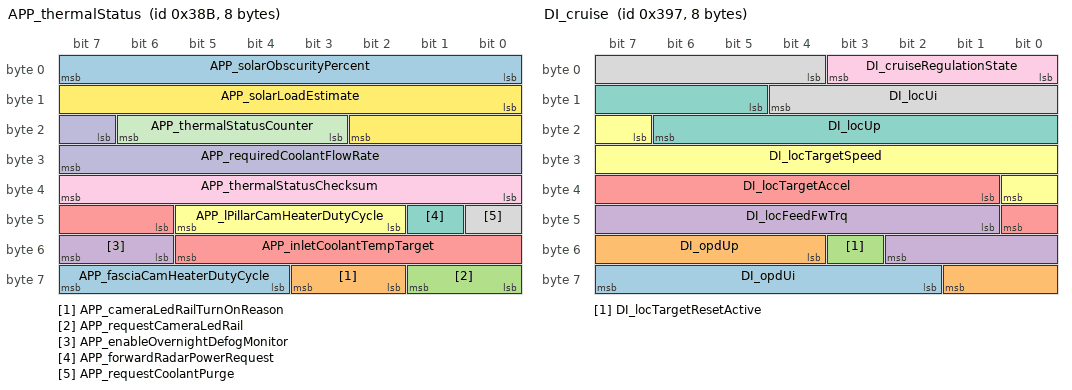
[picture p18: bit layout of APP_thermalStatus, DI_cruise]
BO_ 907 APP_thermalStatus: 8 Vector__XXX
 SG_ APP_fasciaCamHeaterDutyCycle : 60|4@1+ (0.06666666666666667,0) [0|0] "" Vector__XXX
 SG_ APP_cameraLedRailTurnOnReason : 58|2@1+ (1,0) [0|0] "" Vector__XXX
 SG_ APP_requestCameraLedRail : 56|2@1+ (1,0) [0|0] "" Vector__XXX
 SG_ APP_enableOvernightDefogMonitor : 54|2@1+ (1,0) [0|0] "" Vector__XXX
 SG_ APP_inletCoolantTempTarget : 46|8@1+ (0.5,0) [0|0] "" Vector__XXX
 SG_ APP_lPillarCamHeaterDutyCycle : 42|4@1+ (0.06666666666666667,0) [0|0] "" Vector__XXX
 SG_ APP_forwardRadarPowerRequest : 41|1@1+ (1,0) [0|0] "" Vector__XXX
 SG_ APP_requestCoolantPurge : 40|1@1+ (1,0) [0|0] "" Vector__XXX
 SG_ APP_thermalStatusChecksum : 32|8@1+ (1,0) [0|0] "" Vector__XXX
 SG_ APP_requiredCoolantFlowRate : 23|9@1+ (0.1,0) [0|0] "" Vector__XXX
 SG_ APP_thermalStatusCounter : 19|4@1+ (1,0) [0|0] "" Vector__XXX
 SG_ APP_solarLoadEstimate : 8|11@1+ (1,0) [0|0] "" Vector__XXX
 SG_ APP_solarObscurityPercent : 0|8@1+ (0.5,-25) [0|0] "" Vector__XXX

BO_ 912 UI_gridFormControl: 2 Vector__XXX
 SG_ UI_powershareRequest : 10|2@1+ (1,0) [0|0] "" Vector__XXX
 SG_ UI_v2lFeatureRequest : 9|1@1+ (1,0) [0|0] "" Vector__XXX
 SG_ UI_dischargeTerminationPct : 0|8@1+ (1,0) [0|0] "" Vector__XXX

BO_ 919 DI_cruise: 8 Vector__XXX
 SG_ DI_opdUi : 58|6@1- (40,0) [0|0] "" Vector__XXX
 SG_ DI_opdUp : 52|6@1- (40,0) [0|0] "" Vector__XXX
 SG_ DI_locTargetResetActive : 51|1@1+ (1,0) [0|0] "" Vector__XXX
 SG_ DI_locFeedFwTrq : 41|10@1- (19.569471624266146,0) [0|0] "" Vector__XXX
 SG_ DI_locTargetAccel : 33|8@1- (0.1094488188976378,-1.5322834645669292) [0|0] "" Vector__XXX
 SG_ DI_locTargetSpeed : 23|10@1- (0.25,20) [0|0] "" Vector__XXX
 SG_ DI_locUp : 13|10@1- (19.569471624266146,0) [0|0] "" Vector__XXX
 SG_ DI_locUi : 4|9@1- (19.607843137254903,0) [0|0] "" Vector__XXX
 SG_ DI_cruiseRegulationState : 0|4@1+ (1,0) [0|0] "" Vector__XXX

BO_ 922 VCSEC_RSSI: 8 Vector__XXX
 SG_ VCSEC_RSSI2ConnectionType m1 : 61|2@1+ (1,0) [0|0] "" Vector__XXX
 SG_ VCSEC_BLEDevicePresence0 m0 : 59|5@1+ (1,0) [0|0] "" Vector__XXX
 SG_ VCSEC_RSSI1ConnectionType m1 : 59|2@1+ (1,0) [0|0] "" Vector__XXX
 SG_ VCSEC_UnknownBLEDevicePresent m0 : 58|1@1+ (1,0) [0|0] "" Vector__XXX
 SG_ VCSEC_RSSI0ConnectionType m1 : 57|2@1+ (1,0) [0|0] "" Vector__XXX
 SG_ VCSEC_BLEDevicePresence3 m1 : 52|5@1+ (1,0) [0|0] "" Vector__XXX
 SG_ VCSEC_rearBLEAntennaRSSI1 m0 : 50|8@1- (1,0) [0|0] "" Vector__XXX
 SG_ VCSEC_BLEDevicePresence2 m1 : 47|5@1+ (1,0) [0|0] "" Vector__XXX
 SG_ VCSEC_BLEDevicePresence1 m1 : 42|5@1+ (1,0) [0|0] "" Vector__XXX
 SG_ VCSEC_rightBLEAntennaRSSI1 m0 : 42|8@1- (1,0) [0|0] "" Vector__XXX
 SG_ VCSEC_centerBLEAntennaRSSI2 m1 : 34|8@1- (1,0) [0|0] "" Vector__XXX
 SG_ VCSEC_leftBLEAntennaRSSI1 m0 : 34|8@1- (1,0) [0|0] "" Vector__XXX
 SG_ VCSEC_centerBLEAntennaRSSI0 m0 : 26|8@1- (1,0) [0|0] "" Vector__XXX
 SG_ VCSEC_rearBLEAntennaRSSI2 m1 : 26|8@1- (1,0) [0|0] "" Vector__XXX
 SG_ VCSEC_rearBLEAntennaRSSI0 m0 : 18|8@1- (1,0) [0|0] "" Vector__XXX
 SG_ VCSEC_rightBLEAntennaRSSI2 m1 : 18|8@1- (1,0) [0|0] "" Vector__XXX
 SG_ VCSEC_leftBLEAntennaRSSI2 m1 : 10|8@1- (1,0) [0|0] "" Vector__XXX
 SG_ VCSEC_rightBLEAntennaRSSI0 m0 : 10|8@1- (1,0) [0|0] "" Vector__XXX
 SG_ VCSEC_centerBLEAntennaRSSI1 m1 : 2|8@1- (1,0) [0|0] "" Vector__XXX
 SG_ VCSEC_leftBLEAntennaRSSI0 m0 : 2|8@1- (1,0) [0|0] "" Vector__XXX
 SG_ VCSEC_RSSIIndex M : 0|2@1+ (1,0) [0|0] "" Vector__XXX

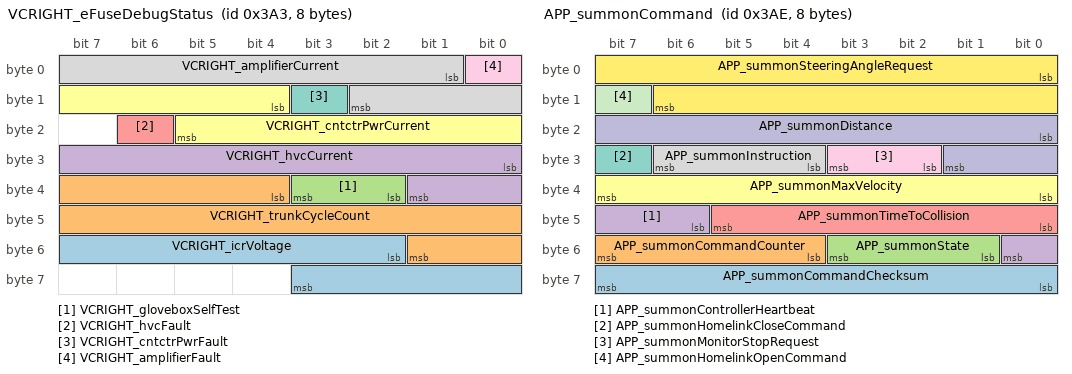
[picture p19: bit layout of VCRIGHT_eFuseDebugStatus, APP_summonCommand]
BO_ 931 VCRIGHT_eFuseDebugStatus: 8 Vector__XXX
 SG_ VCRIGHT_icrVoltage : 50|10@1+ (0.02,0) [0|0] "" Vector__XXX
 SG_ VCRIGHT_trunkCycleCount : 36|14@1+ (10,0) [0|0] "" Vector__XXX
 SG_ VCRIGHT_gloveboxSelfTest : 34|2@1+ (1,0) [0|0] "" Vector__XXX
 SG_ VCRIGHT_hvcCurrent : 24|10@1+ (0.1,0) [0|0] "" Vector__XXX
 SG_ VCRIGHT_hvcFault : 22|1@1+ (1,0) [0|0] "" Vector__XXX
 SG_ VCRIGHT_cntctrPwrCurrent : 12|10@1+ (0.1,0) [0|0] "" Vector__XXX
 SG_ VCRIGHT_cntctrPwrFault : 11|1@1+ (1,0) [0|0] "" Vector__XXX
 SG_ VCRIGHT_amplifierCurrent : 1|10@1+ (0.1,0) [0|0] "" Vector__XXX
 SG_ VCRIGHT_amplifierFault : 0|1@1+ (1,0) [0|0] "" Vector__XXX

BO_ 935 DIR_alertMatrix1: 8 Vector__XXX
 SG_ DIR_a064_torqueIntervention : 63|1@1+ (1,0) [0|0] "" Vector__XXX
 SG_ DIR_a062_systemLimpMode : 61|1@1+ (1,0) [0|0] "" Vector__XXX
 SG_ DIR_a061_heatsinkSensor : 60|1@1+ (1,0) [0|0] "" Vector__XXX
 SG_ DIR_a060_heatsinkUT : 59|1@1+ (1,0) [0|0] "" Vector__XXX
 SG_ DIR_a059_heatsinkOT : 58|1@1+ (1,0) [0|0] "" Vector__XXX
 SG_ DIR_a058_ambientSensor : 57|1@1+ (1,0) [0|0] "" Vector__XXX
 SG_ DIR_a057_ambientUT : 56|1@1+ (1,0) [0|0] "" Vector__XXX
 SG_ DIR_a056_ambientOT : 55|1@1+ (1,0) [0|0] "" Vector__XXX
 SG_ DIR_a055_trqCrossCheck : 54|1@1+ (1,0) [0|0] "" Vector__XXX
 SG_ DIR_a054_driveInverterOT : 53|1@1+ (1,0) [0|0] "" Vector__XXX
 SG_ DIR_a053_unexpectedLatchState : 52|1@1+ (1,0) [0|0] "" Vector__XXX
 SG_ DIR_a052_dirMIA : 51|1@1+ (1,0) [0|0] "" Vector__XXX
 SG_ DIR_a050_noStatorSensor : 49|1@1+ (1,0) [0|0] "" Vector__XXX
 SG_ DIR_a049_statorSensorDiff : 48|1@1+ (1,0) [0|0] "" Vector__XXX
 SG_ DIR_a048_statorSensor2 : 47|1@1+ (1,0) [0|0] "" Vector__XXX
 SG_ DIR_a047_statorSensor1 : 46|1@1+ (1,0) [0|0] "" Vector__XXX
 SG_ DIR_a046_statorOT : 45|1@1+ (1,0) [0|0] "" Vector__XXX
 SG_ DIR_a045_outletSensor : 44|1@1+ (1,0) [0|0] "" Vector__XXX
 SG_ DIR_a044_outletUT : 43|1@1+ (1,0) [0|0] "" Vector__XXX
 SG_ DIR_a043_outletOT : 42|1@1+ (1,0) [0|0] "" Vector__XXX
 SG_ DIR_a042_inletSensor : 41|1@1+ (1,0) [0|0] "" Vector__XXX
 SG_ DIR_a041_sdcMIA : 40|1@1+ (1,0) [0|0] "" Vector__XXX
 SG_ DIR_a040_difMIA : 39|1@1+ (1,0) [0|0] "" Vector__XXX
 SG_ DIR_a038_busVsensor : 37|1@1+ (1,0) [0|0] "" Vector__XXX
 SG_ DIR_a037_busUV : 36|1@1+ (1,0) [0|0] "" Vector__XXX
 SG_ DIR_a036_busOV : 35|1@1+ (1,0) [0|0] "" Vector__XXX
 SG_ DIR_a035_phaseCurrentBalance : 34|1@1+ (1,0) [0|0] "" Vector__XXX
 SG_ DIR_a034_phaseBcurrentSensor : 33|1@1+ (1,0) [0|0] "" Vector__XXX
 SG_ DIR_a033_phaseAcurrentSensor : 32|1@1+ (1,0) [0|0] "" Vector__XXX
 SG_ DIR_a032_phaseBcurrentOffset : 31|1@1+ (1,0) [0|0] "" Vector__XXX
 SG_ DIR_a031_phaseAcurrentOffset : 30|1@1+ (1,0) [0|0] "" Vector__XXX
 SG_ DIR_a030_phaseCrms : 29|1@1+ (1,0) [0|0] "" Vector__XXX
 SG_ DIR_a029_phaseBrms : 28|1@1+ (1,0) [0|0] "" Vector__XXX
 SG_ DIR_a028_phaseArms : 27|1@1+ (1,0) [0|0] "" Vector__XXX
 SG_ DIR_a027_phaseCpeak : 26|1@1+ (1,0) [0|0] "" Vector__XXX
 SG_ DIR_a026_phaseBpeak : 25|1@1+ (1,0) [0|0] "" Vector__XXX
 SG_ DIR_a025_phaseApeak : 24|1@1+ (1,0) [0|0] "" Vector__XXX
 SG_ DIR_a024_selfTest : 23|1@1+ (1,0) [0|0] "" Vector__XXX
 SG_ DIR_a022_hw5vSupplyUV : 21|1@1+ (1,0) [0|0] "" Vector__XXX
 SG_ DIR_a021_hwBusOV : 20|1@1+ (1,0) [0|0] "" Vector__XXX
 SG_ DIR_a020_hwMotorEncoder : 19|1@1+ (1,0) [0|0] "" Vector__XXX
 SG_ DIR_a018_hwLVSupplyUV : 17|1@1+ (1,0) [0|0] "" Vector__XXX
 SG_ DIR_a017_hwPedalMonitor : 16|1@1+ (1,0) [0|0] "" Vector__XXX
 SG_ DIR_a016_safeStateApplied : 15|1@1+ (1,0) [0|0] "" Vector__XXX
 SG_ DIR_a015_mechSafeStateAnomaly : 14|1@1+ (1,0) [0|0] "" Vector__XXX
 SG_ DIR_a014_activeDamping : 13|1@1+ (1,0) [0|0] "" Vector__XXX
 SG_ DIR_a013_eccError : 12|1@1+ (1,0) [0|0] "" Vector__XXX
 SG_ DIR_a011_swPowerStageNotReady : 10|1@1+ (1,0) [0|0] "" Vector__XXX
 SG_ DIR_a010_unintendedReset : 9|1@1+ (1,0) [0|0] "" Vector__XXX
 SG_ DIR_a009_hwEncoderB : 8|1@1+ (1,0) [0|0] "" Vector__XXX
 SG_ DIR_a008_hwEncoderA : 7|1@1+ (1,0) [0|0] "" Vector__XXX
 SG_ DIR_a007_statorAnomalyDetected : 6|1@1+ (1,0) [0|0] "" Vector__XXX
 SG_ DIR_a006_hwPhaseCpeak : 5|1@1+ (1,0) [0|0] "" Vector__XXX
 SG_ DIR_a005_hwPhaseBpeak : 4|1@1+ (1,0) [0|0] "" Vector__XXX
 SG_ DIR_a004_hwPhaseApeak : 3|1@1+ (1,0) [0|0] "" Vector__XXX
 SG_ DIR_a003_hwPhaseCgateDrive : 2|1@1+ (1,0) [0|0] "" Vector__XXX
 SG_ DIR_a002_hwPhaseBgateDrive : 1|1@1+ (1,0) [0|0] "" Vector__XXX
 SG_ DIR_a001_hwPhaseAgateDrive : 0|1@1+ (1,0) [0|0] "" Vector__XXX

BO_ 936 VCLEFT_logging1Hz: 8 Vector__XXX
 SG_ VCLEFT_tpmsCurrent m2 : 61|3@1+ (0.01,0) [0|0] "" Vector__XXX
 SG_ VCLEFT_sideMirrorHeaterCurrent m1 : 60|4@1+ (0.5,0) [0|0] "" Vector__XXX
 SG_ VCLEFT_ocsCurrent m2 : 58|3@1+ (0.01,0) [0|0] "" Vector__XXX
 SG_ VCLEFT_sideMirrorCurrent m1 : 56|4@1+ (0.2,0) [0|0] "" Vector__XXX
 SG_ VCLEFT_vbatFused3Current m2 : 53|5@1+ (0.1,0) [0|0] "" Vector__XXX
 SG_ VCLEFT_dirDischargeCurrent m1 : 52|4@1+ (0.1,0) [0|0] "" Vector__XXX
 SG_ VCLEFT_sccmCurrent m1 : 48|4@1+ (0.05,0) [0|0] "" Vector__XXX
 SG_ VCLEFT_vbatFused0Current m2 : 48|5@1+ (0.1,0) [0|0] "" Vector__XXX
 SG_ VCLEFT_accessoryFeed2Current m2 : 43|5@1+ (0.2,0) [0|0] "" Vector__XXX
 SG_ VCLEFT_frontSeatHeatBackrestPwr m0 : 40|7@1+ (1,0) [0|0] "" Vector__XXX
 SG_ VCLEFT_swcCurrent m1 : 40|8@1+ (0.05,0) [0|0] "" Vector__XXX
 SG_ VCLEFT_accessoryFeed1Current m2 : 37|6@1+ (0.1,0) [0|0] "" Vector__XXX
 SG_ VCLEFT_bleBPillarRearHdlrCurrent m1 : 36|4@1+ (0.05,0) [0|0] "" Vector__XXX
 SG_ VCLEFT_trunkFoldFlatSwLEDCurrent m2 : 34|3@1+ (5,0) [0|0] "" Vector__XXX
 SG_ VCLEFT_usbPortsRearCurrentAvg m4 : 34|10@1+ (0.001,0) [0|0] "" Vector__XXX
 SG_ VCLEFT_frontSeatHeatCushionPwr m0 : 32|7@1+ (1,0) [0|0] "" Vector__XXX
 SG_ VCLEFT_lumbarEcuCurrent m1 : 32|4@1+ (0.1,0) [0|0] "" Vector__XXX
 SG_ VCLEFT_rearPuddleLEDCurrent m2 : 31|3@1+ (2,0) [0|0] "" Vector__XXX
 SG_ VCLEFT_frontPuddleLEDCurrent m2 : 28|3@1+ (2,0) [0|0] "" Vector__XXX
 SG_ VCLEFT_mapPocketLEDsCurrent m2 : 25|3@1+ (10,0) [0|0] "" Vector__XXX
 SG_ VCLEFT_rcmCurrent m1 : 24|7@1+ (0.025,0) [0|0] "" Vector__XXX
 SG_ VCLEFT_rgbLedIPFROutput m3 : 24|1@1+ (1,0) [0|0] "" Vector__XXX
 SG_ VCLEFT_swcResistance m0 : 24|7@1+ (0.025,0) [0|0] "" Vector__XXX
 SG_ VCLEFT_usbPortsCurrentAvg m4 : 24|10@1+ (0.001,0) [0|0] "" Vector__XXX
 SG_ VCLEFT_rgbLedIPFLOutput m3 : 23|1@1+ (1,0) [0|0] "" Vector__XXX
 SG_ VCLEFT_intDoorHandleLEDCurrent m2 : 22|3@1+ (2,0) [0|0] "" Vector__XXX
 SG_ VCLEFT_windowSwitchLEDCurrent m2 : 19|3@1+ (10,0) [0|0] "" Vector__XXX
 SG_ VCLEFT_phoneChargingFR m0 : 17|1@1+ (1,0) [0|0] "" Vector__XXX
 SG_ VCLEFT_phoneChargingFL m0 : 16|1@1+ (1,0) [0|0] "" Vector__XXX
 SG_ VCLEFT_tlcCurrent m1 : 16|6@1+ (0.5,0) [0|0] "" Vector__XXX
 SG_ VCLEFT_trunkInteriorLEDCurrent m2 : 15|4@1+ (5,0) [0|0] "" Vector__XXX
 SG_ VCLEFT_12vSocketRearCurrentAvg m4 : 13|10@1+ (0.01,0) [0|0] "" Vector__XXX
 SG_ VCLEFT_rgbLedIPFRCurrent m3 : 13|10@1+ (0.0004887585532746823,0) [0|0] "" Vector__XXX
 SG_ VCLEFT_stopReverseTurnLightCurrent m2 : 11|4@1+ (0.1,0) [0|0] "" Vector__XXX
 SG_ VCLEFT_chargePortCurrent m1 : 8|6@1+ (0.05,0) [0|0] "" Vector__XXX
 SG_ VCLEFT_tohcPCBATemperature m0 : 8|8@1+ (1,-40) [0|0] "" Vector__XXX
 SG_ VCLEFT_turnTailStopLightCurrent m2 : 7|4@1+ (0.1,0) [0|0] "" Vector__XXX
 SG_ VCLEFT_12vSocketFrontCurrentAvg m4 : 3|10@1+ (0.01,0) [0|0] "" Vector__XXX
 SG_ VCLEFT_rgbLedIPFLCurrent m3 : 3|10@1+ (0.0004887585532746823,0) [0|0] "" Vector__XXX
 SG_ VCLEFT_tailLightCurrent m2 : 3|4@1+ (0.1,0) [0|0] "" Vector__XXX
 SG_ VCLEFT_logging1HzIndex M : 0|3@1+ (1,0) [0|0] "" Vector__XXX

BO_ 942 APP_summonCommand: 8 Vector__XXX
 SG_ APP_summonCommandChecksum : 56|8@1+ (1,0) [0|0] "" Vector__XXX
 SG_ APP_summonCommandCounter : 52|4@1+ (1,0) [0|0] "" Vector__XXX
 SG_ APP_summonState : 49|3@1+ (1,0) [0|0] "" Vector__XXX
 SG_ APP_summonControllerHeartbeat : 46|3@1+ (1,0) [0|0] "" Vector__XXX
 SG_ APP_summonTimeToCollision : 40|6@1+ (0.1,0) [0|0] "" Vector__XXX
 SG_ APP_summonMaxVelocity : 32|8@1+ (0.05,0) [0|0] "" Vector__XXX
 SG_ APP_summonHomelinkCloseCommand : 31|1@1+ (1,0) [0|0] "" Vector__XXX
 SG_ APP_summonInstruction : 28|3@1+ (1,0) [0|0] "" Vector__XXX
 SG_ APP_summonMonitorStopRequest : 26|2@1+ (1,0) [0|0] "" Vector__XXX
 SG_ APP_summonDistance : 16|10@1+ (0.02,0) [0|0] "" Vector__XXX
 SG_ APP_summonHomelinkOpenCommand : 15|1@1+ (1,0) [0|0] "" Vector__XXX
 SG_ APP_summonSteeringAngleRequest : 0|15@1+ (0.1,-1638.35) [0|0] "" Vector__XXX

BO_ 955 UI_power: 3 Vector__XXX
 SG_ UI_dSocAlertThreshold : 17|5@1+ (0.1,-3) [0|0] "" Vector__XXX
 SG_ UI_dSocAlertEnable : 16|1@1+ (1,0) [0|0] "" Vector__XXX
 SG_ UI_powerIdeal : 8|8@1+ (1,0) [0|0] "" Vector__XXX
 SG_ UI_powerExpected : 0|8@1+ (1,0) [0|0] "" Vector__XXX

BO_ 956 UI_tpmsRCPsetting_3BC: 4 Vector__XXX
 SG_ UI_setRCPRear : 24|8@1+ (0.025,0) [0|0] "" Vector__XXX
 SG_ UI_setRCPFront : 16|8@1+ (0.025,0) [0|0] "" Vector__XXX

BO_ 957 VCFRONT_parkedEnergyLoss: 8 Vector__XXX
 SG_ VCFRONT_evapDryingEnergyLossSinceCharge m4 : 50|14@1+ (0.01,0) [0|0] "" Vector__XXX
 SG_ VCFRONT_evapDryingEnergyLossSinceDrive m2 : 50|14@1+ (0.01,0) [0|0] "" Vector__XXX
 SG_ VCFRONT_mobileAppEnergyLossSinceCharge m3 : 50|14@1+ (0.01,0) [0|0] "" Vector__XXX
 SG_ VCFRONT_mobileAppEnergyLossSinceDrive m1 : 50|14@1+ (0.01,0) [0|0] "" Vector__XXX
 SG_ VCFRONT_backgroundEnergyLossSinceCharge m4 : 36|14@1+ (0.01,0) [0|0] "" Vector__XXX
 SG_ VCFRONT_backgroundEnergyLossSinceDrive m2 : 36|14@1+ (0.01,0) [0|0] "" Vector__XXX
 SG_ VCFRONT_cabinOverheatEnergyLossSinceCharge m3 : 36|14@1+ (0.01,0) [0|0] "" Vector__XXX
 SG_ VCFRONT_cabinOverheatEnergyLossSinceDrive m1 : 36|14@1+ (0.01,0) [0|0] "" Vector__XXX
 SG_ VCFRONT_preconditioningEnergyLossSinceCharge m3 : 22|14@1+ (0.01,0) [0|0] "" Vector__XXX
 SG_ VCFRONT_preconditioningEnergyLossSinceDrive m1 : 22|14@1+ (0.01,0) [0|0] "" Vector__XXX
 SG_ VCFRONT_sentryModeEnergyLossSinceCharge m4 : 22|14@1+ (0.01,0) [0|0] "" Vector__XXX
 SG_ VCFRONT_sentryModeEnergyLossSinceDrive m2 : 22|14@1+ (0.01,0) [0|0] "" Vector__XXX
 SG_ VCFRONT_currentEnergyLossReason m0 : 8|3@1+ (1,0) [0|0] "" Vector__XXX
 SG_ VCFRONT_summonStandbyEnergyLossSinceCharge m4 : 8|14@1+ (0.01,0) [0|0] "" Vector__XXX
 SG_ VCFRONT_summonStandbyEnergyLossSinceDrive m2 : 8|14@1+ (0.01,0) [0|0] "" Vector__XXX
 SG_ VCFRONT_userEnergyLossSinceCharge m3 : 8|14@1+ (0.01,0) [0|0] "" Vector__XXX
 SG_ VCFRONT_userEnergyLossSinceDrive m1 : 8|14@1+ (0.01,0) [0|0] "" Vector__XXX
 SG_ VCFRONT_parkedEnergyLossState m0 : 3|3@1+ (1,0) [0|0] "" Vector__XXX
 SG_ VCFRONT_energyLossIndex M : 0|3@1+ (1,0) [0|0] "" Vector__XXX

CM_ BO_ 290 "ESP32-DualCAN Model3_VEH. Seen on this car: 8-byte frames; fit good (bits covered 100%, mux 100%, ranges 100%).";
VAL_ 290 VCLEFT_rearDoorState 0 "UNKNOWN" 1 "CLOSED" 2 "WAIT_FOR_SHORT_DROP" 3 "RELEASING_LATCH" 4 "OPEN" 5 "AJAR" 6 "INIT" ;
VAL_ 290 VCLEFT_frontDoorState 0 "UNKNOWN" 1 "CLOSED" 2 "WAIT_FOR_SHORT_DROP" 3 "RELEASING_LATCH" 4 "OPEN" 5 "AJAR" 6 "INIT" ;
CM_ BO_ 296 "ESP32-DualCAN Model3_VEH. Seen on this car: 6-byte frames; fit ok (bits covered 100%, mux 100%, ranges 100%).";
VAL_ 296 DI_proximity 0 "SNA" 1 "DISCONNECTED" 2 "UNLATCHED" 3 "LATCHED" ;
VAL_ 296 DI_vehicleSpeedLimitReason 0 "NONE" 1 "DRIVE_UNIT_LIMIT" 2 "FACTORY_LOW_BRAKE_FLUID" 3 "FACTORY_MODE" 4 "SERVICE_MODE" 5 "MAX_CAR_CONFIG" 6 "SPINDOWN_LEARNING" 7 "TRAILER_MODE" 8 "TAS" 9 "LOAD_SHED" 10 "FRUNK_OPEN" 11 "USER" ;
VAL_ 296 DI_vehicleSpeedLimit 511 "SNA" ;
VAL_ 296 DI_vehicleSpeedLimitType 0 "NONE" 1 "USER" 2 "POWERTRAIN" ;
CM_ BO_ 313 "ESP32-DualCAN Model3_VEH. Seen on this car: 1-byte frames; fit poor (bits covered 0%, mux 100%, ranges 100%).";
CM_ BO_ 474 "ESP32-DualCAN Model3_VEH. Seen on this car: 8-byte frames; fit good (bits covered 100%, mux 100%, ranges 100%).";
CM_ BO_ 485 "ESP32-DualCAN Model3_VEH. Seen on this car: 8-byte frames; fit good (bits covered 100%, mux 100%, ranges 100%, checksum 100%).";
VAL_ 485 PM_hvilSystemStatus 0 "DISABLED" 1 "OPEN" 2 "CLOSED" 3 "SNA" ;
VAL_ 485 PM_autoparkState 0 "UNAVAILABLE" 1 "STANDBY" 2 "STARTED" 3 "ACTIVE" 4 "COMPLETE" 5 "PAUSED" 6 "ABORTED" 7 "RESUMED" 8 "UNPARK_COMPLETE" 9 "SELFPARK_STARTED" 15 "SNA" ;
VAL_ 485 PM_cruiseState 0 "UNAVAILABLE" 1 "STANDBY" 2 "ENABLED" 3 "STANDSTILL" 4 "OVERRIDE" 5 "FAULT" 6 "PRE_FAULT" 7 "PRE_CANCEL" ;
CM_ BO_ 504 "ESP32-DualCAN Model3_VEH. Seen on this car: 4-byte frames; fit poor (bits covered 0%, mux 100%, ranges 100%).";
VAL_ 504 VCLEFT_DBG_LM_SelfTest_Status 0 "IDLE" 1 "RX" ;
VAL_ 504 VCLEFT_DBG_USS_SelfTest_Status 0 "IDLE" 1 "RX" ;
VAL_ 504 VCLEFT_DBG_Eeprom_ST_Status 0 "IDLE" 1 "RX" ;
VAL_ 504 VCLEFT_DBG_Siren_ST_Status 0 "IDLE" 1 "RX" ;
VAL_ 504 VCLEFT_DBG_LM_Alarm_Status 0 "IDLE" 1 "RX" ;
VAL_ 504 VCLEFT_DBG_USS_Alarm_Status 0 "IDLE" 1 "RX" ;
VAL_ 504 VCLEFT_DBG_Veh_Settings_Status 0 "IDLE" 1 "RX" ;
VAL_ 504 VCLEFT_DBG_SelfTest_Status 0 "IDLE" 1 "RX" ;
VAL_ 504 VCLEFT_DBG_Suspensions_Status 0 "IDLE" 1 "RX" ;
VAL_ 504 VCLEFT_DBG_Window_Status 0 "IDLE" 1 "RX" ;
VAL_ 504 VCLEFT_DBG_Heater_Status 0 "IDLE" 1 "RX" ;
VAL_ 504 VCLEFT_DBG_Air_Cond_Status 0 "IDLE" 1 "RX" ;
VAL_ 504 VCLEFT_DBG_System_Status 0 "IDLE" 1 "RX" ;
CM_ BO_ 506 "ESP32-DualCAN Model3_VEH. Seen on this car: 3-byte frames; fit poor (bits covered 0%, mux 100%, ranges 100%).";
CM_ BO_ 507 "ESP32-DualCAN Model3_VEH. Seen on this car: 8-byte frames; fit weak (bits covered 0%, mux 100%, ranges 100%).";
VAL_ 507 VCLEFT_TLCState_Reverse 0 "OFF_WITHOUT_LOAD" 1 "OFF_WITH_LOAD" 2 "ON_WITHOUT_LOAD" 3 "ON_WITH_LOAD" 4 "FAULT" 5 "SNA" ;
VAL_ 507 VCLEFT_TLCState_Fog 0 "OFF_WITHOUT_LOAD" 1 "OFF_WITH_LOAD" 2 "ON_WITHOUT_LOAD" 3 "ON_WITH_LOAD" 4 "FAULT" 5 "SNA" ;
VAL_ 507 VCLEFT_TLCState_Stop 0 "OFF_WITHOUT_LOAD" 1 "OFF_WITH_LOAD" 2 "ON_WITHOUT_LOAD" 3 "ON_WITH_LOAD" 4 "FAULT" 5 "SNA" ;
VAL_ 507 VCLEFT_TLCState_Tail 0 "OFF_WITHOUT_LOAD" 1 "OFF_WITH_LOAD" 2 "ON_WITHOUT_LOAD" 3 "ON_WITH_LOAD" 4 "FAULT" 5 "SNA" ;
VAL_ 507 VCLEFT_TLCState_RightTurn 0 "OFF_WITHOUT_LOAD" 1 "OFF_WITH_LOAD" 2 "ON_WITHOUT_LOAD" 3 "ON_WITH_LOAD" 4 "FAULT" 5 "SNA" ;
VAL_ 507 VCLEFT_TLCState_LeftTurn 0 "OFF_WITHOUT_LOAD" 1 "OFF_WITH_LOAD" 2 "ON_WITHOUT_LOAD" 3 "ON_WITH_LOAD" 4 "FAULT" 5 "SNA" ;
VAL_ 507 VCLEFT_TLCRightTurnVoltage 255 "SNA" ;
VAL_ 507 VCLEFT_TLCLeftTurnVoltage 255 "SNA" ;
VAL_ 507 VCLEFT_TLCTemperature 4294967168 "SNA" ;
VAL_ 507 VCLEFT_TLCStatusIndex 0 "0" 1 "1" 2 "INVALID" ;
CM_ BO_ 549 "ESP32-DualCAN Model3_VEH. Seen on this car: 4-byte frames; fit ok (bits covered 100%, mux 100%, ranges 100%).";
VAL_ 549 VCRIGHT_icrLVState 0 "OFF" 1 "ON" 2 "GOING_DOWN" 3 "FAULT" ;
VAL_ 549 VCRIGHT_parkLVState 0 "OFF" 1 "ON" 2 "GOING_DOWN" 3 "FAULT" ;
VAL_ 549 VCRIGHT_vehiclePowerStateDBG 0 "INIT" 1 "LOW_POWER_AWAKE" 2 "CONDITIONING" 3 "ACCESSORY" 4 "ACCESSORY_PLUS" 5 "DRIVE" 6 "OTA" 7 "WAIT_FOR_HIGH_POWER" 8 "TURN_ON_LV" 9 "SYSTEM_CHECKS" 10 "LV_ON" 11 "JUMP_START" 12 "LV_SHUTDOWN" 13 "GO_QUIET" 14 "SLEEP_SHUTDOWN" 15 "LOW_POWER_STANDBY" 16 "RESET" ;
VAL_ 549 VCRIGHT_eFuseLockoutStatus 0 "IDLE" 1 "PENDING" 2 "ACTIVE" ;
VAL_ 549 VCRIGHT_lumbarLVState 0 "OFF" 1 "ON" 2 "GOING_DOWN" 3 "FAULT" ;
VAL_ 549 VCRIGHT_rcmLVState 0 "OFF" 1 "ON" 2 "GOING_DOWN" 3 "FAULT" ;
VAL_ 549 VCRIGHT_hvcLVState 0 "OFF" 1 "ON" 2 "GOING_DOWN" 3 "FAULT" ;
VAL_ 549 VCRIGHT_tunerLVState 0 "OFF" 1 "ON" 2 "GOING_DOWN" 3 "FAULT" ;
VAL_ 549 VCRIGHT_premAudioLVState 0 "OFF" 1 "ON" 2 "GOING_DOWN" 3 "FAULT" ;
VAL_ 549 VCRIGHT_ocsLVState 0 "OFF" 1 "ON" 2 "GOING_DOWN" 3 "FAULT" ;
VAL_ 549 VCRIGHT_ptcLVState 0 "OFF" 1 "ON" 2 "GOING_DOWN" 3 "FAULT" ;
CM_ BO_ 554 "ESP32-DualCAN Model3_VEH. Seen on this car: 4-byte frames; fit ok (bits covered 100%, mux 100%, ranges 100%).";
VAL_ 554 HVP_dcLinkVoltageFiltered 4294966746 "SNA" ;
VAL_ 554 HVP_pcsControlRequest 0 "SHUTDOWN" 1 "SUPPORT" 2 "PRECHARGE" 3 "DISCHARGE" ;
CM_ BO_ 555 "ESP32-DualCAN Model3_VEH. Seen on this car: 8-byte frames; fit good (bits covered 100%, mux 100%, ranges 100%).";
CM_ BO_ 562 "ESP32-DualCAN Model3_VEH. Seen on this car: 8-byte frames; fit good (bits covered 100%, mux 100%, ranges 100%).";
CM_ BO_ 564 "ESP32-DualCAN Model3_VEH. Seen on this car: 8-byte frames; fit ok (bits covered 100%, mux 100%, ranges 100%, checksum 0%).";
VAL_ 564 DCDC_type 0 "US_TESLA" 1 "EURO_IEC" 2 "GB" 3 "IEC_CCS" ;
CM_ BO_ 578 "ESP32-DualCAN Model3_VEH. Seen on this car: 4-byte frames; fit ok (bits covered 100%, mux 100%, ranges 100%).";
VAL_ 578 VCLEFT_vehiclePowerStateDBG 0 "INIT" 1 "LOW_POWER_AWAKE" 2 "CONDITIONING" 3 "ACCESSORY" 4 "ACCESSORY_PLUS" 5 "DRIVE" 6 "OTA" 7 "WAIT_FOR_HIGH_POWER" 8 "TURN_ON_LV" 9 "SYSTEM_CHECKS" 10 "LV_ON" 11 "JUMP_START" 12 "LV_SHUTDOWN" 13 "GO_QUIET" 14 "SLEEP_SHUTDOWN" 15 "LOW_POWER_STANDBY" 16 "RESET" ;
VAL_ 578 VCLEFT_lumbarLVState 0 "OFF" 1 "ON" 2 "GOING_DOWN" 3 "FAULT" ;
VAL_ 578 VCLEFT_rcmLVState 0 "OFF" 1 "ON" 2 "GOING_DOWN" 3 "FAULT" ;
CM_ BO_ 630 "ESP32-DualCAN Model3_VEH. Seen on this car: 8-byte frames; fit good (bits covered 100%, mux 100%, ranges 100%).";
CM_ BO_ 633 "ESP32-DualCAN Model3_VEH. Seen on this car: 8-byte frames; fit ok (bits covered 100%, mux 100%, ranges 100%, checksum 0%).";
VAL_ 633 DIR_gateDriveSupplyState 0 "DOWN" 1 "RISING" 2 "UP" 3 "FALLING" ;
VAL_ 633 DIR_gateDriveState 0 "INIT" 1 "SELFTEST" 2 "CONFIGURING" 3 "CONFIGURED" 4 "NOT_CONFIGURED" ;
VAL_ 633 DIR_powerStageSafeState 0 "NONE" 1 "ALL_OFF" 2 "3PS_HIGH" 3 "3PS_LOW" ;
VAL_ 633 DIR_vBatQF 0 "NOT_QUALIFIED" 1 "QUALIFIED" ;
VAL_ 633 DIR_hvilSupplyState 0 "NOT_AVAILABLE" 1 "INACTIVE" 2 "ACTIVE" ;
VAL_ 633 DIR_hvilStatus 0 "DISABLED" 1 "OPEN" 2 "CLOSED" 3 "SNA" ;
CM_ BO_ 643 "ESP32-DualCAN Model3_VEH. Seen on this car: 6-byte frames; fit poor (bits covered 0%, mux 100%, ranges 100%).";
CM_ BO_ 649 "ESP32-DualCAN Model3_VEH. Seen on this car: 8-byte frames; fit good (bits covered 100%, mux 100%, ranges 100%).";
VAL_ 649 VCLEFT_hvacBlowerITerm 127 "SNA" ;
VAL_ 649 VCLEFT_hvacBlowerCBCCtrlState 0 "ERROR" 1 "IDLE" 2 "OFFLINE" 3 "ONLINE" 4 "COUNT" ;
VAL_ 649 VCLEFT_hvacBlowerCBCEstState 0 "ERROR" 1 "IDLE" 2 "ROVERL" 3 "RS" 4 "RAMPUP" 5 "IDRATED" 6 "RATEDFLUX_OL" 7 "RATEDFLUX" 8 "RAMPDOWN" 9 "LOCKROTOR" 10 "INDUCTANCE_EST" 11 "ROTOR_RESISTANCE" 12 "MOTOR_IDENTIFIED" 13 "ONLINE" 14 "COUNT" ;
VAL_ 649 VCLEFT_hvacBlower_IO_CBC_Status 0 "IDLE" 1 "RX" ;
VAL_ 649 VCLEFT_hvacBlowerIPhase2 255 "SNA" ;
VAL_ 649 VCLEFT_hvacBlowerIPhase1 255 "SNA" ;
VAL_ 649 VCLEFT_hvacBlowerIPhase0 255 "SNA" ;
VAL_ 649 VCLEFT_hvacBlowerRs 255 "SNA" ;
VAL_ 649 VCLEFT_logging10HzIndex 0 "Mux0" 1 "Mux1" ;
CM_ BO_ 660 "ESP32-DualCAN Model3_VEH. Seen on this car: 8-byte frames; fit good (bits covered 100%, mux 100%, ranges 100%).";
VAL_ 660 UI_windowRequest 0 "IDLE" 1 "GOTO_PERCENT" 2 "GOTO_VENT" 3 "GOTO_CLOSED" 5 "GOTO_CLOSED_CARWASH" 6 "GOTO_PERCENT_RELATIVE" ;
VAL_ 660 UI_packTempLoggingRequest 0 "FALSE" 1 "TRUE" ;
VAL_ 660 UI_lightFlashRequest 0 "INACTIVE" 1 "HOMELINK" 2 "MOBILE_APP" 3 "SENTRY" ;
CM_ BO_ 661 "ESP32-DualCAN Model3_VEH. Seen on this car: 8-byte frames; fit good (bits covered 100%, mux 100%, ranges 100%).";
CM_ BO_ 667 "ESP32-DualCAN Model3_VEH. Seen on this car: 5-byte frames; fit weak (bits covered 69%, mux 100%, ranges 100%).";
CM_ BO_ 670 "ESP32-DualCAN Model3_VEH. Seen on this car: 8-byte frames; fit good (bits covered 100%, mux 100%, ranges 100%, checksum 100%).";
CM_ BO_ 673 "ESP32-DualCAN Model3_VEH. Seen on this car: 6-byte frames; fit ok (bits covered 100%, mux 100%, ranges 100%).";
CM_ BO_ 674 "ESP32-DualCAN Model3_VEH. Seen on this car: 7-byte frames; fit poor (bits covered 0%, mux 100%, ranges 100%).";
CM_ BO_ 675 "ESP32-DualCAN Model3_VEH. Seen on this car: 8-byte frames; fit good (bits covered 100%, mux 100%, ranges 100%).";
CM_ BO_ 678 "ESP32-DualCAN Model3_VEH. Seen on this car: 8-byte frames; fit good (bits covered 100%, mux 100%, ranges 100%).";
CM_ BO_ 682 "ESP32-DualCAN Model3_VEH. Seen on this car: 3-byte frames; fit ok (bits covered 100%, mux 100%, ranges 100%, checksum 100%).";
CM_ BO_ 701 "ESP32-DualCAN Model3_VEH. Seen on this car: 4-byte frames; fit ok (bits covered 100%, mux 100%, ranges 100%).";
CM_ BO_ 702 "ESP32-DualCAN Model3_VEH. Seen on this car: 8-byte frames; fit good (bits covered 100%, mux 100%, ranges 100%).";
VAL_ 702 FC_minVoltageLimit_value 4294934528 "SNA" ;
VAL_ 702 FC_currentLimit_value 4294934528 "SNA" ;
VAL_ 702 FC_powerLimit_value 4294934528 "SNA" ;
CM_ BO_ 703 "ESP32-DualCAN Model3_VEH. Seen on this car: 8-byte frames; fit good (bits covered 100%, mux 100%, ranges 100%).";
CM_ BO_ 706 "ESP32-DualCAN Model3_VEH. Seen on this car: 8-byte frames; fit good (bits covered 100%, mux 100%, ranges 100%).";
VAL_ 706 VCLEFT_windowPositionStateLR 0 "UNKNOWN" 1 "CLOSED" 2 "CRACKED" 3 "VENT" 4 "PARTIAL_OPEN" 5 "FULL_OPEN" 6 "CLOSED_TRIM_CLEAR" ;
VAL_ 706 VCLEFT_windowPositionStateLF 0 "UNKNOWN" 1 "CLOSED" 2 "CRACKED" 3 "VENT" 4 "PARTIAL_OPEN" 5 "FULL_OPEN" 6 "CLOSED_TRIM_CLEAR" ;
VAL_ 706 VCLEFT_windowCtrlUnavailableLR 0 "NONE" 1 "UNEXPECTED" 2 "SWITCH_PRESSED" 3 "PINCH" 4 "THERMAL_LIMIT" 5 "UNCALIBRATED" 6 "VEHICLE_IN_DRIVE" 7 "WINDOW_MOVING" ;
VAL_ 706 VCLEFT_windowControlStateLR 0 "IDLE" 1 "CLOSING" 2 "GOING_TO_POSITION" ;
VAL_ 706 VCLEFT_windowCtrlUnavailableLF 0 "NONE" 1 "UNEXPECTED" 2 "SWITCH_PRESSED" 3 "PINCH" 4 "THERMAL_LIMIT" 5 "UNCALIBRATED" 6 "VEHICLE_IN_DRIVE" 7 "WINDOW_MOVING" ;
VAL_ 706 VCLEFT_windowControlStateLF 0 "IDLE" 1 "CLOSING" 2 "GOING_TO_POSITION" ;
VAL_ 706 VCLEFT_windowStateLR 0 "STOPPED" 1 "MOVING_UP" 2 "MOVING_DOWN" 3 "BACKOFF" 4 "SHORT_DROP" 5 "SHORT_DROP_REVERSE" 6 "MOVING_AUTO_UP" 7 "MOVING_AUTO_DOWN" 8 "BACKDRIVE" ;
VAL_ 706 VCLEFT_windowStopReqReasonLR 0 "NONE" 1 "SWITCH_CANCEL_AUTO_MOVEMENT" 2 "SWITCH_RELEASED" 3 "REAR_LOCKOUT" 4 "THERMAL" 5 "STALL" 6 "STATE_TIMEOUT" 7 "FULL_OPEN_SOFT_STOP" 8 "EXTERNAL_REQUEST" ;
VAL_ 706 VCLEFT_windowStopReasonLR 0 "NONE" 1 "DOOR_OPEN_TRIM_PROTECT" 2 "NEW_REQUEST" 3 "TARGET_REACHED" 4 "STOP_REQUEST" 5 "FULL_OPEN_SOFT_STOP" 6 "STATE_TIMEOUT" ;
VAL_ 706 VCLEFT_windowThermalModeLR 0 "SNA" 1 "NORMAL" 2 "ALERT" 3 "CRITICAL" ;
VAL_ 706 VCLEFT_windowStopReqReasonLF 0 "NONE" 1 "SWITCH_CANCEL_AUTO_MOVEMENT" 2 "SWITCH_RELEASED" 3 "REAR_LOCKOUT" 4 "THERMAL" 5 "STALL" 6 "STATE_TIMEOUT" 7 "FULL_OPEN_SOFT_STOP" 8 "EXTERNAL_REQUEST" ;
VAL_ 706 VCLEFT_windowStopReasonLF 0 "NONE" 1 "DOOR_OPEN_TRIM_PROTECT" 2 "NEW_REQUEST" 3 "TARGET_REACHED" 4 "STOP_REQUEST" 5 "FULL_OPEN_SOFT_STOP" 6 "STATE_TIMEOUT" ;
VAL_ 706 VCLEFT_windowThermalModeLF 0 "SNA" 1 "NORMAL" 2 "ALERT" 3 "CRITICAL" ;
VAL_ 706 VCLEFT_windowStateLF 0 "STOPPED" 1 "MOVING_UP" 2 "MOVING_DOWN" 3 "BACKOFF" 4 "SHORT_DROP" 5 "SHORT_DROP_REVERSE" 6 "MOVING_AUTO_UP" 7 "MOVING_AUTO_DOWN" 8 "BACKDRIVE" ;
VAL_ 706 VCLEFT_windowStatusIndex 0 "Mux0" 1 "Mux1" ;
CM_ BO_ 707 "ESP32-DualCAN Model3_VEH. Seen on this car: 8-byte frames; fit good (bits covered 100%, mux 100%, ranges 100%).";
VAL_ 707 VCRIGHT_windowPositionStateRR 0 "UNKNOWN" 1 "CLOSED" 2 "CRACKED" 3 "VENT" 4 "PARTIAL_OPEN" 5 "FULL_OPEN" 6 "CLOSED_TRIM_CLEAR" ;
VAL_ 707 VCRIGHT_windowPositionStateRF 0 "UNKNOWN" 1 "CLOSED" 2 "CRACKED" 3 "VENT" 4 "PARTIAL_OPEN" 5 "FULL_OPEN" 6 "CLOSED_TRIM_CLEAR" ;
VAL_ 707 VCRIGHT_windowCtrlUnavailableRR 0 "NONE" 1 "UNEXPECTED" 2 "SWITCH_PRESSED" 3 "PINCH" 4 "THERMAL_LIMIT" 5 "UNCALIBRATED" 6 "VEHICLE_IN_DRIVE" 7 "WINDOW_MOVING" ;
VAL_ 707 VCRIGHT_windowControlStateRR 0 "IDLE" 1 "CLOSING" 2 "GOING_TO_POSITION" ;
VAL_ 707 VCRIGHT_windowCtrlUnavailableRF 0 "NONE" 1 "UNEXPECTED" 2 "SWITCH_PRESSED" 3 "PINCH" 4 "THERMAL_LIMIT" 5 "UNCALIBRATED" 6 "VEHICLE_IN_DRIVE" 7 "WINDOW_MOVING" ;
VAL_ 707 VCRIGHT_windowControlStateRF 0 "IDLE" 1 "CLOSING" 2 "GOING_TO_POSITION" ;
VAL_ 707 VCRIGHT_windowStateRR 0 "STOPPED" 1 "MOVING_UP" 2 "MOVING_DOWN" 3 "BACKOFF" 4 "SHORT_DROP" 5 "SHORT_DROP_REVERSE" 6 "MOVING_AUTO_UP" 7 "MOVING_AUTO_DOWN" 8 "BACKDRIVE" ;
VAL_ 707 VCRIGHT_windowStopReqReasonRR 0 "NONE" 1 "SWITCH_CANCEL_AUTO_MOVEMENT" 2 "SWITCH_RELEASED" 3 "REAR_LOCKOUT" 4 "THERMAL" 5 "STALL" 6 "STATE_TIMEOUT" 7 "FULL_OPEN_SOFT_STOP" 8 "EXTERNAL_REQUEST" ;
VAL_ 707 VCRIGHT_windowStopReasonRR 0 "NONE" 1 "DOOR_OPEN_TRIM_PROTECT" 2 "NEW_REQUEST" 3 "TARGET_REACHED" 4 "STOP_REQUEST" 5 "FULL_OPEN_SOFT_STOP" 6 "STATE_TIMEOUT" ;
VAL_ 707 VCRIGHT_windowThermalModeRR 0 "SNA" 1 "NORMAL" 2 "ALERT" 3 "CRITICAL" ;
VAL_ 707 VCRIGHT_windowStopReqReasonRF 0 "NONE" 1 "SWITCH_CANCEL_AUTO_MOVEMENT" 2 "SWITCH_RELEASED" 3 "REAR_LOCKOUT" 4 "THERMAL" 5 "STALL" 6 "STATE_TIMEOUT" 7 "FULL_OPEN_SOFT_STOP" 8 "EXTERNAL_REQUEST" ;
VAL_ 707 VCRIGHT_windowStopReasonRF 0 "NONE" 1 "DOOR_OPEN_TRIM_PROTECT" 2 "NEW_REQUEST" 3 "TARGET_REACHED" 4 "STOP_REQUEST" 5 "FULL_OPEN_SOFT_STOP" 6 "STATE_TIMEOUT" ;
VAL_ 707 VCRIGHT_windowThermalModeRF 0 "SNA" 1 "NORMAL" 2 "ALERT" 3 "CRITICAL" ;
VAL_ 707 VCRIGHT_windowStateRF 0 "STOPPED" 1 "MOVING_UP" 2 "MOVING_DOWN" 3 "BACKOFF" 4 "SHORT_DROP" 5 "SHORT_DROP_REVERSE" 6 "MOVING_AUTO_UP" 7 "MOVING_AUTO_DOWN" 8 "BACKDRIVE" ;
VAL_ 707 VCRIGHT_windowStatusIndex 0 "Mux0" 1 "Mux1" ;
CM_ BO_ 711 "ESP32-DualCAN Model3_VEH. Seen on this car: 8-byte frames; fit good (bits covered 100%, mux 100%, ranges 100%).";
CM_ BO_ 727 "ESP32-DualCAN Model3_VEH. Seen on this car: 4-byte frames; fit ok (bits covered 100%, mux 100%, ranges 100%).";
VAL_ 727 VCLEFT_pitchEstimate 4294967232 "SNA" ;
CM_ BO_ 728 "ESP32-DualCAN Model3_VEH. Seen on this car: 2-byte frames; fit poor (bits covered 0%, mux 100%, ranges 100%).";
VAL_ 728 ICR_nmWakeUpReason 0 "NONE" 1 "CAN_VEH" 2 "CAN_HVS" 3 "WANTTOCHARGE" 4 "CRITICALALERT" 5 "WANTTOWARM" ;
VAL_ 728 ICR_nmKeepAwakeReason 0 "NONE_SNA" 1 "CTRS_CLOSED" 2 "CRITICAL_ALERT" 3 "FC_CTR_CLEANING" 4 "HVP_ACTIVE" 5 "BMS_ACTIVE" 6 "CP_ACTIVE" ;
CM_ BO_ 738 "ESP32-DualCAN Model3_VEH. Seen on this car: 8-byte frames; fit good (bits covered 100%, mux 100%, ranges 100%).";
VAL_ 738 VCLEFT_frontSeatHeatTmpTarget 0 "OFF" ;
VAL_ 738 VCLEFT_frontSeatHeatTmp 0 "SNA" ;
VAL_ 738 VCLEFT_seatStatus2Index 0 "SEAT_HEAT_FRONT" 1 "SEAT_HEAT_REARL_BACKREST" 2 "OCCUPANCY" 3 "SEAT_HEAT_REARL" 4 "SEAT_HEAT_REARC" 5 "SEAT_HEAT_REARR_CUSHION" 6 "SEAT_2ROW_ACTUATOR" 7 "SEAT_SWITCH_VOLTAGES_1" 8 "SEAT_SWITCH_VOLTAGES_2" 9 "SEAT_2ROW_EASY_ENTRY" 10 "SEAT_STATUS_2_INDEX_COUNT" ;
CM_ BO_ 739 "ESP32-DualCAN Model3_VEH. Seen on this car: 7-byte frames; fit ok (bits covered 100%, mux 100%, ranges 100%).";
VAL_ 739 VCRIGHT_frontSeatHeatTmpTarget 0 "OFF" ;
VAL_ 739 VCRIGHT_frontSeatHeatTmp 0 "SNA" ;
VAL_ 739 VCRIGHT_seatStatus2Index 0 "SEAT_HEAT_FRONT" 1 "SEAT_HEAT_REARL_CUSHION" 2 "SEAT_HEAT_REARC" 3 "SEAT_HEAT_REARR" 4 "OCCUPANCY" 5 "SEAT_HEAT_REARR_BACKREST" 6 "SEAT_2ROW_ACTUATOR" 7 "SEAT_SWITCH_VOLTAGES_1" 8 "SEAT_SWITCH_VOLTAGES_2" 9 "SEAT_2ROW_EASY_ENTRY" 10 "OCS_IEE" 11 "SEAT_STATUS_2_INDEX_COUNT" ;
CM_ BO_ 748 "ESP32-DualCAN Model3_VEH. Seen on this car: 3-byte frames; fit ok (bits covered 100%, mux 100%, ranges 100%, checksum 100%).";
CM_ BO_ 761 "ESP32-DualCAN Model3_VEH. Seen on this car: 8-byte frames; fit good (bits covered 100%, mux 100%, ranges 100%).";
VAL_ 761 VCSEC_AdditionalAuthInfoIndex 0 "ACTIVE_KEY_SHA1" 1 "KEY_WITH_IN_SUMMON_RANGE_0" 2 "KEY_WITH_IN_SUMMON_RANGE_1" 3 "KEY_WITH_IN_SUMMON_RANGE_2" 4 "UNKNOWN_BLE_DEVICE_WITH_IN_SUMMON_RANGE" 5 "WALKUP_UNLOCK_BEHAVIOR" ;
VAL_ 761 VCSEC_activeKeyReason 0 "NONE" 1 "NFC_AUTH" 2 "RKE_AUTH" 3 "BLE_DEVICE_CLOSEST_TO_DOOR" 4 "RKE_ACTION" 5 "ONLY_AUTHED_DEVICE" 6 "AUTO_PRESENT_DOOR_COMMAND" ;
VAL_ 761 VCSEC_bleDisconnectionReason 0 "UNKNOWN_REASON_0" 5 "AUTHENTICATION_FAILURE" 8 "CONNECTION_SUPERVISION_TIMEOUT" 19 "REMOTE_USER_TERMINATED" 20 "REMOTE_DEVICE_LOW_RESOURCES" 21 "REMOTE_DEVICE_POWER_OFF" 22 "HOST_REQUESTED_TERMINATION" 26 "UNSUPPORTED_REMOTE_FEATURE" 34 "CONTROL_PACKET_TIMEOUT" 40 "CONTROL_PACKET_INSTANT_PASSED" 41 "KEY_PAIRING_NOT_SUPPORTED" 59 "UNACCEPTABLE_CONNECTION_INTERVAL" 61 "MIC_FAILURE" 62 "CONNECTION_FAILED_TO_ESTABLISH" 255 "UNKNOWN_REASON_FF" ;
CM_ BO_ 803 "ESP32-DualCAN Model3_VEH. Seen on this car: 5-byte frames; fit ok (bits covered 100%, mux 100%, ranges 100%).";
CM_ BO_ 804 "ESP32-DualCAN Model3_VEH. Seen on this car: 8-byte frames; fit good (bits covered 100%, mux 100%, ranges 100%).";
CM_ BO_ 829 "ESP32-DualCAN Model3_VEH. Seen on this car: 8-byte frames; fit weak (bits covered 0%, mux 100%, ranges 100%).";
CM_ BO_ 835 "ESP32-DualCAN Model3_VEH. Seen on this car: 8-byte frames; fit good (bits covered 100%, mux 100%, ranges 100%).";
VAL_ 835 VCRIGHT_mirrorHeatState 0 "SNA" 1 "ON" 2 "OFF" 3 "OFF_UNAVAILABLE" 4 "FAULT" ;
CM_ BO_ 836 "ESP32-DualCAN Model3_VEH. Seen on this car: 8-byte frames; fit good (bits covered 100%, mux 100%, ranges 100%, checksum 100%).";
CM_ BO_ 842 "ESP32-DualCAN Model3_VEH. Seen on this car: 8-byte frames; fit good (bits covered 100%, mux 100%, ranges 100%).";
CM_ BO_ 853 "ESP32-DualCAN Model3_VEH. Seen on this car: 7-byte frames; fit ok (bits covered 100%, mux 100%, ranges 100%).";
CM_ BO_ 863 "ESP32-DualCAN Model3_VEH. Seen on this car: 1-byte frames; fit poor (bits covered 0%, mux 100%, ranges 100%).";
CM_ BO_ 865 "ESP32-DualCAN Model3_VEH. Seen on this car: 5-byte frames; fit ok (bits covered 100%, mux 100%, ranges 100%).";
CM_ BO_ 866 "ESP32-DualCAN Model3_VEH. Seen on this car: 3-byte frames; fit poor (bits covered 0%, mux 100%, ranges 100%).";
VAL_ 866 VCLEFT_crashState 0 "IDLE" 1 "MINOR_1" 2 "MINOR_2" 3 "SEVERE" ;
VAL_ 866 VCLEFT_crashDetectedType 0 "NONE" 1 "MINOR_1" 2 "MINOR_2" 3 "SEVERE" ;
CM_ BO_ 868 "ESP32-DualCAN Model3_VEH. Seen on this car: 4-byte frames; fit ok (bits covered 100%, mux 100%, ranges 100%).";
CM_ BO_ 870 "ESP32-DualCAN Model3_VEH. Seen on this car: 8-byte frames; fit ok (bits covered 100%, mux 100%, ranges 100%).";
VAL_ 870 CMPD_infoAssemblyId 1 "ASSEMBLY1" 255 "ASSEMBLY_SNA" ;
VAL_ 870 CMPD_infoBuildType 0 "UNKNOWN_BUILD" 1 "PLATFORM_BUILD" 2 "LOCAL_BUILD" 3 "TRACEABLE_CI_BUILD" 4 "MFG_BUILD" ;
VAL_ 870 CMPD_infoIndex 0 "DEPRECATED_0" 1 "DEPRECATED_1" 2 "DEPRECATED_2" 3 "DEPRECATED_3" 4 "DEPRECATED_4" 5 "DEPRECATED_5" 6 "DEPRECATED_6" 7 "DEPRECATED_7" 8 "DEPRECATED_8" 9 "DEPRECATED_9" 10 "BUILD_HWID_COMPONENTID" 11 "PCBAID_ASSYID_USAGEID" 13 "APP_CRC" 14 "BOOTLOADER_SVN" 15 "BOOTLOADER_CRC" 16 "SUBCOMPONENT" 17 "APP_GITHASH" 18 "BOOTLOADER_GITHASH" 19 "VERSION_DEPRECATED" 20 "UDS_PROTOCOL_BOOTCRC" 22 "VARIANTCRC" 25 "PACKAGE_PN_1_7" 26 "PACKAGE_PN_8_14" 27 "PACKAGE_PN_15_20" 29 "PACKAGE_SN_1_7" 30 "PACKAGE_SN_8_14" 31 "SUBCOMPONENT_GITHASH" 255 "END" ;
CM_ BO_ 893 "ESP32-DualCAN Model3_VEH. Seen on this car: 8-byte frames; fit good (bits covered 100%, mux 100%, ranges 100%).";
VAL_ 893 CP_thermalStatusSelect 0 "0" 1 "1" ;
CM_ BO_ 898 "ESP32-DualCAN Model3_VEH. Seen on this car: 5-byte frames; fit ok (bits covered 100%, mux 100%, ranges 100%).";
CM_ BO_ 902 "ESP32-DualCAN Model3_VEH. Seen on this car: 8-byte frames; fit ok (bits covered 67%, mux 100%, ranges 100%).";
CM_ BO_ 906 "ESP32-DualCAN Model3_VEH. Seen on this car: 8-byte frames; fit good (bits covered 100%, mux 100%, ranges 100%).";
CM_ BO_ 907 "ESP32-DualCAN Model3_VEH. Seen on this car: 8-byte frames; fit good (bits covered 100%, mux 100%, ranges 100%, checksum 100%).";
CM_ BO_ 912 "ESP32-DualCAN Model3_VEH. Seen on this car: 2-byte frames; fit poor (bits covered 0%, mux 100%, ranges 100%).";
CM_ BO_ 919 "ESP32-DualCAN Model3_VEH. Seen on this car: 8-byte frames; fit good (bits covered 100%, mux 100%, ranges 100%).";
CM_ BO_ 922 "ESP32-DualCAN Model3_VEH. Seen on this car: 8-byte frames; fit good (bits covered 100%, mux 100%, ranges 100%).";
VAL_ 922 VCSEC_RSSI2ConnectionType 0 "NONE" 1 "PERIPHERAL" 2 "CENTRAL" ;
VAL_ 922 VCSEC_RSSI1ConnectionType 0 "NONE" 1 "PERIPHERAL" 2 "CENTRAL" ;
VAL_ 922 VCSEC_RSSI0ConnectionType 0 "NONE" 1 "PERIPHERAL" 2 "CENTRAL" ;
CM_ BO_ 931 "ESP32-DualCAN Model3_VEH. Seen on this car: 8-byte frames; fit good (bits covered 100%, mux 100%, ranges 100%).";
CM_ BO_ 935 "ESP32-DualCAN Model3_VEH. Seen on this car: 8-byte frames; fit good (bits covered 100%, mux 100%, ranges 100%).";
CM_ BO_ 936 "ESP32-DualCAN Model3_VEH. Seen on this car: 8-byte frames; fit good (bits covered 100%, mux 100%, ranges 100%).";
VAL_ 936 VCLEFT_logging1HzIndex 0 "HVAC_ACTUATOR_VOLTAGES" 1 "HVAC_ACTUATOR_ENDSTOP" 2 "HVAC_ACTUATOR_ZEROSTOP" 3 "HVAC_ACTUATOR_OPERATION_MODE" 4 "END" ;
CM_ BO_ 942 "ESP32-DualCAN Model3_VEH. Seen on this car: 8-byte frames; fit ok (bits covered 100%, mux 100%, ranges 100%, checksum 0%).";
VAL_ 942 APP_summonState 0 "INIT" 1 "IDLE" 2 "ARMED" 3 "ACTIVE" 4 "COMPLETE" 5 "FAULT" 6 "UNAVAILABLE" ;
CM_ BO_ 955 "ESP32-DualCAN Model3_VEH. Seen on this car: 3-byte frames; fit poor (bits covered 0%, mux 100%, ranges 100%).";
CM_ BO_ 956 "ESP32-DualCAN Model3_VEH. Seen on this car: 4-byte frames; fit poor (bits covered 0%, mux 100%, ranges 100%).";
CM_ BO_ 957 "ESP32-DualCAN Model3_VEH. Seen on this car: 8-byte frames; fit good (bits covered 100%, mux 100%, ranges 100%).";
VAL_ 957 VCFRONT_energyLossIndex 0 "STATUS" 1 "SINCE_LAST_DRIVE" 2 "SINCE_LAST_DRIVE2" 3 "SINCE_LAST_CHARGE" 4 "SINCE_LAST_CHARGE2" ;
